VERSION ""

NS_ :

BS_:

BU_: AHCP APM BPCM EAC EBCM ECM ESC HCP OBCM ORC RHSC2

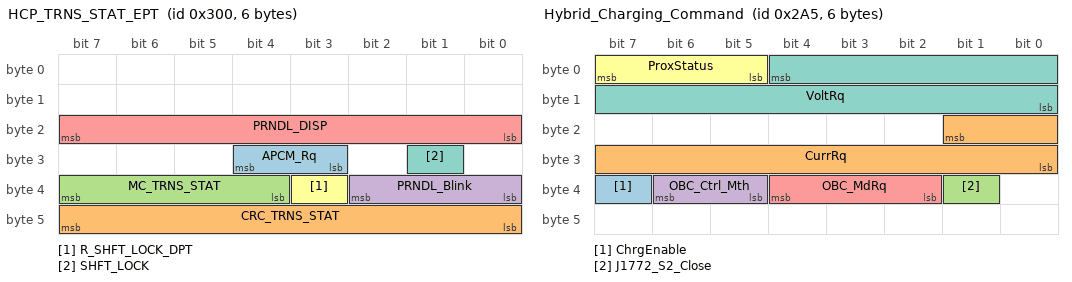
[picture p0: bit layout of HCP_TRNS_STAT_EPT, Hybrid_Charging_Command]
BO_ 768 HCP_TRNS_STAT_EPT: 6 HCP
 SG_ APCM_Rq : 27|2@1+ (1,0) [0|0] ""  RHSC2
 SG_ CRC_TRNS_STAT : 40|8@1+ (1,0) [0|0] ""  RHSC2
 SG_ MC_TRNS_STAT : 36|4@1+ (1,0) [0|15] ""  RHSC2
 SG_ PRNDL_Blink : 32|3@1+ (1,0) [0|0] ""  RHSC2
 SG_ PRNDL_DISP : 16|8@1+ (1,0) [0|0] ""  RHSC2
 SG_ R_SHFT_LOCK_DPT : 35|1@1+ (1,0) [0|0] ""  RHSC2
 SG_ SHFT_LOCK : 25|1@1+ (1,0) [0|0] ""  RHSC2

BO_ 677 Hybrid_Charging_Command: 6 HCP
 SG_ ChrgEnable : 39|1@1+ (1,0) [0|0] ""  OBCM
 SG_ CurrRq : 17|10@0+ (0.1,-32) [-32|31.5] "A"  OBCM
 SG_ J1772_S2_Close : 33|1@1+ (1,0) [0|0] ""  OBCM
 SG_ OBC_Ctrl_Mth : 37|2@1+ (1,0) [0|0] ""  OBCM
 SG_ OBC_MdRq : 34|3@1+ (1,0) [0|0] ""  BPCM,OBCM
 SG_ ProxStatus : 5|3@1+ (1,0) [0|0] ""  BPCM
 SG_ VoltRq : 4|13@0+ (0.1,0) [0|511] "Volts"  OBCM

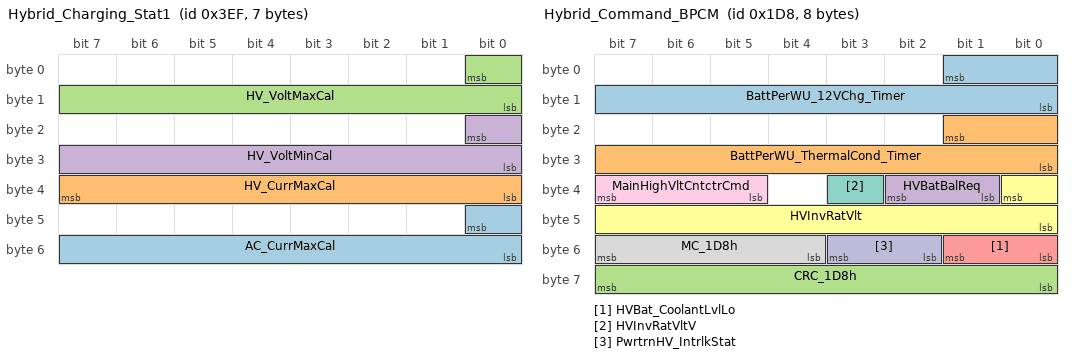
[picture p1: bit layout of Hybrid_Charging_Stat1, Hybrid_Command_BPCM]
BO_ 1007 Hybrid_Charging_Stat1: 7 HCP
 SG_ AC_CurrMaxCal : 40|9@0+ (0.25,-31.5) [-31.5|50] "Amp"  OBCM
 SG_ HV_CurrMaxCal : 32|8@1+ (0.25,-32) [-32|31.5] "Amp"  OBCM
 SG_ HV_VoltMaxCal : 0|9@0+ (1,0) [0|510] "V"  OBCM
 SG_ HV_VoltMinCal : 16|9@0+ (1,0) [0|510] "V"  OBCM

BO_ 472 Hybrid_Command_BPCM: 8 HCP
 SG_ BattPerWU_12VChg_Timer : 1|10@0+ (1,0) [0|1022] "Hours"  BPCM
 SG_ BattPerWU_ThermalCond_Timer : 17|10@0+ (2,0) [0|2044] "min"  BPCM
 SG_ CRC_1D8h : 56|8@1+ (1,0) [0|0] ""  BPCM
 SG_ HVBatBalReq : 33|2@1+ (1,0) [0|0] ""  BPCM
 SG_ HVBat_CoolantLvlLo : 48|2@1+ (1,0) [0|0] ""  BPCM
 SG_ HVInvRatVlt : 32|9@0+ (1,0) [0|510] "V"  BPCM
 SG_ HVInvRatVltV : 35|1@1+ (1,0) [0|0] ""  BPCM
 SG_ MC_1D8h : 52|4@1+ (1,0) [0|0] ""  BPCM
 SG_ MainHighVltCntctrCmd : 37|3@1+ (1,0) [0|0] ""  BPCM,RHSC2
 SG_ PwrtrnHV_IntrlkStat : 50|2@1+ (1,0) [0|0] "" Vector__XXX

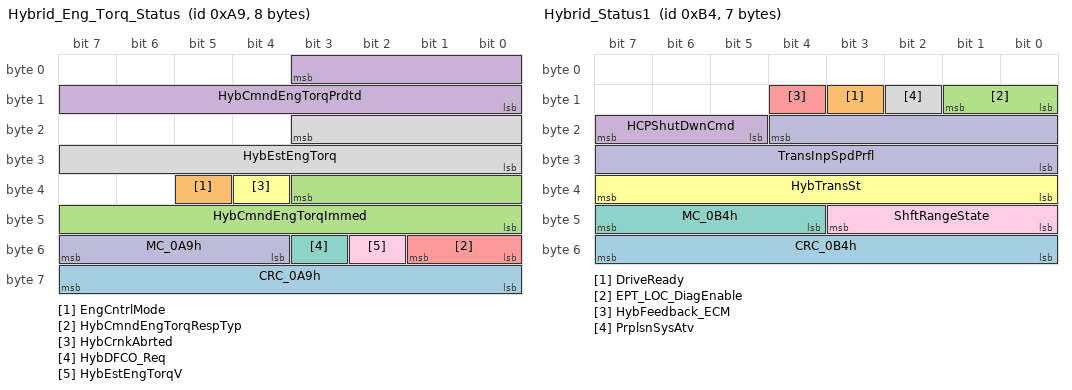
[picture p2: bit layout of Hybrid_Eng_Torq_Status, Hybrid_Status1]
BO_ 169 Hybrid_Eng_Torq_Status: 8 HCP
 SG_ CRC_0A9h : 56|8@1+ (1,0) [0|0] ""  ECM
 SG_ EngCntrlMode : 37|1@1+ (1,0) [0|0] ""  ECM
 SG_ HybCmndEngTorqImmed : 35|12@0+ (0.32,-300.16) [-300.16|1008] "Nm"  ECM
 SG_ HybCmndEngTorqPrdtd : 3|12@0+ (0.32,-300.16) [-300.16|1008] "Nm"  ECM
 SG_ HybCmndEngTorqRespTyp : 48|2@1+ (1,0) [0|0] ""  ECM
 SG_ HybCrnkAbrted : 36|1@1+ (1,0) [0|0] ""  ECM
 SG_ HybDFCO_Req : 51|1@1+ (1,0) [0|0] ""  ECM
 SG_ HybEstEngTorq : 19|12@0+ (0.32,-300.16) [-300.16|1008] "Nm"  ECM
 SG_ HybEstEngTorqV : 50|1@1+ (1,0) [0|0] ""  ECM
 SG_ MC_0A9h : 52|4@1+ (1,0) [0|15] ""  ECM

BO_ 180 Hybrid_Status1: 7 HCP
 SG_ CRC_0B4h : 48|8@1+ (1,0) [0|0] ""  AHCP,APM,BPCM,EAC,EBCM,ECM,ESC,OBCM,ORC,RHSC2
 SG_ DriveReady : 11|1@1+ (1,0) [0|0] ""  BPCM
 SG_ EPT_LOC_DiagEnable : 8|2@1+ (1,0) [0|0] ""  AHCP,APM,BPCM,EAC,OBCM
 SG_ HCPShutDwnCmd : 21|3@1+ (1,0) [0|0] ""  AHCP,APM,BPCM,EAC,EBCM,ECM,ESC,OBCM,ORC,RHSC2
 SG_ HybFeedback_ECM : 12|1@1+ (1,0) [0|0] ""  ECM
 SG_ HybTransSt : 32|8@1+ (1,0) [0|0] ""  ECM
 SG_ MC_0B4h : 44|4@1+ (1,0) [0|15] ""  AHCP,APM,BPCM,EAC,EBCM,ECM,ESC,OBCM,ORC,RHSC2
 SG_ PrplsnSysAtv : 10|1@1+ (1,0) [0|0] ""  AHCP,APM,BPCM,EAC,ECM,OBCM
 SG_ ShftRangeState : 40|4@1+ (1,0) [0|0] ""  ECM
 SG_ TransInpSpdPrfl : 20|13@0+ (1,0) [0|8191] "rpm"  ECM

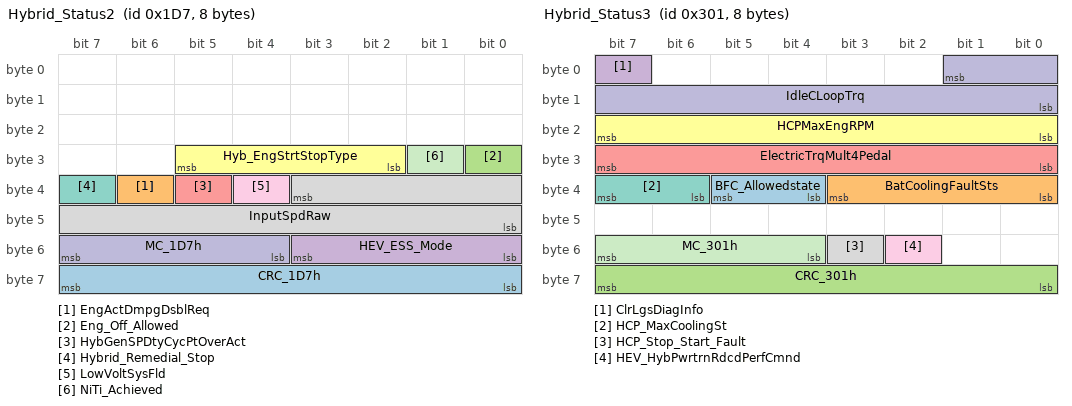
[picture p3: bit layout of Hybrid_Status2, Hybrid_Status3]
BO_ 471 Hybrid_Status2: 8 HCP
 SG_ CRC_1D7h : 56|8@1+ (1,0) [0|0] ""  ECM
 SG_ EngActDmpgDsblReq : 38|1@1+ (1,0) [0|0] ""  ECM
 SG_ Eng_Off_Allowed : 24|1@1+ (1,0) [0|0] ""  ECM
 SG_ HEV_ESS_Mode : 48|4@1+ (1,0) [0|0] ""  ECM
 SG_ HybGenSPDtyCycPtOverAct : 37|1@1+ (1,0) [0|0] ""  ECM
 SG_ Hyb_EngStrtStopType : 26|4@1+ (1,0) [0|0] ""  ECM
 SG_ Hybrid_Remedial_Stop : 39|1@1+ (1,0) [0|0] ""  ECM
 SG_ InputSpdRaw : 35|12@0+ (1,-2048) [-2048|2046] "rpm"  ECM
 SG_ LowVoltSysFld : 36|1@1+ (1,0) [0|0] ""  ECM
 SG_ MC_1D7h : 52|4@1+ (1,0) [0|15] ""  ECM
 SG_ NiTi_Achieved : 25|1@1+ (1,0) [0|0] ""  ECM

BO_ 769 Hybrid_Status3: 8 HCP
 SG_ BFC_Allowedstate : 36|2@1+ (1,0) [0|0] ""  RHSC2
 SG_ BatCoolingFaultSts : 32|4@1+ (1,0) [0|0] ""  RHSC2
 SG_ CRC_301h : 56|8@1+ (1,0) [0|255] ""  ECM,RHSC2
 SG_ ClrLgsDiagInfo : 7|1@1+ (1,0) [0|0] ""  OBCM
 SG_ ElectricTrqMult4Pedal : 24|8@1+ (0.0078125,-0.9921875) [-0.9921875|0.9921875] ""  ECM
 SG_ HCPMaxEngRPM : 16|8@1+ (32,0) [0|8128] "rpm" Vector__XXX
 SG_ HCP_MaxCoolingSt : 38|2@1+ (1,0) [0|0] ""  RHSC2
 SG_ HCP_Stop_Start_Fault : 51|1@1+ (1,0) [0|0] ""  ECM
 SG_ HEV_HybPwrtrnRdcdPerfCmnd : 50|1@1+ (1,0) [0|0] ""  ECM
 SG_ IdleCLoopTrq : 1|10@0+ (0.32,-163.52) [-163.52|163.52] "Nm"  ECM
 SG_ MC_301h : 52|4@1+ (1,0) [0|15] ""  ECM,RHSC2

BO_ 276 IMMO_SOP_REQUEST: 1 HCP
 SG_ IMMO_SOP_REQUEST : 0|1@1+ (1,0) [0|0] ""  ECM

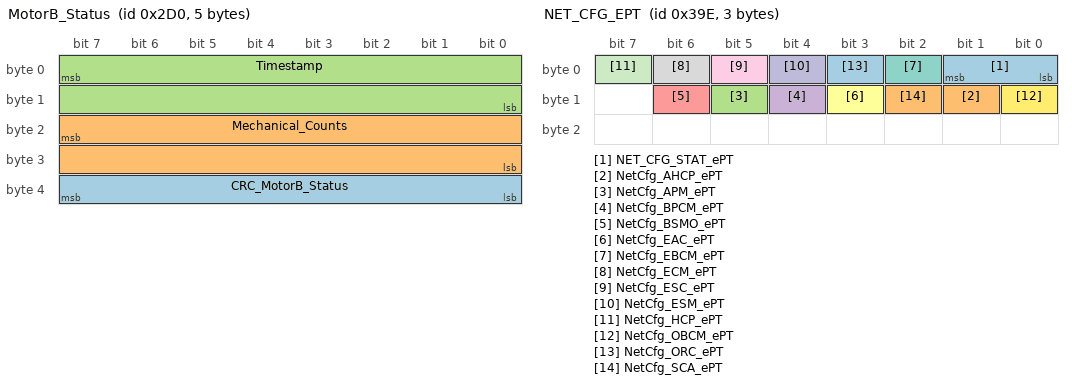
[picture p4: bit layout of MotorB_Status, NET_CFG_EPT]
BO_ 720 MotorB_Status: 5 HCP
 SG_ CRC_MotorB_Status : 32|8@1+ (1,0) [0|0] ""  RHSC2
 SG_ Mechanical_Counts : 23|16@0+ (0.00048828125,0) [0|31.999511719] "Revs"  RHSC2
 SG_ Timestamp : 7|16@0+ (1.969,0) [0|129038.415] "uSec"  RHSC2

BO_ 926 NET_CFG_EPT: 3 HCP
 SG_ NET_CFG_STAT_ePT : 0|2@1+ (1,0) [0|0] ""  AHCP,APM,BPCM,EAC,OBCM
 SG_ NetCfg_AHCP_ePT : 9|1@1+ (1,0) [0|0] "" Vector__XXX
 SG_ NetCfg_APM_ePT : 13|1@1+ (1,0) [0|0] "" Vector__XXX
 SG_ NetCfg_BPCM_ePT : 12|1@1+ (1,0) [0|0] ""  BPCM
 SG_ NetCfg_BSMO_ePT : 14|1@1+ (1,0) [0|0] "" Vector__XXX
 SG_ NetCfg_EAC_ePT : 11|1@1+ (1,0) [0|0] "" Vector__XXX
 SG_ NetCfg_EBCM_ePT : 2|1@1+ (1,0) [0|0] "" Vector__XXX
 SG_ NetCfg_ECM_ePT : 6|1@1+ (1,0) [0|0] "" Vector__XXX
 SG_ NetCfg_ESC_ePT : 5|1@1+ (1,0) [0|0] "" Vector__XXX
 SG_ NetCfg_ESM_ePT : 4|1@1+ (1,0) [0|0] "" Vector__XXX
 SG_ NetCfg_HCP_ePT : 7|1@1+ (1,0) [0|0] "" Vector__XXX
 SG_ NetCfg_OBCM_ePT : 8|1@1+ (1,0) [0|0] "" Vector__XXX
 SG_ NetCfg_ORC_ePT : 3|1@1+ (1,0) [0|0] "" Vector__XXX
 SG_ NetCfg_SCA_ePT : 10|1@1+ (1,0) [0|0] "" Vector__XXX

BO_ 1066 NM_APM: 8 APM
 SG_ NM_APM : 7|64@0+ (1,0) [0|0] ""  OBCM

BO_ 1070 NM_OBCM: 8 OBCM
 SG_ NM_OBCM : 7|64@0+ (1,0) [0|0] ""  APM

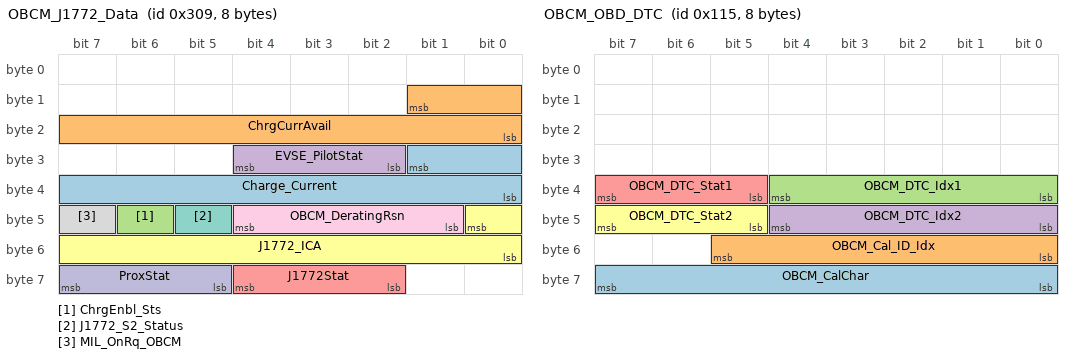
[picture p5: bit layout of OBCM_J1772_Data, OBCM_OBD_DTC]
BO_ 777 OBCM_J1772_Data: 8 OBCM
 SG_ Charge_Current : 25|10@0+ (0.1,0) [0|63.5] "Amp"  HCP
 SG_ ChrgCurrAvail : 9|10@0+ (0.1,0) [0|63.5] "Amp"  HCP
 SG_ ChrgEnbl_Sts : 46|1@1+ (1,0) [0|0] ""  HCP
 SG_ EVSE_PilotStat : 26|3@1+ (1,0) [0|0] ""  HCP
 SG_ J1772Stat : 58|3@1+ (1,0) [0|0] ""  HCP
 SG_ J1772_ICA : 40|9@0+ (1,0) [0|300] "Amp"  HCP
 SG_ J1772_S2_Status : 45|1@1+ (1,0) [0|0] ""  HCP
 SG_ MIL_OnRq_OBCM : 47|1@1+ (1,0) [0|0] ""  ECM
 SG_ OBCM_DeratingRsn : 41|4@1+ (1,0) [0|0] ""  HCP
 SG_ ProxStat : 61|3@1+ (1,0) [0|0] ""  HCP

BO_ 277 OBCM_OBD_DTC: 8 OBCM
 SG_ OBCM_CalChar : 56|8@1+ (1,0) [0|254] ""  HCP
 SG_ OBCM_Cal_ID_Idx : 48|6@1+ (1,0) [0|62] ""  HCP
 SG_ OBCM_DTC_Idx1 : 32|5@1+ (1,0) [1|31] ""  HCP
 SG_ OBCM_DTC_Idx2 : 40|5@1+ (1,0) [1|31] ""  HCP
 SG_ OBCM_DTC_Stat1 : 37|3@1+ (1,0) [0|0] ""  HCP
 SG_ OBCM_DTC_Stat2 : 45|3@1+ (1,0) [0|0] ""  HCP

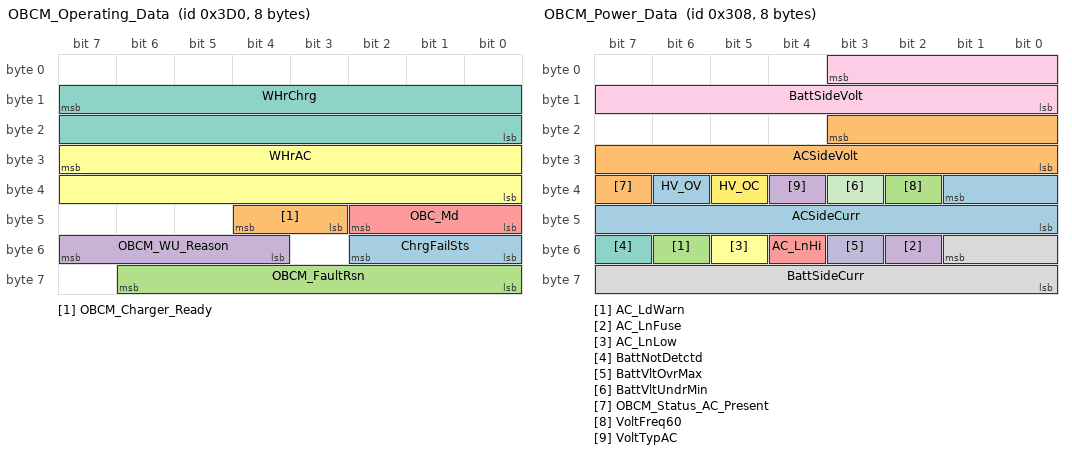
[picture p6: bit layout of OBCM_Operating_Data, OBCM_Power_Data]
BO_ 976 OBCM_Operating_Data: 8 OBCM
 SG_ ChrgFailSts : 48|3@1+ (1,0) [0|0] ""  HCP
 SG_ OBCM_Charger_Ready : 43|2@1+ (1,0) [0|0] ""  HCP
 SG_ OBCM_FaultRsn : 56|7@1+ (1,0) [0|0] ""  HCP
 SG_ OBCM_WU_Reason : 52|4@1+ (1,0) [0|0] ""  HCP
 SG_ OBC_Md : 40|3@1+ (1,0) [0|0] ""  HCP
 SG_ WHrAC : 31|16@0+ (1,-32767) [-32767|32767] "WHr"  HCP
 SG_ WHrChrg : 15|16@0+ (1,0) [0|65534] "WHr"  HCP

BO_ 776 OBCM_Power_Data: 8 OBCM
 SG_ ACSideCurr : 33|10@0+ (0.1,-50) [-50|50] "Amp"  HCP
 SG_ ACSideVolt : 19|12@0+ (0.1,0) [0|300] "Volts"  HCP
 SG_ AC_LdWarn : 54|1@1+ (1,0) [0|0] ""  HCP
 SG_ AC_LnFuse : 50|1@1+ (1,0) [0|0] ""  HCP
 SG_ AC_LnHi : 52|1@1+ (1,0) [0|0] ""  HCP
 SG_ AC_LnLow : 53|1@1+ (1,0) [0|0] ""  HCP
 SG_ BattNotDetctd : 55|1@1+ (1,0) [0|0] ""  HCP
 SG_ BattSideCurr : 49|10@0+ (0.1,-50) [-50|50] "Amp"  HCP
 SG_ BattSideVolt : 3|12@0+ (0.1,180) [180|511] "Volts"  HCP
 SG_ BattVltOvrMax : 51|1@1+ (1,0) [0|0] ""  HCP
 SG_ BattVltUndrMin : 35|1@1+ (1,0) [0|0] ""  HCP
 SG_ HV_OC : 37|1@1+ (1,0) [0|0] ""  HCP
 SG_ HV_OV : 38|1@1+ (1,0) [0|0] ""  HCP
 SG_ OBCM_Status_AC_Present : 39|1@1+ (1,0) [0|0] ""  HCP
 SG_ VoltFreq60 : 34|1@1+ (1,0) [0|0] ""  HCP
 SG_ VoltTypAC : 36|1@1+ (1,0) [0|0] ""  HCP

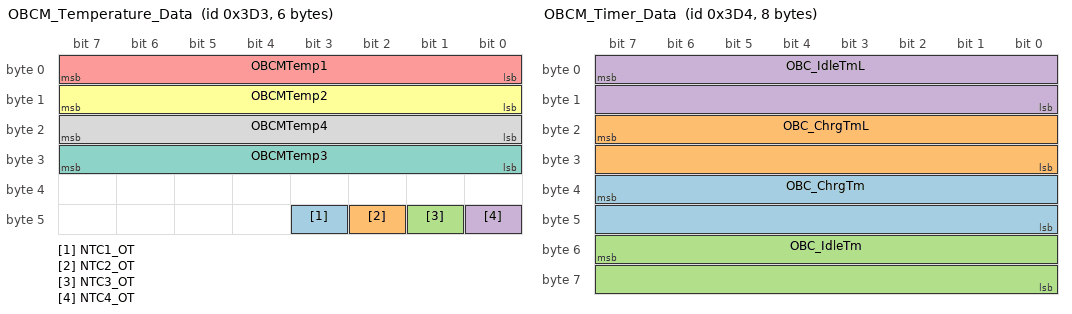
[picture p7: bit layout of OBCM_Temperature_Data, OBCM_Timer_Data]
BO_ 979 OBCM_Temperature_Data: 6 OBCM
 SG_ NTC1_OT : 43|1@1+ (1,0) [0|0] ""  HCP
 SG_ NTC2_OT : 42|1@1+ (1,0) [0|0] ""  HCP
 SG_ NTC3_OT : 41|1@1+ (1,0) [0|0] ""  HCP
 SG_ NTC4_OT : 40|1@1+ (1,0) [0|0] ""  HCP
 SG_ OBCMTemp1 : 0|8@1+ (1,-40) [-40|214] "°C"  HCP
 SG_ OBCMTemp2 : 8|8@1+ (1,-40) [-40|214] "°C"  HCP
 SG_ OBCMTemp3 : 24|8@1+ (1,-40) [-40|214] "°C"  HCP
 SG_ OBCMTemp4 : 16|8@1+ (1,-40) [-40|214] "°C"  HCP

BO_ 980 OBCM_Timer_Data: 8 OBCM
 SG_ OBC_ChrgTm : 39|16@0+ (3,0) [0|196602] "sec"  HCP
 SG_ OBC_ChrgTmL : 23|16@0+ (1,0) [0|65534] "min"  HCP
 SG_ OBC_IdleTm : 55|16@0+ (3,0) [0|196602] "sec"  HCP
 SG_ OBC_IdleTmL : 7|16@0+ (1,0) [0|65534] "min"  HCP

BO_ 466 ORC_A2: 2 HCP
 SG_ IMPACT_X : 15|1@1+ (1,0) [0|0] ""  APM,BPCM,EAC,OBCM
 SG_ Impact_Tgl : 7|1@1+ (1,0) [0|0] ""  APM,BPCM,EAC,OBCM

BO_ 467 ORC_A2a: 2 ORC
 SG_ IMPACT_X_ePT : 15|1@1+ (1,0) [0|0] ""  AHCP,APM,BPCM,EAC,HCP,OBCM,RHSC2
 SG_ Impact_Tgl_ePT : 7|1@1+ (1,0) [0|0] ""  AHCP,APM,BPCM,EAC,HCP,OBCM,RHSC2

BO_ 469 ORC_A4: 8 HCP
 SG_ ORC_Health : 23|1@1+ (1,0) [0|0] ""  APM,BPCM,EAC,OBCM

BO_ 470 ORC_A4a: 8 ORC
 SG_ ORC_Health_ePT : 23|1@1+ (1,0) [0|0] ""  APM,BPCM,EAC,HCP,OBCM,RHSC2

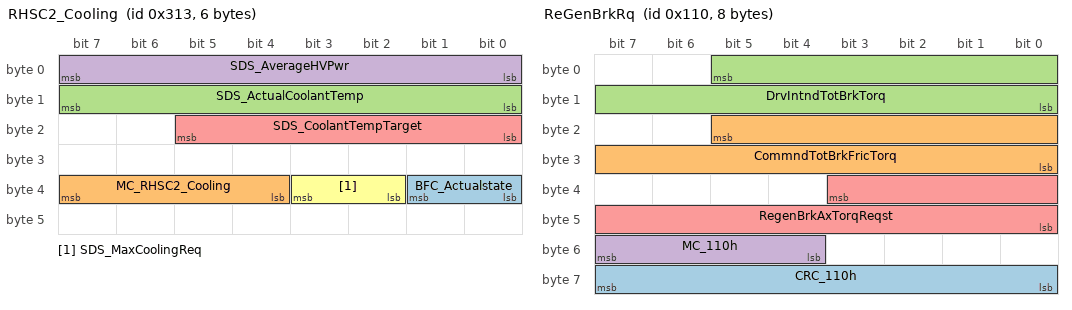
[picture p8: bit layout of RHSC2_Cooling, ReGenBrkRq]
BO_ 787 RHSC2_Cooling: 6 RHSC2
 SG_ BFC_Actualstate : 32|2@1+ (1,0) [0|3] ""  HCP
 SG_ MC_RHSC2_Cooling : 36|4@1+ (1,0) [0|15] ""  HCP
 SG_ SDS_ActualCoolantTemp : 8|8@1+ (1,-40) [-40|214] "degC"  HCP
 SG_ SDS_AverageHVPwr : 0|8@1+ (20,0) [0|5000] "W"  HCP
 SG_ SDS_CoolantTempTarget : 16|6@1+ (1,0) [0|40] "degC"  HCP
 SG_ SDS_MaxCoolingReq : 34|2@1+ (1,0) [0|3] ""  HCP

BO_ 272 ReGenBrkRq: 8 ESC
 SG_ CRC_110h : 56|8@1+ (1,0) [0|0] ""  EBCM,ECM,HCP
 SG_ CommndTotBrkFricTorq : 21|14@0+ (2,0) [0|32764] "Nm"  HCP
 SG_ DrvIntndTotBrkTorq : 5|14@0+ (2,0) [0|32764] "Nm"  EBCM,ECM,HCP
 SG_ MC_110h : 52|4@1+ (1,0) [0|15] ""  EBCM,ECM,HCP
 SG_ RegenBrkAxTorqReqst : 35|12@0+ (2,0) [0|8188] "Nm"  HCP

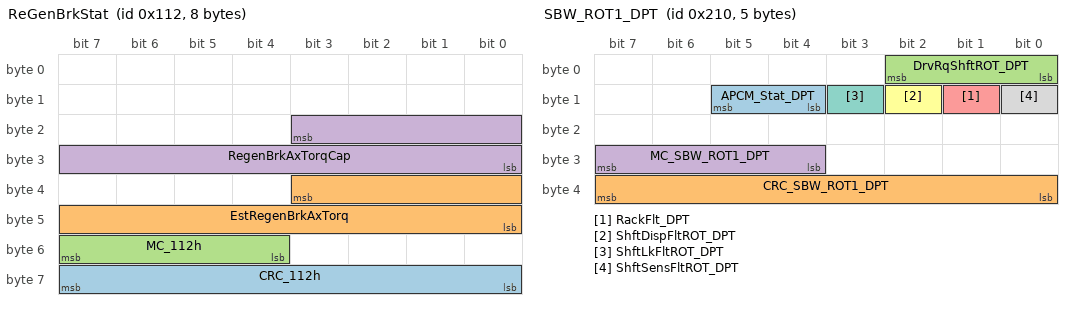
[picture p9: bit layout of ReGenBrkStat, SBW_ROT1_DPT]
BO_ 274 ReGenBrkStat: 8 HCP
 SG_ CRC_112h : 56|8@1+ (1,0) [0|255] ""  ESC
 SG_ EstRegenBrkAxTorq : 35|12@0+ (2,0) [0|8188] "Nm"  ESC,ORC
 SG_ MC_112h : 52|4@1+ (1,0) [0|15] ""  ESC
 SG_ RegenBrkAxTorqCap : 19|12@0+ (2,0) [0|8188] "Nm"  ESC

BO_ 528 SBW_ROT1_DPT: 5 RHSC2
 SG_ APCM_Stat_DPT : 12|2@1+ (1,0) [0|0] ""  HCP
 SG_ CRC_SBW_ROT1_DPT : 32|8@1+ (1,0) [0|0] ""  BPCM,EBCM,ESC,HCP
 SG_ DrvRqShftROT_DPT : 0|3@1+ (1,0) [0|0] ""  BPCM,EBCM,ESC,HCP
 SG_ MC_SBW_ROT1_DPT : 28|4@1+ (1,0) [0|15] ""  BPCM,EBCM,ESC,HCP
 SG_ RackFlt_DPT : 9|1@1+ (1,0) [0|0] ""  HCP
 SG_ ShftDispFltROT_DPT : 10|1@1+ (1,0) [0|0] ""  HCP
 SG_ ShftLkFltROT_DPT : 11|1@1+ (1,0) [0|0] ""  HCP
 SG_ ShftSensFltROT_DPT : 8|1@1+ (1,0) [0|0] ""  HCP

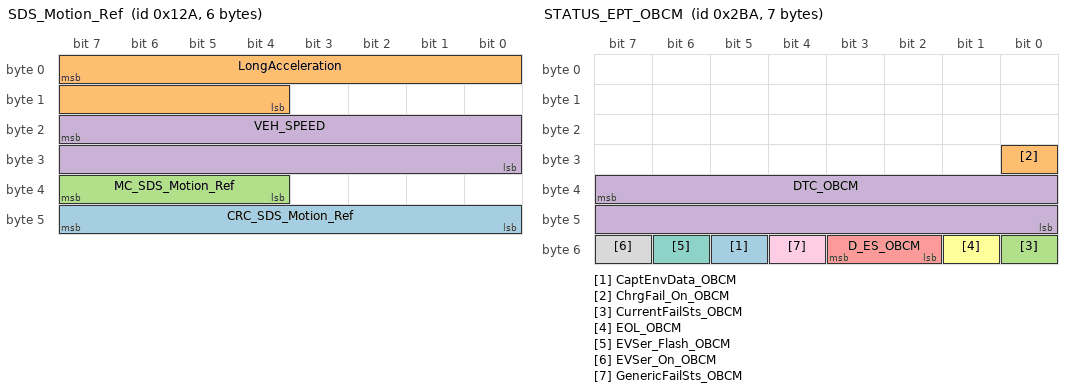
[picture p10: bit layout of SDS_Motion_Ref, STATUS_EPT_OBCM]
BO_ 298 SDS_Motion_Ref: 6 RHSC2
 SG_ CRC_SDS_Motion_Ref : 40|8@1+ (1,0) [0|0] ""  EBCM
 SG_ LongAcceleration : 7|12@0+ (0.02,-40.96) [-40.96|40.92] "m/s²"  EBCM
 SG_ MC_SDS_Motion_Ref : 36|4@1+ (1,0) [0|15] ""  EBCM
 SG_ VEH_SPEED : 23|16@0+ (0.0078125,0) [0|511.984375] "km/h"  EBCM

BO_ 1599 SD_RS_BPCM: 8 BPCM
 SG_ SD_RS_BPCM : 7|64@0+ (1,0) [0|0] ""  HCP

BO_ 691 STATUS_EPT_EAC: 3 EAC
 SG_ EOL_EAC : 20|1@1+ (1,0) [0|0] ""  HCP

BO_ 698 STATUS_EPT_OBCM: 7 OBCM
 SG_ CaptEnvData_OBCM : 53|1@1+ (1,0) [0|0] ""  HCP
 SG_ ChrgFail_On_OBCM : 24|1@1+ (1,0) [0|0] ""  HCP
 SG_ CurrentFailSts_OBCM : 48|1@1+ (1,0) [0|0] ""  HCP
 SG_ DTC_OBCM : 39|16@0+ (1,0) [0|65534] ""  HCP
 SG_ D_ES_OBCM : 50|2@1+ (1,0) [0|0] ""  HCP
 SG_ EOL_OBCM : 49|1@1+ (1,0) [0|0] ""  HCP
 SG_ EVSer_Flash_OBCM : 54|1@1+ (1,0) [0|0] ""  HCP
 SG_ EVSer_On_OBCM : 55|1@1+ (1,0) [0|0] ""  HCP
 SG_ GenericFailSts_OBCM : 52|1@1+ (1,0) [0|0] ""  HCP

BO_ 992 VIN: 8 ECM
 SG_ VIN_DATA : 15|56@0+ (1,0) [0|0] ""  AHCP,APM,BPCM,EAC,OBCM
 SG_ VIN_MSG : 0|2@1+ (1,0) [0|0] ""  AHCP,APM,BPCM,EAC,OBCM

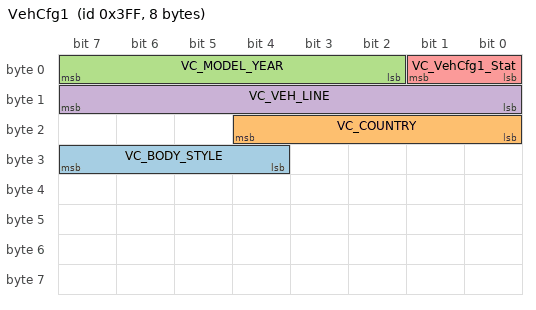
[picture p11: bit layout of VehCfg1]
BO_ 1023 VehCfg1: 8 HCP
 SG_ VC_BODY_STYLE : 28|4@1+ (1,0) [0|0] ""  AHCP,APM,BPCM,EAC,OBCM
 SG_ VC_COUNTRY : 16|5@1+ (1,0) [0|0] ""  AHCP,APM,BPCM,EAC,OBCM
 SG_ VC_MODEL_YEAR : 2|6@1+ (1,2000) [2000|2062] "model-year"  AHCP,APM,BPCM,EAC,OBCM
 SG_ VC_VEH_LINE : 8|8@1+ (1,0) [0|0] ""  AHCP,APM,BPCM,EAC,OBCM
 SG_ VC_VehCfg1_Stat : 0|2@1+ (1,0) [0|0] ""  AHCP,APM,BPCM,EAC,OBCM

CM_ SG_ 768 APCM_Rq "Auto position correction mode request";
CM_ SG_ 768 CRC_TRNS_STAT "CRC-checksum byte 1 to 7 according to SAE J1850";
CM_ SG_ 768 MC_TRNS_STAT "Message counter";
CM_ SG_ 768 PRNDL_Blink "Request gear shift display indicator blink";
CM_ SG_ 768 PRNDL_DISP "PRNDL display request";
CM_ SG_ 768 R_SHFT_LOCK_DPT "Shiftlock for reverse; locked = [1]";
CM_ SG_ 768 SHFT_LOCK "Shiftlock state locked; false = [1]";
CM_ SG_ 677 ChrgEnable "Charge Enable";
CM_ SG_ 677 CurrRq "HCP current request to the on board charger";
CM_ SG_ 677 J1772_S2_Close "J 1772 Close command";
CM_ SG_ 677 OBC_Ctrl_Mth "Onboard charger commanded control method";
CM_ SG_ 677 OBC_MdRq "Onboard charger mode request";
CM_ SG_ 677 ProxStatus "Prox status";
CM_ SG_ 677 VoltRq "High Voltage Battery Voltage";
CM_ SG_ 1007 AC_CurrMaxCal "Maximum allowable AC current";
CM_ SG_ 1007 HV_CurrMaxCal "Maximum allowable HV battery current";
CM_ SG_ 1007 HV_VoltMaxCal "Maximum allowable HV battery voltage";
CM_ SG_ 1007 HV_VoltMinCal "Minimum allowable HV battery voltage";
CM_ SG_ 472 BattPerWU_12VChg_Timer "Timer for 12V Charging Periodic Wakeup";
CM_ SG_ 472 BattPerWU_ThermalCond_Timer "Timer for HV Battery Thermal conditioning wakeup";
CM_ SG_ 472 CRC_1D8h "CRC-checksum byte 1 to 7 according to SAE J1850";
CM_ SG_ 472 HVBatBalReq "High Voltage Balance request";
CM_ SG_ 472 HVBat_CoolantLvlLo "Battery coolant level low";
CM_ SG_ 472 HVInvRatVlt "??";
CM_ SG_ 472 HVInvRatVltV ".";
CM_ SG_ 472 MC_1D8h "Message counter";
CM_ SG_ 472 MainHighVltCntctrCmd "High voltage battery contactor command";
CM_ SG_ 472 PwrtrnHV_IntrlkStat "Powertrain High voltage interlock state";
CM_ SG_ 169 CRC_0A9h "CRC-Checksum Byte 1 - 7 according to SAE J1850";
CM_ SG_ 169 EngCntrlMode "EngCntrlMode, [0] = Torque Mode, [1] = Speed Mode";
CM_ SG_ 169 HybCmndEngTorqImmed "Hybrid commanded engine torque immediate torque (fast path)";
CM_ SG_ 169 HybCmndEngTorqPrdtd "Hybrid commanded engine torque predicted torque (slow path).";
CM_ SG_ 169 HybCmndEngTorqRespTyp "Hybrid Commanded Engine Torque Response Type";
CM_ SG_ 169 HybCrnkAbrted "Hybrid Crank Aborted";
CM_ SG_ 169 HybDFCO_Req "Hybrid deceleration fuel cut off request";
CM_ SG_ 169 HybEstEngTorq "Hybrid estimated engine torque";
CM_ SG_ 169 HybEstEngTorqV "Hybrid estimated engine torque validity. 0 = Valid, 1 = Invalid";
CM_ SG_ 169 MC_0A9h "Message counter   0A9h";
CM_ SG_ 180 CRC_0B4h "CRC-checksum byte 1 to 7 according to SAE J1850";
CM_ SG_ 180 DriveReady "Ready to Drive, [1] = Vehicle is allowed to shift out of park or neutral";
CM_ SG_ 180 EPT_LOC_DiagEnable ".";
CM_ SG_ 180 HCPShutDwnCmd "HCP System Shutdown Command";
CM_ SG_ 180 HybFeedback_ECM "Indication that the HCP is receiving valid data from the ECM. 0 - False; 1 - True.";
CM_ SG_ 180 HybTransSt "Hybrid transmission state";
CM_ SG_ 180 MC_0B4h "Message counter 0B4h";
CM_ SG_ 180 PrplsnSysAtv "Propulsion system active, [1] = active";
CM_ SG_ 180 ShftRangeState "Shift range state";
CM_ SG_ 180 TransInpSpdPrfl "Transmission Input Speed Profile";
CM_ SG_ 471 CRC_1D7h "CRC-checksum byte 1 to 7 according to SAE J1850";
CM_ SG_ 471 EngActDmpgDsblReq "Engine Active Damping Disable Request";
CM_ SG_ 471 Eng_Off_Allowed "Engine Stop Allowed. 0 = ENG_OFF_NOT_ALLOWED, 1 = ENG_OFF_ALLOWED";
CM_ SG_ 471 HEV_ESS_Mode "Engine start stop information:  engine start stop mode";
CM_ SG_ 471 HybGenSPDtyCycPtOverAct "Hybrid generator setpoint duty cycle powertrain override active";
CM_ SG_ 471 Hyb_EngStrtStopType "Current start/stop type.";
CM_ SG_ 471 Hybrid_Remedial_Stop "Engine Start Allowed.0 = ENG_ON_ALLOWED, 1 = ENG_ON_NOT_ALLOW";
CM_ SG_ 471 InputSpdRaw "Trans input speed from HCP.";
CM_ SG_ 471 LowVoltSysFld "Low voltage system failed";
CM_ SG_ 471 MC_1D7h "Message counter";
CM_ SG_ 471 NiTi_Achieved "NiTi is achieved by HCP; True = [1]";
CM_ SG_ 769 BFC_Allowedstate "BFC allowed state";
CM_ SG_ 769 BatCoolingFaultSts "Fault conditions to disable battery loop cooling";
CM_ SG_ 769 CRC_301h "CRC-Checksum Byte 1 - 7 according to SAE J1850";
CM_ SG_ 769 ClrLgsDiagInfo "Clear Legislated Diagnostic Information";
CM_ SG_ 769 ElectricTrqMult4Pedal "Adjustment factor for elctric components of pedal max torque.";
CM_ SG_ 769 HCPMaxEngRPM "Engine rev limit due to HCP/MGU limits";
CM_ SG_ 769 HCP_MaxCoolingSt "HCP state showing that maximum cooling is being delivered";
CM_ SG_ 769 HCP_Stop_Start_Fault "Stop/Start Fault, [1] = Active";
CM_ SG_ 769 HEV_HybPwrtrnRdcdPerfCmnd "Driver torque request modifier due to system remedial acion";
CM_ SG_ 769 IdleCLoopTrq "Electric motor PID torque to maintain idle speed.";
CM_ SG_ 769 MC_301h "Message counter 310h";
CM_ SG_ 276 IMMO_SOP_REQUEST "Signals ECM to initiate Immobilizer handshake.";
CM_ SG_ 720 CRC_MotorB_Status "CRC-Checksum Byte 1 - 4 plus message ID according to SAE J1850";
CM_ SG_ 720 Mechanical_Counts "Accumulated for odometry sensor output for the angular position of Motor B. 2,048 counts = 1 full rotation of eMotor Bl. 32 rotations total. This signal should roll over from all ones to all zeros when moving forward and vice versa in reverse gear.";
CM_ SG_ 720 Timestamp "Timestamp for redundant odometer. Each count is 1.969µs = 512 counts of the MM Cobra micro 32-bit timer. This signal should roll over from all ones to all zeros in normal operation.";
CM_ SG_ 926 NET_CFG_STAT_ePT "Network configuration status.";
CM_ SG_ 926 NetCfg_AHCP_ePT "Transmission Control Processor (1=present)";
CM_ SG_ 926 NetCfg_APM_ePT "Auxiliary Power Module (1=present)";
CM_ SG_ 926 NetCfg_BPCM_ePT "Battery Pack Control Module (1=present)";
CM_ SG_ 926 NetCfg_BSMO_ePT "Brake System Module - OBD (1=present)";
CM_ SG_ 926 NetCfg_EAC_ePT "Electric AC Compressor (1=present)";
CM_ SG_ 926 NetCfg_EBCM_ePT "Electronic Boost Control Module (1=present)";
CM_ SG_ 926 NetCfg_ECM_ePT "Engine Controller Module (1=present)";
CM_ SG_ 926 NetCfg_ESC_ePT "Electronic Stability Control (1=present)";
CM_ SG_ 926 NetCfg_ESM_ePT "Electronic Shifter Module (1=present)";
CM_ SG_ 926 NetCfg_HCP_ePT "Hybrid Control Processor (1=present)";
CM_ SG_ 926 NetCfg_OBCM_ePT "On Board Charging Module. 1=present";
CM_ SG_ 926 NetCfg_ORC_ePT "Occupant Restraint Controller (1=present)";
CM_ SG_ 926 NetCfg_SCA_ePT "Smart Cluch Actuator (1=present)";
CM_ SG_ 1066 NM_APM "Network management only for ePT bus.";
CM_ SG_ 1070 NM_OBCM "Network management only for ePT bus.";
CM_ SG_ 777 Charge_Current ".";
CM_ SG_ 777 ChrgCurrAvail ".";
CM_ SG_ 777 ChrgEnbl_Sts ".";
CM_ SG_ 777 EVSE_PilotStat "EVSE pilot status";
CM_ SG_ 777 J1772Stat "J1772 status";
CM_ SG_ 777 J1772_ICA "J1772 input curent available";
CM_ SG_ 777 J1772_S2_Status "0 = Open, 1 = Closed";
CM_ SG_ 777 MIL_OnRq_OBCM "MIL on request from the OBCM";
CM_ SG_ 777 OBCM_DeratingRsn "OBCM Derating Reason";
CM_ SG_ 777 ProxStat "Prox status";
CM_ SG_ 277 OBCM_CalChar "OBCM Cal ID & CVN";
CM_ SG_ 277 OBCM_Cal_ID_Idx "OBCM calibration ID index";
CM_ SG_ 277 OBCM_DTC_Idx1 "OBCM diagnostic trouble code index 1";
CM_ SG_ 277 OBCM_DTC_Idx2 "OBCM diagnostic trouble code index 2";
CM_ SG_ 277 OBCM_DTC_Stat1 "OBCM diagnostic trouble code status 1";
CM_ SG_ 277 OBCM_DTC_Stat2 "OBCM diagnostic trouble code status 2";
CM_ SG_ 976 ChrgFailSts "OBCM charging fault status";
CM_ SG_ 976 OBCM_Charger_Ready "OBCM emergency stop or over temperature";
CM_ SG_ 976 OBCM_FaultRsn "OBCM Fault Reason";
CM_ SG_ 976 OBCM_WU_Reason "OBCM wakeup status";
CM_ SG_ 976 OBC_Md "Onboard charger mode";
CM_ SG_ 976 WHrAC "AC Power in Watts";
CM_ SG_ 976 WHrChrg "Watt-hours of charge";
CM_ SG_ 776 ACSideCurr "AC side current";
CM_ SG_ 776 ACSideVolt "AC side voltage";
CM_ SG_ 776 AC_LdWarn "AC load high warning";
CM_ SG_ 776 AC_LnFuse "AC line fuse blown";
CM_ SG_ 776 AC_LnHi "AC line voltage too high";
CM_ SG_ 776 AC_LnLow "AC line voltage too low";
CM_ SG_ 776 BattNotDetctd "Battery not detected (fully disabled)";
CM_ SG_ 776 BattSideCurr "Battery side current";
CM_ SG_ 776 BattSideVolt "Battery side voltage";
CM_ SG_ 776 BattVltOvrMax "Battery voltage over maximum allowed (charge disabled)";
CM_ SG_ 776 BattVltUndrMin "Battery voltage under minimum allowed (discharge disabled)";
CM_ SG_ 776 HV_OC "High voltage over current";
CM_ SG_ 776 HV_OV "High voltage - over voltage";
CM_ SG_ 776 OBCM_Status_AC_Present ".";
CM_ SG_ 776 VoltFreq60 "Input voltage frrequency is 60 hz (50 hz - [0], 60 hz - [1])";
CM_ SG_ 776 VoltTypAC "Input voltage is a/c (dc - [0], ac - [1])";
CM_ SG_ 979 NTC1_OT ".";
CM_ SG_ 979 NTC2_OT ".";
CM_ SG_ 979 NTC3_OT ".";
CM_ SG_ 979 NTC4_OT ".";
CM_ SG_ 979 OBCMTemp1 "OBCM temperature sensor 1";
CM_ SG_ 979 OBCMTemp2 "OBCM temperature sensor 2";
CM_ SG_ 979 OBCMTemp3 "OBCM temperature sensor 4";
CM_ SG_ 979 OBCMTemp4 "OBCM temperature sensor 3";
CM_ SG_ 980 OBC_ChrgTm "On board charge time";
CM_ SG_ 980 OBC_ChrgTmL "On board charge time - long";
CM_ SG_ 980 OBC_IdleTm "On board charger idle time";
CM_ SG_ 980 OBC_IdleTmL "On board charger idle time - long";
CM_ SG_ 466 IMPACT_X "Any impact event; actuate = [1]; do_not_actuate = [0]";
CM_ SG_ 466 Impact_Tgl "Toggle bit for all impact events; See Signal Description Document";
CM_ SG_ 467 IMPACT_X_ePT "Any impact event; actuate = [1]; do_not_actuate = [0]";
CM_ SG_ 467 Impact_Tgl_ePT "Toggle bit for all impact events; actuate = [1]; do_not_actuate = [0]";
CM_ SG_ 469 ORC_Health "ORC alive and active; True = [1]";
CM_ SG_ 470 ORC_Health_ePT "ORC alive and active; True = [1]";
CM_ SG_ 787 BFC_Actualstate "BFC actual state";
CM_ SG_ 787 MC_RHSC2_Cooling "Message counter 311h";
CM_ SG_ 787 SDS_ActualCoolantTemp "Battery Coolant loop actual inlet temperature to SDS";
CM_ SG_ 787 SDS_AverageHVPwr "Average HV power used by SDS over 100ms";
CM_ SG_ 787 SDS_CoolantTempTarget "Battery Coolant loop target inlet temperature to SDS";
CM_ SG_ 787 SDS_MaxCoolingReq "SDS maximum cooling request";
CM_ SG_ 272 CRC_110h "CRC-Checksum Byte 1 - 7 according to SAE J1850";
CM_ SG_ 272 CommndTotBrkFricTorq "Commanded Total Brake Friction Torque";
CM_ SG_ 272 DrvIntndTotBrkTorq "Driver Intended Total Brake Torque";
CM_ SG_ 272 MC_110h "MSG counter for 110h.";
CM_ SG_ 272 RegenBrkAxTorqReqst "Regenerative Braking Axle Torque Request";
CM_ SG_ 274 CRC_112h "CRC-Checksum Byte 1 - 7 according to SAE J1850";
CM_ SG_ 274 EstRegenBrkAxTorq "Estimate Regenerative Braking Axle Torque";
CM_ SG_ 274 MC_112h "Message counter";
CM_ SG_ 274 RegenBrkAxTorqCap "Regenerative Braking Axle Torque Capability";
CM_ SG_ 528 APCM_Stat_DPT "Auto position correction mode status";
CM_ SG_ 528 CRC_SBW_ROT1_DPT "CRC-checksum byte 1 to 4 according to SAE J1850";
CM_ SG_ 528 DrvRqShftROT_DPT "Driver requested gear shift position";
CM_ SG_ 528 MC_SBW_ROT1_DPT "Message counter";
CM_ SG_ 528 RackFlt_DPT "Rack / detent sensor fault, 1=fault";
CM_ SG_ 528 ShftDispFltROT_DPT "Gear shifter display/trigger fault status - rotary shifter, 1=fault";
CM_ SG_ 528 ShftLkFltROT_DPT "Shift lock fault - rotary shifter, 1=fault";
CM_ SG_ 528 ShftSensFltROT_DPT "Shift sensor single fault - rotary shifter, 1=fault";
CM_ SG_ 298 CRC_SDS_Motion_Ref "CRC-checksum byte 1 to 4 according to SAE J1850";
CM_ SG_ 298 LongAcceleration "Raw longitudinal acceleration";
CM_ SG_ 298 MC_SDS_Motion_Ref "Message counter";
CM_ SG_ 298 VEH_SPEED "Vehicle speed";
CM_ SG_ 1599 SD_RS_BPCM "Response on Event - light";
CM_ SG_ 691 EOL_EAC "0x0 No EOL programming needed, 0x1 EOL programming needed";
CM_ SG_ 698 CaptEnvData_OBCM "Capture Environmental Data";
CM_ SG_ 698 ChrgFail_On_OBCM "0 = Open, 1 = Off/SNA";
CM_ SG_ 698 CurrentFailSts_OBCM ".";
CM_ SG_ 698 DTC_OBCM ".";
CM_ SG_ 698 D_ES_OBCM ".";
CM_ SG_ 698 EOL_OBCM ".";
CM_ SG_ 698 EVSer_Flash_OBCM "Ev service LIGHT flash from OBCM";
CM_ SG_ 698 EVSer_On_OBCM "Ev service On request from OBCM";
CM_ SG_ 698 GenericFailSts_OBCM ".";
CM_ SG_ 992 VIN_DATA "VIN Digits (8 bit ascii encoded) - see Signal Description Doc for details";
CM_ SG_ 992 VIN_MSG "VIN Message Information";
CM_ SG_ 1023 VC_BODY_STYLE "Body style";
CM_ SG_ 1023 VC_COUNTRY "Country Code";
CM_ SG_ 1023 VC_MODEL_YEAR "Model year";
CM_ SG_ 1023 VC_VEH_LINE "Vehicle line";
CM_ SG_ 1023 VC_VehCfg1_Stat "Configuration messages status 1";
BA_DEF_ BO_  "App-Botschaft" ENUM  "nein","ja";
BA_DEF_ BO_  "CanMsgMinLen" INT 0 8;
BA_DEF_ BO_  "DiagRequest" ENUM  "nein","ja";
BA_DEF_ BO_  "DiagResponse" ENUM  "nein","ja";
BA_DEF_ BO_  "DiagState" ENUM  "nein","ja";
BA_DEF_ BO_  "GenMsgCycleTime" INT 0 65535;
BA_DEF_ BO_  "GenMsgCycleTimeActive" INT 0 65535;
BA_DEF_ BO_  "GenMsgDelayTime" INT 0 65535;
BA_DEF_ BO_  "GenMsgNrOfRepetitions" INT 0 65535;
BA_DEF_ BO_  "GenMsgSendType" ENUM  "cyclicX","spontanX","cyclicIfActiveX","spontanWithDelay","cyclicAndSpontanX","cyclicAndSpontanWithDelay","spontanWithRepitition","cyclicIfActiveAndSpontanWD","cyclicIfActiveFast","cyclicWithRepeatOnDemand","none";
BA_DEF_ BO_  "GenMsgStartDelayTime" INT 0 65535;
BA_DEF_ BO_  "GenMsgStartValue" STRING ;
BA_DEF_ BO_  "NWM-Botschaft" ENUM  "nein","ja";
BA_DEF_ BO_  "TpTxIndex" INT 0 99;
BA_DEF_ SG_  "FlexKomComment" STRING ;
BA_DEF_ SG_  "FlexKomIsMotorola" ENUM  "nein","ja";
BA_DEF_ SG_  "FlexKomSID" INT 0 2147483647;
BA_DEF_ SG_  "FlexKomSigLaenge" INT 0 64;
BA_DEF_ SG_  "FlexKomSigName" STRING ;
BA_DEF_ SG_  "FlexKomSigStartPos" INT 0 63;
BA_DEF_ SG_  "FlexKomSigStartValue" STRING ;
BA_DEF_ SG_  "GenSigCycleTime" INT 0 65535;
BA_DEF_ SG_  "GenSigCycleTimeActive" INT 0 65535;
BA_DEF_ SG_  "GenSigSendType" ENUM  "cyclicX","spontanX","cyclicIfActiveX","spontanWithDelay","cyclicAndSpontanX","cyclicAndSpontanWithDelay","spontanWithRepitition","cyclicIfActiveAndSpontanWD","cyclicIfActiveFast","cyclicWithRepeatOnDemand","none";
BA_DEF_ SG_  "GenSigSNA" STRING ;
BA_DEF_ SG_  "GenSigStartValue" HEX 0 2147483648;
BA_DEF_ SG_  "RID" STRING ;
BA_DEF_DEF_  "App-Botschaft" "nein";
BA_DEF_DEF_  "CanMsgMinLen" 0;
BA_DEF_DEF_  "DiagRequest" "nein";
BA_DEF_DEF_  "DiagResponse" "nein";
BA_DEF_DEF_  "DiagState" "nein";
BA_DEF_DEF_  "GenMsgCycleTime" 0;
BA_DEF_DEF_  "GenMsgCycleTimeActive" 0;
BA_DEF_DEF_  "GenMsgDelayTime" 0;
BA_DEF_DEF_  "GenMsgNrOfRepetitions" 0;
BA_DEF_DEF_  "GenMsgSendType" "cyclicX";
BA_DEF_DEF_  "GenMsgStartDelayTime" 0;
BA_DEF_DEF_  "GenMsgStartValue" "";
BA_DEF_DEF_  "NWM-Botschaft" "nein";
BA_DEF_DEF_  "TpTxIndex" 0;
BA_DEF_DEF_  "FlexKomComment" "";
BA_DEF_DEF_  "FlexKomIsMotorola" "nein";
BA_DEF_DEF_  "FlexKomSID" 0;
BA_DEF_DEF_  "FlexKomSigLaenge" 0;
BA_DEF_DEF_  "FlexKomSigName" "";
BA_DEF_DEF_  "FlexKomSigStartPos" 0;
BA_DEF_DEF_  "FlexKomSigStartValue" "";
BA_DEF_DEF_  "GenSigCycleTime" 0;
BA_DEF_DEF_  "GenSigCycleTimeActive" 0;
BA_DEF_DEF_  "GenSigSendType" "cyclicX";
BA_DEF_DEF_  "GenSigSNA" "";
BA_DEF_DEF_  "GenSigStartValue" 0;
BA_DEF_DEF_  "RID" "";
BA_ "GenMsgStartValue" BO_ 768 "0000FF0000FFh";
BA_ "GenMsgNrOfRepetitions" BO_ 768 2;
BA_ "GenMsgDelayTime" BO_ 768 20;
BA_ "GenMsgCycleTime" BO_ 768 20;
BA_ "GenMsgStartValue" BO_ 677 "000000001Ch";
BA_ "GenMsgNrOfRepetitions" BO_ 677 2;
BA_ "GenMsgDelayTime" BO_ 677 20;
BA_ "GenMsgCycleTime" BO_ 677 100;
BA_ "GenMsgStartValue" BO_ 1007 "00000000000000h";
BA_ "GenMsgNrOfRepetitions" BO_ 1007 2;
BA_ "GenMsgDelayTime" BO_ 1007 20;
BA_ "GenMsgCycleTime" BO_ 1007 1000;
BA_ "GenMsgStartValue" BO_ 472 "00000000000003FFh";
BA_ "GenMsgNrOfRepetitions" BO_ 472 2;
BA_ "GenMsgDelayTime" BO_ 472 20;
BA_ "GenMsgCycleTime" BO_ 472 20;
BA_ "GenMsgStartValue" BO_ 169 "03AA03AA03AA00FFh";
BA_ "GenMsgNrOfRepetitions" BO_ 169 2;
BA_ "GenMsgDelayTime" BO_ 169 20;
BA_ "GenMsgCycleTime" BO_ 169 10;
BA_ "GenMsgStartValue" BO_ 180 "000000000000FFh";
BA_ "GenMsgNrOfRepetitions" BO_ 180 2;
BA_ "GenMsgDelayTime" BO_ 180 20;
BA_ "GenMsgCycleTime" BO_ 180 10;
BA_ "GenMsgStartValue" BO_ 471 "00000000000000FFh";
BA_ "GenMsgNrOfRepetitions" BO_ 471 2;
BA_ "GenMsgDelayTime" BO_ 471 20;
BA_ "GenMsgCycleTime" BO_ 471 10;
BA_ "GenMsgStartValue" BO_ 769 "01FFFF0000000000h";
BA_ "GenMsgNrOfRepetitions" BO_ 769 2;
BA_ "GenMsgDelayTime" BO_ 769 20;
BA_ "GenMsgCycleTime" BO_ 769 100;
BA_ "GenMsgStartValue" BO_ 276 "00h";
BA_ "GenMsgSendType" BO_ 276 1;
BA_ "GenMsgNrOfRepetitions" BO_ 276 2;
BA_ "GenMsgDelayTime" BO_ 276 20;
BA_ "GenMsgStartValue" BO_ 720 "00000000FFh";
BA_ "GenMsgNrOfRepetitions" BO_ 720 2;
BA_ "GenMsgDelayTime" BO_ 720 20;
BA_ "GenMsgCycleTime" BO_ 720 20;
BA_ "GenMsgStartValue" BO_ 926 "030000h";
BA_ "GenMsgSendType" BO_ 926 5;
BA_ "GenMsgNrOfRepetitions" BO_ 926 2;
BA_ "GenMsgDelayTime" BO_ 926 20;
BA_ "GenMsgCycleTime" BO_ 926 2000;
BA_ "NWM-Botschaft" BO_ 1066 1;
BA_ "GenMsgStartValue" BO_ 1066 "0000000000000000h";
BA_ "GenMsgNrOfRepetitions" BO_ 1066 2;
BA_ "GenMsgDelayTime" BO_ 1066 20;
BA_ "NWM-Botschaft" BO_ 1070 1;
BA_ "GenMsgStartValue" BO_ 1070 "0000000000000000h";
BA_ "GenMsgNrOfRepetitions" BO_ 1070 2;
BA_ "GenMsgDelayTime" BO_ 1070 20;
BA_ "GenMsgStartValue" BO_ 777 "0000000000000060h";
BA_ "GenMsgNrOfRepetitions" BO_ 777 2;
BA_ "GenMsgDelayTime" BO_ 777 20;
BA_ "GenMsgCycleTime" BO_ 777 100;
BA_ "GenMsgStartValue" BO_ 277 "0000000000000000h";
BA_ "GenMsgNrOfRepetitions" BO_ 277 2;
BA_ "GenMsgDelayTime" BO_ 277 20;
BA_ "GenMsgCycleTime" BO_ 277 100;
BA_ "GenMsgStartValue" BO_ 976 "0000000000000000h";
BA_ "GenMsgNrOfRepetitions" BO_ 976 2;
BA_ "GenMsgDelayTime" BO_ 976 20;
BA_ "GenMsgCycleTime" BO_ 976 500;
BA_ "GenMsgStartValue" BO_ 776 "0000000014000000h";
BA_ "GenMsgNrOfRepetitions" BO_ 776 2;
BA_ "GenMsgDelayTime" BO_ 776 20;
BA_ "GenMsgCycleTime" BO_ 776 100;
BA_ "GenMsgStartValue" BO_ 979 "000000000000h";
BA_ "GenMsgNrOfRepetitions" BO_ 979 2;
BA_ "GenMsgDelayTime" BO_ 979 20;
BA_ "GenMsgCycleTime" BO_ 979 1000;
BA_ "GenMsgStartValue" BO_ 980 "0000000000000000h";
BA_ "GenMsgNrOfRepetitions" BO_ 980 2;
BA_ "GenMsgDelayTime" BO_ 980 20;
BA_ "GenMsgCycleTime" BO_ 980 1000;
BA_ "GenMsgStartValue" BO_ 466 "0000h";
BA_ "GenMsgSendType" BO_ 466 2;
BA_ "GenMsgNrOfRepetitions" BO_ 466 2;
BA_ "GenMsgDelayTime" BO_ 466 20;
BA_ "GenMsgCycleTimeActive" BO_ 466 20;
BA_ "GenMsgStartValue" BO_ 467 "0000h";
BA_ "GenMsgSendType" BO_ 467 2;
BA_ "GenMsgNrOfRepetitions" BO_ 467 2;
BA_ "GenMsgDelayTime" BO_ 467 20;
BA_ "GenMsgCycleTimeActive" BO_ 467 20;
BA_ "GenMsgStartValue" BO_ 469 "0000000000000000h";
BA_ "GenMsgSendType" BO_ 469 5;
BA_ "GenMsgNrOfRepetitions" BO_ 469 2;
BA_ "GenMsgDelayTime" BO_ 469 20;
BA_ "GenMsgCycleTime" BO_ 469 250;
BA_ "GenMsgStartValue" BO_ 470 "0000000000000000h";
BA_ "GenMsgSendType" BO_ 470 5;
BA_ "GenMsgNrOfRepetitions" BO_ 470 2;
BA_ "GenMsgDelayTime" BO_ 470 20;
BA_ "GenMsgCycleTime" BO_ 470 250;
BA_ "GenMsgStartValue" BO_ 787 "0000000000FFh";
BA_ "GenMsgNrOfRepetitions" BO_ 787 2;
BA_ "GenMsgDelayTime" BO_ 787 20;
BA_ "GenMsgCycleTime" BO_ 787 100;
BA_ "GenMsgStartValue" BO_ 272 "0000000000000000h";
BA_ "GenMsgNrOfRepetitions" BO_ 272 2;
BA_ "GenMsgDelayTime" BO_ 272 20;
BA_ "GenMsgCycleTime" BO_ 272 10;
BA_ "GenMsgStartValue" BO_ 274 "0000000000000000h";
BA_ "GenMsgNrOfRepetitions" BO_ 274 2;
BA_ "GenMsgDelayTime" BO_ 274 20;
BA_ "GenMsgCycleTime" BO_ 274 10;
BA_ "GenMsgStartValue" BO_ 528 "00000000FFh";
BA_ "GenMsgNrOfRepetitions" BO_ 528 2;
BA_ "GenMsgDelayTime" BO_ 528 20;
BA_ "GenMsgCycleTime" BO_ 528 20;
BA_ "GenMsgStartValue" BO_ 298 "0000FFFF00FFh";
BA_ "GenMsgNrOfRepetitions" BO_ 298 2;
BA_ "GenMsgDelayTime" BO_ 298 20;
BA_ "GenMsgCycleTime" BO_ 298 10;
BA_ "GenMsgStartValue" BO_ 1599 "0000000000000000h";
BA_ "GenMsgStartDelayTime" BO_ 1599 800;
BA_ "GenMsgSendType" BO_ 1599 9;
BA_ "GenMsgNrOfRepetitions" BO_ 1599 3;
BA_ "GenMsgDelayTime" BO_ 1599 200;
BA_ "GenMsgCycleTime" BO_ 1599 200;
BA_ "GenMsgStartValue" BO_ 691 "000000h";
BA_ "GenMsgNrOfRepetitions" BO_ 691 2;
BA_ "GenMsgDelayTime" BO_ 691 20;
BA_ "GenMsgCycleTime" BO_ 691 500;
BA_ "GenMsgStartValue" BO_ 698 "00000000000000h";
BA_ "GenMsgNrOfRepetitions" BO_ 698 2;
BA_ "GenMsgDelayTime" BO_ 698 20;
BA_ "GenMsgCycleTime" BO_ 698 500;
BA_ "GenMsgStartValue" BO_ 992 "0300000000000000h";
BA_ "GenMsgNrOfRepetitions" BO_ 992 2;
BA_ "GenMsgDelayTime" BO_ 992 20;
BA_ "GenMsgCycleTime" BO_ 992 100;
BA_ "GenMsgStartValue" BO_ 1023 "FFFF7FF0FF0FFF00h";
BA_ "GenMsgSendType" BO_ 1023 5;
BA_ "GenMsgNrOfRepetitions" BO_ 1023 2;
BA_ "GenMsgDelayTime" BO_ 1023 20;
BA_ "GenMsgCycleTime" BO_ 1023 500;
BA_ "RID" SG_ 768 APCM_Rq "9807";
BA_ "GenSigSNA" SG_ 768 APCM_Rq "3h";
BA_ "GenSigCycleTime" SG_ 768 APCM_Rq 20;
BA_ "FlexKomSigStartValue" SG_ 768 APCM_Rq "0000FF0000FFh";
BA_ "FlexKomSigStartPos" SG_ 768 APCM_Rq 7;
BA_ "FlexKomSigName" SG_ 768 APCM_Rq "HCP_TRNS_STAT_EPT";
BA_ "FlexKomSigLaenge" SG_ 768 APCM_Rq 48;
BA_ "FlexKomSID" SG_ 768 APCM_Rq 2130708655;
BA_ "FlexKomIsMotorola" SG_ 768 APCM_Rq 1;
BA_ "FlexKomComment" SG_ 768 APCM_Rq ".";
BA_ "GenSigStartValue" SG_ 768 CRC_TRNS_STAT 255;
BA_ "GenSigSNA" SG_ 768 CRC_TRNS_STAT "FFh";
BA_ "GenSigCycleTime" SG_ 768 CRC_TRNS_STAT 20;
BA_ "FlexKomSigStartValue" SG_ 768 CRC_TRNS_STAT "0000FF0000FFh";
BA_ "FlexKomSigStartPos" SG_ 768 CRC_TRNS_STAT 7;
BA_ "FlexKomSigName" SG_ 768 CRC_TRNS_STAT "HCP_TRNS_STAT_EPT";
BA_ "FlexKomSigLaenge" SG_ 768 CRC_TRNS_STAT 48;
BA_ "FlexKomSID" SG_ 768 CRC_TRNS_STAT 2130708655;
BA_ "FlexKomIsMotorola" SG_ 768 CRC_TRNS_STAT 1;
BA_ "FlexKomComment" SG_ 768 CRC_TRNS_STAT ".";
BA_ "RID" SG_ 768 MC_TRNS_STAT "9809";
BA_ "GenSigSNA" SG_ 768 MC_TRNS_STAT "0h";
BA_ "GenSigCycleTime" SG_ 768 MC_TRNS_STAT 20;
BA_ "FlexKomSigStartValue" SG_ 768 MC_TRNS_STAT "0000FF0000FFh";
BA_ "FlexKomSigStartPos" SG_ 768 MC_TRNS_STAT 7;
BA_ "FlexKomSigName" SG_ 768 MC_TRNS_STAT "HCP_TRNS_STAT_EPT";
BA_ "FlexKomSigLaenge" SG_ 768 MC_TRNS_STAT 48;
BA_ "FlexKomSID" SG_ 768 MC_TRNS_STAT 2130708655;
BA_ "FlexKomIsMotorola" SG_ 768 MC_TRNS_STAT 1;
BA_ "FlexKomComment" SG_ 768 MC_TRNS_STAT ".";
BA_ "RID" SG_ 768 PRNDL_Blink "9810";
BA_ "GenSigSNA" SG_ 768 PRNDL_Blink "0h";
BA_ "GenSigCycleTime" SG_ 768 PRNDL_Blink 20;
BA_ "FlexKomSigStartValue" SG_ 768 PRNDL_Blink "0000FF0000FFh";
BA_ "FlexKomSigStartPos" SG_ 768 PRNDL_Blink 7;
BA_ "FlexKomSigName" SG_ 768 PRNDL_Blink "HCP_TRNS_STAT_EPT";
BA_ "FlexKomSigLaenge" SG_ 768 PRNDL_Blink 48;
BA_ "FlexKomSID" SG_ 768 PRNDL_Blink 2130708655;
BA_ "FlexKomIsMotorola" SG_ 768 PRNDL_Blink 1;
BA_ "FlexKomComment" SG_ 768 PRNDL_Blink ".";
BA_ "RID" SG_ 768 PRNDL_DISP "9811";
BA_ "GenSigStartValue" SG_ 768 PRNDL_DISP 255;
BA_ "GenSigSNA" SG_ 768 PRNDL_DISP "FFh";
BA_ "GenSigCycleTime" SG_ 768 PRNDL_DISP 20;
BA_ "FlexKomSigStartValue" SG_ 768 PRNDL_DISP "0000FF0000FFh";
BA_ "FlexKomSigStartPos" SG_ 768 PRNDL_DISP 7;
BA_ "FlexKomSigName" SG_ 768 PRNDL_DISP "HCP_TRNS_STAT_EPT";
BA_ "FlexKomSigLaenge" SG_ 768 PRNDL_DISP 48;
BA_ "FlexKomSID" SG_ 768 PRNDL_DISP 2130708655;
BA_ "FlexKomIsMotorola" SG_ 768 PRNDL_DISP 1;
BA_ "FlexKomComment" SG_ 768 PRNDL_DISP ".";
BA_ "RID" SG_ 768 R_SHFT_LOCK_DPT "9812";
BA_ "GenSigSNA" SG_ 768 R_SHFT_LOCK_DPT "0h";
BA_ "GenSigCycleTime" SG_ 768 R_SHFT_LOCK_DPT 20;
BA_ "FlexKomSigStartValue" SG_ 768 R_SHFT_LOCK_DPT "0000FF0000FFh";
BA_ "FlexKomSigStartPos" SG_ 768 R_SHFT_LOCK_DPT 7;
BA_ "FlexKomSigName" SG_ 768 R_SHFT_LOCK_DPT "HCP_TRNS_STAT_EPT";
BA_ "FlexKomSigLaenge" SG_ 768 R_SHFT_LOCK_DPT 48;
BA_ "FlexKomSID" SG_ 768 R_SHFT_LOCK_DPT 2130708655;
BA_ "FlexKomIsMotorola" SG_ 768 R_SHFT_LOCK_DPT 1;
BA_ "FlexKomComment" SG_ 768 R_SHFT_LOCK_DPT ".";
BA_ "RID" SG_ 768 SHFT_LOCK "9813";
BA_ "GenSigSNA" SG_ 768 SHFT_LOCK "0h";
BA_ "GenSigCycleTime" SG_ 768 SHFT_LOCK 20;
BA_ "FlexKomSigStartValue" SG_ 768 SHFT_LOCK "0000FF0000FFh";
BA_ "FlexKomSigStartPos" SG_ 768 SHFT_LOCK 7;
BA_ "FlexKomSigName" SG_ 768 SHFT_LOCK "HCP_TRNS_STAT_EPT";
BA_ "FlexKomSigLaenge" SG_ 768 SHFT_LOCK 48;
BA_ "FlexKomSID" SG_ 768 SHFT_LOCK 2130708655;
BA_ "FlexKomIsMotorola" SG_ 768 SHFT_LOCK 1;
BA_ "FlexKomComment" SG_ 768 SHFT_LOCK ".";
BA_ "GenSigSNA" SG_ 677 ChrgEnable "0h";
BA_ "GenSigCycleTime" SG_ 677 ChrgEnable 100;
BA_ "FlexKomSigStartValue" SG_ 677 ChrgEnable "000000001Ch";
BA_ "FlexKomSigStartPos" SG_ 677 ChrgEnable 7;
BA_ "FlexKomSigName" SG_ 677 ChrgEnable "Hybrid_Charging_Command";
BA_ "FlexKomSigLaenge" SG_ 677 ChrgEnable 40;
BA_ "FlexKomSID" SG_ 677 ChrgEnable 2130708656;
BA_ "FlexKomIsMotorola" SG_ 677 ChrgEnable 1;
BA_ "FlexKomComment" SG_ 677 ChrgEnable ".";
BA_ "GenSigSNA" SG_ 677 CurrRq "0h";
BA_ "GenSigCycleTime" SG_ 677 CurrRq 100;
BA_ "FlexKomSigStartValue" SG_ 677 CurrRq "000000001Ch";
BA_ "FlexKomSigStartPos" SG_ 677 CurrRq 7;
BA_ "FlexKomSigName" SG_ 677 CurrRq "Hybrid_Charging_Command";
BA_ "FlexKomSigLaenge" SG_ 677 CurrRq 40;
BA_ "FlexKomSID" SG_ 677 CurrRq 2130708656;
BA_ "FlexKomIsMotorola" SG_ 677 CurrRq 1;
BA_ "FlexKomComment" SG_ 677 CurrRq ".";
BA_ "GenSigSNA" SG_ 677 J1772_S2_Close "0h";
BA_ "GenSigCycleTime" SG_ 677 J1772_S2_Close 100;
BA_ "FlexKomSigStartValue" SG_ 677 J1772_S2_Close "000000001Ch";
BA_ "FlexKomSigStartPos" SG_ 677 J1772_S2_Close 7;
BA_ "FlexKomSigName" SG_ 677 J1772_S2_Close "Hybrid_Charging_Command";
BA_ "FlexKomSigLaenge" SG_ 677 J1772_S2_Close 40;
BA_ "FlexKomSID" SG_ 677 J1772_S2_Close 2130708656;
BA_ "FlexKomIsMotorola" SG_ 677 J1772_S2_Close 1;
BA_ "FlexKomComment" SG_ 677 J1772_S2_Close ".";
BA_ "GenSigSNA" SG_ 677 OBC_Ctrl_Mth "3h";
BA_ "GenSigCycleTime" SG_ 677 OBC_Ctrl_Mth 100;
BA_ "FlexKomSigStartValue" SG_ 677 OBC_Ctrl_Mth "000000001Ch";
BA_ "FlexKomSigStartPos" SG_ 677 OBC_Ctrl_Mth 7;
BA_ "FlexKomSigName" SG_ 677 OBC_Ctrl_Mth "Hybrid_Charging_Command";
BA_ "FlexKomSigLaenge" SG_ 677 OBC_Ctrl_Mth 40;
BA_ "FlexKomSID" SG_ 677 OBC_Ctrl_Mth 2130708656;
BA_ "FlexKomIsMotorola" SG_ 677 OBC_Ctrl_Mth 1;
BA_ "FlexKomComment" SG_ 677 OBC_Ctrl_Mth ".";
BA_ "GenSigStartValue" SG_ 677 OBC_MdRq 7;
BA_ "GenSigSNA" SG_ 677 OBC_MdRq "7h";
BA_ "GenSigCycleTime" SG_ 677 OBC_MdRq 100;
BA_ "FlexKomSigStartValue" SG_ 677 OBC_MdRq "000000001Ch";
BA_ "FlexKomSigStartPos" SG_ 677 OBC_MdRq 7;
BA_ "FlexKomSigName" SG_ 677 OBC_MdRq "Hybrid_Charging_Command";
BA_ "FlexKomSigLaenge" SG_ 677 OBC_MdRq 40;
BA_ "FlexKomSID" SG_ 677 OBC_MdRq 2130708656;
BA_ "FlexKomIsMotorola" SG_ 677 OBC_MdRq 1;
BA_ "FlexKomComment" SG_ 677 OBC_MdRq ".";
BA_ "GenSigStartValue" SG_ 677 ProxStatus 3;
BA_ "GenSigSNA" SG_ 677 ProxStatus "3h";
BA_ "GenSigCycleTime" SG_ 677 ProxStatus 100;
BA_ "FlexKomSigStartValue" SG_ 677 ProxStatus "000000001Ch";
BA_ "FlexKomSigStartPos" SG_ 677 ProxStatus 7;
BA_ "FlexKomSigName" SG_ 677 ProxStatus "Hybrid_Charging_Command";
BA_ "FlexKomSigLaenge" SG_ 677 ProxStatus 40;
BA_ "FlexKomSID" SG_ 677 ProxStatus 2130708656;
BA_ "FlexKomIsMotorola" SG_ 677 ProxStatus 1;
BA_ "FlexKomComment" SG_ 677 ProxStatus ".";
BA_ "GenSigSNA" SG_ 677 VoltRq "0h";
BA_ "GenSigCycleTime" SG_ 677 VoltRq 100;
BA_ "FlexKomSigStartValue" SG_ 677 VoltRq "000000001Ch";
BA_ "FlexKomSigStartPos" SG_ 677 VoltRq 7;
BA_ "FlexKomSigName" SG_ 677 VoltRq "Hybrid_Charging_Command";
BA_ "FlexKomSigLaenge" SG_ 677 VoltRq 40;
BA_ "FlexKomSID" SG_ 677 VoltRq 2130708656;
BA_ "FlexKomIsMotorola" SG_ 677 VoltRq 1;
BA_ "FlexKomComment" SG_ 677 VoltRq ".";
BA_ "GenSigSNA" SG_ 1007 AC_CurrMaxCal "1FFh";
BA_ "GenSigCycleTime" SG_ 1007 AC_CurrMaxCal 1000;
BA_ "FlexKomSigStartValue" SG_ 1007 AC_CurrMaxCal "00000000000000h";
BA_ "FlexKomSigStartPos" SG_ 1007 AC_CurrMaxCal 7;
BA_ "FlexKomSigName" SG_ 1007 AC_CurrMaxCal "Hybrid_Charging_Stat1";
BA_ "FlexKomSigLaenge" SG_ 1007 AC_CurrMaxCal 56;
BA_ "FlexKomSID" SG_ 1007 AC_CurrMaxCal 2130708657;
BA_ "FlexKomIsMotorola" SG_ 1007 AC_CurrMaxCal 1;
BA_ "FlexKomComment" SG_ 1007 AC_CurrMaxCal ".";
BA_ "GenSigSNA" SG_ 1007 HV_CurrMaxCal "FFh";
BA_ "GenSigCycleTime" SG_ 1007 HV_CurrMaxCal 1000;
BA_ "FlexKomSigStartValue" SG_ 1007 HV_CurrMaxCal "00000000000000h";
BA_ "FlexKomSigStartPos" SG_ 1007 HV_CurrMaxCal 7;
BA_ "FlexKomSigName" SG_ 1007 HV_CurrMaxCal "Hybrid_Charging_Stat1";
BA_ "FlexKomSigLaenge" SG_ 1007 HV_CurrMaxCal 56;
BA_ "FlexKomSID" SG_ 1007 HV_CurrMaxCal 2130708657;
BA_ "FlexKomIsMotorola" SG_ 1007 HV_CurrMaxCal 1;
BA_ "FlexKomComment" SG_ 1007 HV_CurrMaxCal ".";
BA_ "GenSigSNA" SG_ 1007 HV_VoltMaxCal "1FFh";
BA_ "GenSigCycleTime" SG_ 1007 HV_VoltMaxCal 1000;
BA_ "FlexKomSigStartValue" SG_ 1007 HV_VoltMaxCal "00000000000000h";
BA_ "FlexKomSigStartPos" SG_ 1007 HV_VoltMaxCal 7;
BA_ "FlexKomSigName" SG_ 1007 HV_VoltMaxCal "Hybrid_Charging_Stat1";
BA_ "FlexKomSigLaenge" SG_ 1007 HV_VoltMaxCal 56;
BA_ "FlexKomSID" SG_ 1007 HV_VoltMaxCal 2130708657;
BA_ "FlexKomIsMotorola" SG_ 1007 HV_VoltMaxCal 1;
BA_ "FlexKomComment" SG_ 1007 HV_VoltMaxCal ".";
BA_ "GenSigSNA" SG_ 1007 HV_VoltMinCal "1FFh";
BA_ "GenSigCycleTime" SG_ 1007 HV_VoltMinCal 1000;
BA_ "FlexKomSigStartValue" SG_ 1007 HV_VoltMinCal "00000000000000h";
BA_ "FlexKomSigStartPos" SG_ 1007 HV_VoltMinCal 7;
BA_ "FlexKomSigName" SG_ 1007 HV_VoltMinCal "Hybrid_Charging_Stat1";
BA_ "FlexKomSigLaenge" SG_ 1007 HV_VoltMinCal 56;
BA_ "FlexKomSID" SG_ 1007 HV_VoltMinCal 2130708657;
BA_ "FlexKomIsMotorola" SG_ 1007 HV_VoltMinCal 1;
BA_ "FlexKomComment" SG_ 1007 HV_VoltMinCal ".";
BA_ "GenSigSNA" SG_ 472 BattPerWU_12VChg_Timer "3FFh";
BA_ "GenSigCycleTime" SG_ 472 BattPerWU_12VChg_Timer 20;
BA_ "FlexKomSigStartValue" SG_ 472 BattPerWU_12VChg_Timer "00000000000003FFh";
BA_ "FlexKomSigStartPos" SG_ 472 BattPerWU_12VChg_Timer 7;
BA_ "FlexKomSigName" SG_ 472 BattPerWU_12VChg_Timer "Hybrid_Command_BPCM";
BA_ "FlexKomSigLaenge" SG_ 472 BattPerWU_12VChg_Timer 64;
BA_ "FlexKomSID" SG_ 472 BattPerWU_12VChg_Timer 2130708658;
BA_ "FlexKomIsMotorola" SG_ 472 BattPerWU_12VChg_Timer 1;
BA_ "FlexKomComment" SG_ 472 BattPerWU_12VChg_Timer ".";
BA_ "GenSigSNA" SG_ 472 BattPerWU_ThermalCond_Timer "3FFh";
BA_ "GenSigCycleTime" SG_ 472 BattPerWU_ThermalCond_Timer 20;
BA_ "FlexKomSigStartValue" SG_ 472 BattPerWU_ThermalCond_Timer "00000000000003FFh";
BA_ "FlexKomSigStartPos" SG_ 472 BattPerWU_ThermalCond_Timer 7;
BA_ "FlexKomSigName" SG_ 472 BattPerWU_ThermalCond_Timer "Hybrid_Command_BPCM";
BA_ "FlexKomSigLaenge" SG_ 472 BattPerWU_ThermalCond_Timer 64;
BA_ "FlexKomSID" SG_ 472 BattPerWU_ThermalCond_Timer 2130708658;
BA_ "FlexKomIsMotorola" SG_ 472 BattPerWU_ThermalCond_Timer 1;
BA_ "FlexKomComment" SG_ 472 BattPerWU_ThermalCond_Timer ".";
BA_ "GenSigStartValue" SG_ 472 CRC_1D8h 255;
BA_ "GenSigSNA" SG_ 472 CRC_1D8h "FFh";
BA_ "GenSigCycleTime" SG_ 472 CRC_1D8h 20;
BA_ "FlexKomSigStartValue" SG_ 472 CRC_1D8h "00000000000003FFh";
BA_ "FlexKomSigStartPos" SG_ 472 CRC_1D8h 7;
BA_ "FlexKomSigName" SG_ 472 CRC_1D8h "Hybrid_Command_BPCM";
BA_ "FlexKomSigLaenge" SG_ 472 CRC_1D8h 64;
BA_ "FlexKomSID" SG_ 472 CRC_1D8h 2130708658;
BA_ "FlexKomIsMotorola" SG_ 472 CRC_1D8h 1;
BA_ "FlexKomComment" SG_ 472 CRC_1D8h ".";
BA_ "GenSigSNA" SG_ 472 HVBatBalReq "3h";
BA_ "GenSigCycleTime" SG_ 472 HVBatBalReq 20;
BA_ "FlexKomSigStartValue" SG_ 472 HVBatBalReq "00000000000003FFh";
BA_ "FlexKomSigStartPos" SG_ 472 HVBatBalReq 7;
BA_ "FlexKomSigName" SG_ 472 HVBatBalReq "Hybrid_Command_BPCM";
BA_ "FlexKomSigLaenge" SG_ 472 HVBatBalReq 64;
BA_ "FlexKomSID" SG_ 472 HVBatBalReq 2130708658;
BA_ "FlexKomIsMotorola" SG_ 472 HVBatBalReq 1;
BA_ "FlexKomComment" SG_ 472 HVBatBalReq ".";
BA_ "GenSigStartValue" SG_ 472 HVBat_CoolantLvlLo 3;
BA_ "GenSigSNA" SG_ 472 HVBat_CoolantLvlLo "3h";
BA_ "GenSigCycleTime" SG_ 472 HVBat_CoolantLvlLo 20;
BA_ "FlexKomSigStartValue" SG_ 472 HVBat_CoolantLvlLo "00000000000003FFh";
BA_ "FlexKomSigStartPos" SG_ 472 HVBat_CoolantLvlLo 7;
BA_ "FlexKomSigName" SG_ 472 HVBat_CoolantLvlLo "Hybrid_Command_BPCM";
BA_ "FlexKomSigLaenge" SG_ 472 HVBat_CoolantLvlLo 64;
BA_ "FlexKomSID" SG_ 472 HVBat_CoolantLvlLo 2130708658;
BA_ "FlexKomIsMotorola" SG_ 472 HVBat_CoolantLvlLo 1;
BA_ "FlexKomComment" SG_ 472 HVBat_CoolantLvlLo ".";
BA_ "GenSigSNA" SG_ 472 HVInvRatVlt "1FFh";
BA_ "GenSigCycleTime" SG_ 472 HVInvRatVlt 20;
BA_ "FlexKomSigStartValue" SG_ 472 HVInvRatVlt "00000000000003FFh";
BA_ "FlexKomSigStartPos" SG_ 472 HVInvRatVlt 7;
BA_ "FlexKomSigName" SG_ 472 HVInvRatVlt "Hybrid_Command_BPCM";
BA_ "FlexKomSigLaenge" SG_ 472 HVInvRatVlt 64;
BA_ "FlexKomSID" SG_ 472 HVInvRatVlt 2130708658;
BA_ "FlexKomIsMotorola" SG_ 472 HVInvRatVlt 1;
BA_ "FlexKomComment" SG_ 472 HVInvRatVlt ".";
BA_ "GenSigSNA" SG_ 472 HVInvRatVltV "0h";
BA_ "GenSigCycleTime" SG_ 472 HVInvRatVltV 20;
BA_ "FlexKomSigStartValue" SG_ 472 HVInvRatVltV "00000000000003FFh";
BA_ "FlexKomSigStartPos" SG_ 472 HVInvRatVltV 7;
BA_ "FlexKomSigName" SG_ 472 HVInvRatVltV "Hybrid_Command_BPCM";
BA_ "FlexKomSigLaenge" SG_ 472 HVInvRatVltV 64;
BA_ "FlexKomSID" SG_ 472 HVInvRatVltV 2130708658;
BA_ "FlexKomIsMotorola" SG_ 472 HVInvRatVltV 1;
BA_ "FlexKomComment" SG_ 472 HVInvRatVltV ".";
BA_ "GenSigSNA" SG_ 472 MC_1D8h "0h";
BA_ "GenSigCycleTime" SG_ 472 MC_1D8h 20;
BA_ "FlexKomSigStartValue" SG_ 472 MC_1D8h "00000000000003FFh";
BA_ "FlexKomSigStartPos" SG_ 472 MC_1D8h 7;
BA_ "FlexKomSigName" SG_ 472 MC_1D8h "Hybrid_Command_BPCM";
BA_ "FlexKomSigLaenge" SG_ 472 MC_1D8h 64;
BA_ "FlexKomSID" SG_ 472 MC_1D8h 2130708658;
BA_ "FlexKomIsMotorola" SG_ 472 MC_1D8h 1;
BA_ "FlexKomComment" SG_ 472 MC_1D8h ".";
BA_ "GenSigSNA" SG_ 472 MainHighVltCntctrCmd "0h";
BA_ "GenSigCycleTime" SG_ 472 MainHighVltCntctrCmd 20;
BA_ "FlexKomSigStartValue" SG_ 472 MainHighVltCntctrCmd "00000000000003FFh";
BA_ "FlexKomSigStartPos" SG_ 472 MainHighVltCntctrCmd 7;
BA_ "FlexKomSigName" SG_ 472 MainHighVltCntctrCmd "Hybrid_Command_BPCM";
BA_ "FlexKomSigLaenge" SG_ 472 MainHighVltCntctrCmd 64;
BA_ "FlexKomSID" SG_ 472 MainHighVltCntctrCmd 2130708658;
BA_ "FlexKomIsMotorola" SG_ 472 MainHighVltCntctrCmd 1;
BA_ "FlexKomComment" SG_ 472 MainHighVltCntctrCmd ".";
BA_ "GenSigSNA" SG_ 472 PwrtrnHV_IntrlkStat "0h";
BA_ "GenSigCycleTime" SG_ 472 PwrtrnHV_IntrlkStat 20;
BA_ "FlexKomSigStartValue" SG_ 472 PwrtrnHV_IntrlkStat "00000000000003FFh";
BA_ "FlexKomSigStartPos" SG_ 472 PwrtrnHV_IntrlkStat 7;
BA_ "FlexKomSigName" SG_ 472 PwrtrnHV_IntrlkStat "Hybrid_Command_BPCM";
BA_ "FlexKomSigLaenge" SG_ 472 PwrtrnHV_IntrlkStat 64;
BA_ "FlexKomSID" SG_ 472 PwrtrnHV_IntrlkStat 2130708658;
BA_ "FlexKomIsMotorola" SG_ 472 PwrtrnHV_IntrlkStat 1;
BA_ "FlexKomComment" SG_ 472 PwrtrnHV_IntrlkStat ".";
BA_ "GenSigStartValue" SG_ 169 CRC_0A9h 255;
BA_ "GenSigSNA" SG_ 169 CRC_0A9h "FFh";
BA_ "GenSigCycleTime" SG_ 169 CRC_0A9h 10;
BA_ "FlexKomSigStartValue" SG_ 169 CRC_0A9h "03AA03AA03AA00FFh";
BA_ "FlexKomSigStartPos" SG_ 169 CRC_0A9h 7;
BA_ "FlexKomSigName" SG_ 169 CRC_0A9h "Hybrid_Eng_Torq_Status";
BA_ "FlexKomSigLaenge" SG_ 169 CRC_0A9h 64;
BA_ "FlexKomSID" SG_ 169 CRC_0A9h 2130708660;
BA_ "FlexKomIsMotorola" SG_ 169 CRC_0A9h 1;
BA_ "FlexKomComment" SG_ 169 CRC_0A9h ".";
BA_ "GenSigSNA" SG_ 169 EngCntrlMode "0h";
BA_ "GenSigCycleTime" SG_ 169 EngCntrlMode 10;
BA_ "FlexKomSigStartValue" SG_ 169 EngCntrlMode "03AA03AA03AA00FFh";
BA_ "FlexKomSigStartPos" SG_ 169 EngCntrlMode 7;
BA_ "FlexKomSigName" SG_ 169 EngCntrlMode "Hybrid_Eng_Torq_Status";
BA_ "FlexKomSigLaenge" SG_ 169 EngCntrlMode 64;
BA_ "FlexKomSID" SG_ 169 EngCntrlMode 2130708660;
BA_ "FlexKomIsMotorola" SG_ 169 EngCntrlMode 1;
BA_ "FlexKomComment" SG_ 169 EngCntrlMode ".";
BA_ "GenSigStartValue" SG_ 169 HybCmndEngTorqImmed 938;
BA_ "GenSigSNA" SG_ 169 HybCmndEngTorqImmed "FFFh";
BA_ "GenSigCycleTime" SG_ 169 HybCmndEngTorqImmed 10;
BA_ "FlexKomSigStartValue" SG_ 169 HybCmndEngTorqImmed "03AA03AA03AA00FFh";
BA_ "FlexKomSigStartPos" SG_ 169 HybCmndEngTorqImmed 7;
BA_ "FlexKomSigName" SG_ 169 HybCmndEngTorqImmed "Hybrid_Eng_Torq_Status";
BA_ "FlexKomSigLaenge" SG_ 169 HybCmndEngTorqImmed 64;
BA_ "FlexKomSID" SG_ 169 HybCmndEngTorqImmed 2130708660;
BA_ "FlexKomIsMotorola" SG_ 169 HybCmndEngTorqImmed 1;
BA_ "FlexKomComment" SG_ 169 HybCmndEngTorqImmed ".";
BA_ "GenSigStartValue" SG_ 169 HybCmndEngTorqPrdtd 938;
BA_ "GenSigSNA" SG_ 169 HybCmndEngTorqPrdtd "FFFh";
BA_ "GenSigCycleTime" SG_ 169 HybCmndEngTorqPrdtd 10;
BA_ "FlexKomSigStartValue" SG_ 169 HybCmndEngTorqPrdtd "03AA03AA03AA00FFh";
BA_ "FlexKomSigStartPos" SG_ 169 HybCmndEngTorqPrdtd 7;
BA_ "FlexKomSigName" SG_ 169 HybCmndEngTorqPrdtd "Hybrid_Eng_Torq_Status";
BA_ "FlexKomSigLaenge" SG_ 169 HybCmndEngTorqPrdtd 64;
BA_ "FlexKomSID" SG_ 169 HybCmndEngTorqPrdtd 2130708660;
BA_ "FlexKomIsMotorola" SG_ 169 HybCmndEngTorqPrdtd 1;
BA_ "FlexKomComment" SG_ 169 HybCmndEngTorqPrdtd ".";
BA_ "GenSigSNA" SG_ 169 HybCmndEngTorqRespTyp "3h";
BA_ "GenSigCycleTime" SG_ 169 HybCmndEngTorqRespTyp 10;
BA_ "FlexKomSigStartValue" SG_ 169 HybCmndEngTorqRespTyp "03AA03AA03AA00FFh";
BA_ "FlexKomSigStartPos" SG_ 169 HybCmndEngTorqRespTyp 7;
BA_ "FlexKomSigName" SG_ 169 HybCmndEngTorqRespTyp "Hybrid_Eng_Torq_Status";
BA_ "FlexKomSigLaenge" SG_ 169 HybCmndEngTorqRespTyp 64;
BA_ "FlexKomSID" SG_ 169 HybCmndEngTorqRespTyp 2130708660;
BA_ "FlexKomIsMotorola" SG_ 169 HybCmndEngTorqRespTyp 1;
BA_ "FlexKomComment" SG_ 169 HybCmndEngTorqRespTyp ".";
BA_ "GenSigSNA" SG_ 169 HybCrnkAbrted "0h";
BA_ "GenSigCycleTime" SG_ 169 HybCrnkAbrted 10;
BA_ "FlexKomSigStartValue" SG_ 169 HybCrnkAbrted "03AA03AA03AA00FFh";
BA_ "FlexKomSigStartPos" SG_ 169 HybCrnkAbrted 7;
BA_ "FlexKomSigName" SG_ 169 HybCrnkAbrted "Hybrid_Eng_Torq_Status";
BA_ "FlexKomSigLaenge" SG_ 169 HybCrnkAbrted 64;
BA_ "FlexKomSID" SG_ 169 HybCrnkAbrted 2130708660;
BA_ "FlexKomIsMotorola" SG_ 169 HybCrnkAbrted 1;
BA_ "FlexKomComment" SG_ 169 HybCrnkAbrted ".";
BA_ "GenSigSNA" SG_ 169 HybDFCO_Req "0h";
BA_ "GenSigCycleTime" SG_ 169 HybDFCO_Req 10;
BA_ "FlexKomSigStartValue" SG_ 169 HybDFCO_Req "03AA03AA03AA00FFh";
BA_ "FlexKomSigStartPos" SG_ 169 HybDFCO_Req 7;
BA_ "FlexKomSigName" SG_ 169 HybDFCO_Req "Hybrid_Eng_Torq_Status";
BA_ "FlexKomSigLaenge" SG_ 169 HybDFCO_Req 64;
BA_ "FlexKomSID" SG_ 169 HybDFCO_Req 2130708660;
BA_ "FlexKomIsMotorola" SG_ 169 HybDFCO_Req 1;
BA_ "FlexKomComment" SG_ 169 HybDFCO_Req ".";
BA_ "GenSigStartValue" SG_ 169 HybEstEngTorq 938;
BA_ "GenSigSNA" SG_ 169 HybEstEngTorq "FFFh";
BA_ "GenSigCycleTime" SG_ 169 HybEstEngTorq 10;
BA_ "FlexKomSigStartValue" SG_ 169 HybEstEngTorq "03AA03AA03AA00FFh";
BA_ "FlexKomSigStartPos" SG_ 169 HybEstEngTorq 7;
BA_ "FlexKomSigName" SG_ 169 HybEstEngTorq "Hybrid_Eng_Torq_Status";
BA_ "FlexKomSigLaenge" SG_ 169 HybEstEngTorq 64;
BA_ "FlexKomSID" SG_ 169 HybEstEngTorq 2130708660;
BA_ "FlexKomIsMotorola" SG_ 169 HybEstEngTorq 1;
BA_ "FlexKomComment" SG_ 169 HybEstEngTorq ".";
BA_ "GenSigSNA" SG_ 169 HybEstEngTorqV "0h";
BA_ "GenSigCycleTime" SG_ 169 HybEstEngTorqV 10;
BA_ "FlexKomSigStartValue" SG_ 169 HybEstEngTorqV "03AA03AA03AA00FFh";
BA_ "FlexKomSigStartPos" SG_ 169 HybEstEngTorqV 7;
BA_ "FlexKomSigName" SG_ 169 HybEstEngTorqV "Hybrid_Eng_Torq_Status";
BA_ "FlexKomSigLaenge" SG_ 169 HybEstEngTorqV 64;
BA_ "FlexKomSID" SG_ 169 HybEstEngTorqV 2130708660;
BA_ "FlexKomIsMotorola" SG_ 169 HybEstEngTorqV 1;
BA_ "FlexKomComment" SG_ 169 HybEstEngTorqV ".";
BA_ "GenSigSNA" SG_ 169 MC_0A9h "0h";
BA_ "GenSigCycleTime" SG_ 169 MC_0A9h 10;
BA_ "FlexKomSigStartValue" SG_ 169 MC_0A9h "03AA03AA03AA00FFh";
BA_ "FlexKomSigStartPos" SG_ 169 MC_0A9h 7;
BA_ "FlexKomSigName" SG_ 169 MC_0A9h "Hybrid_Eng_Torq_Status";
BA_ "FlexKomSigLaenge" SG_ 169 MC_0A9h 64;
BA_ "FlexKomSID" SG_ 169 MC_0A9h 2130708660;
BA_ "FlexKomIsMotorola" SG_ 169 MC_0A9h 1;
BA_ "FlexKomComment" SG_ 169 MC_0A9h ".";
BA_ "GenSigStartValue" SG_ 180 CRC_0B4h 255;
BA_ "GenSigSNA" SG_ 180 CRC_0B4h "FFh";
BA_ "GenSigCycleTime" SG_ 180 CRC_0B4h 10;
BA_ "FlexKomSigStartValue" SG_ 180 CRC_0B4h "000000000000FFh";
BA_ "FlexKomSigStartPos" SG_ 180 CRC_0B4h 7;
BA_ "FlexKomSigName" SG_ 180 CRC_0B4h "Hybrid_Status1";
BA_ "FlexKomSigLaenge" SG_ 180 CRC_0B4h 56;
BA_ "FlexKomSID" SG_ 180 CRC_0B4h 2130708662;
BA_ "FlexKomIsMotorola" SG_ 180 CRC_0B4h 1;
BA_ "FlexKomComment" SG_ 180 CRC_0B4h "??";
BA_ "GenSigSNA" SG_ 180 DriveReady "0h";
BA_ "GenSigCycleTime" SG_ 180 DriveReady 10;
BA_ "FlexKomSigStartValue" SG_ 180 DriveReady "000000000000FFh";
BA_ "FlexKomSigStartPos" SG_ 180 DriveReady 7;
BA_ "FlexKomSigName" SG_ 180 DriveReady "Hybrid_Status1";
BA_ "FlexKomSigLaenge" SG_ 180 DriveReady 56;
BA_ "FlexKomSID" SG_ 180 DriveReady 2130708662;
BA_ "FlexKomIsMotorola" SG_ 180 DriveReady 1;
BA_ "FlexKomComment" SG_ 180 DriveReady "??";
BA_ "GenSigSNA" SG_ 180 EPT_LOC_DiagEnable "0h";
BA_ "GenSigCycleTime" SG_ 180 EPT_LOC_DiagEnable 10;
BA_ "FlexKomSigStartValue" SG_ 180 EPT_LOC_DiagEnable "000000000000FFh";
BA_ "FlexKomSigStartPos" SG_ 180 EPT_LOC_DiagEnable 7;
BA_ "FlexKomSigName" SG_ 180 EPT_LOC_DiagEnable "Hybrid_Status1";
BA_ "FlexKomSigLaenge" SG_ 180 EPT_LOC_DiagEnable 56;
BA_ "FlexKomSID" SG_ 180 EPT_LOC_DiagEnable 2130708662;
BA_ "FlexKomIsMotorola" SG_ 180 EPT_LOC_DiagEnable 1;
BA_ "FlexKomComment" SG_ 180 EPT_LOC_DiagEnable "??";
BA_ "RID" SG_ 180 HCPShutDwnCmd "9805";
BA_ "GenSigSNA" SG_ 180 HCPShutDwnCmd "7h";
BA_ "GenSigCycleTime" SG_ 180 HCPShutDwnCmd 10;
BA_ "FlexKomSigStartValue" SG_ 180 HCPShutDwnCmd "000000000000FFh";
BA_ "FlexKomSigStartPos" SG_ 180 HCPShutDwnCmd 7;
BA_ "FlexKomSigName" SG_ 180 HCPShutDwnCmd "Hybrid_Status1";
BA_ "FlexKomSigLaenge" SG_ 180 HCPShutDwnCmd 56;
BA_ "FlexKomSID" SG_ 180 HCPShutDwnCmd 2130708662;
BA_ "FlexKomIsMotorola" SG_ 180 HCPShutDwnCmd 1;
BA_ "FlexKomComment" SG_ 180 HCPShutDwnCmd "??";
BA_ "GenSigSNA" SG_ 180 HybFeedback_ECM "0h";
BA_ "GenSigCycleTime" SG_ 180 HybFeedback_ECM 10;
BA_ "FlexKomSigStartValue" SG_ 180 HybFeedback_ECM "000000000000FFh";
BA_ "FlexKomSigStartPos" SG_ 180 HybFeedback_ECM 7;
BA_ "FlexKomSigName" SG_ 180 HybFeedback_ECM "Hybrid_Status1";
BA_ "FlexKomSigLaenge" SG_ 180 HybFeedback_ECM 56;
BA_ "FlexKomSID" SG_ 180 HybFeedback_ECM 2130708662;
BA_ "FlexKomIsMotorola" SG_ 180 HybFeedback_ECM 1;
BA_ "FlexKomComment" SG_ 180 HybFeedback_ECM "??";
BA_ "GenSigSNA" SG_ 180 HybTransSt "0h";
BA_ "GenSigCycleTime" SG_ 180 HybTransSt 10;
BA_ "FlexKomSigStartValue" SG_ 180 HybTransSt "000000000000FFh";
BA_ "FlexKomSigStartPos" SG_ 180 HybTransSt 7;
BA_ "FlexKomSigName" SG_ 180 HybTransSt "Hybrid_Status1";
BA_ "FlexKomSigLaenge" SG_ 180 HybTransSt 56;
BA_ "FlexKomSID" SG_ 180 HybTransSt 2130708662;
BA_ "FlexKomIsMotorola" SG_ 180 HybTransSt 1;
BA_ "FlexKomComment" SG_ 180 HybTransSt "??";
BA_ "RID" SG_ 180 MC_0B4h "9806";
BA_ "GenSigSNA" SG_ 180 MC_0B4h "0h";
BA_ "GenSigCycleTime" SG_ 180 MC_0B4h 10;
BA_ "FlexKomSigStartValue" SG_ 180 MC_0B4h "000000000000FFh";
BA_ "FlexKomSigStartPos" SG_ 180 MC_0B4h 7;
BA_ "FlexKomSigName" SG_ 180 MC_0B4h "Hybrid_Status1";
BA_ "FlexKomSigLaenge" SG_ 180 MC_0B4h 56;
BA_ "FlexKomSID" SG_ 180 MC_0B4h 2130708662;
BA_ "FlexKomIsMotorola" SG_ 180 MC_0B4h 1;
BA_ "FlexKomComment" SG_ 180 MC_0B4h "??";
BA_ "GenSigSNA" SG_ 180 PrplsnSysAtv "0h";
BA_ "GenSigCycleTime" SG_ 180 PrplsnSysAtv 10;
BA_ "FlexKomSigStartValue" SG_ 180 PrplsnSysAtv "000000000000FFh";
BA_ "FlexKomSigStartPos" SG_ 180 PrplsnSysAtv 7;
BA_ "FlexKomSigName" SG_ 180 PrplsnSysAtv "Hybrid_Status1";
BA_ "FlexKomSigLaenge" SG_ 180 PrplsnSysAtv 56;
BA_ "FlexKomSID" SG_ 180 PrplsnSysAtv 2130708662;
BA_ "FlexKomIsMotorola" SG_ 180 PrplsnSysAtv 1;
BA_ "FlexKomComment" SG_ 180 PrplsnSysAtv "??";
BA_ "GenSigSNA" SG_ 180 ShftRangeState "Fh";
BA_ "GenSigCycleTime" SG_ 180 ShftRangeState 10;
BA_ "FlexKomSigStartValue" SG_ 180 ShftRangeState "000000000000FFh";
BA_ "FlexKomSigStartPos" SG_ 180 ShftRangeState 7;
BA_ "FlexKomSigName" SG_ 180 ShftRangeState "Hybrid_Status1";
BA_ "FlexKomSigLaenge" SG_ 180 ShftRangeState 56;
BA_ "FlexKomSID" SG_ 180 ShftRangeState 2130708662;
BA_ "FlexKomIsMotorola" SG_ 180 ShftRangeState 1;
BA_ "FlexKomComment" SG_ 180 ShftRangeState "??";
BA_ "GenSigSNA" SG_ 180 TransInpSpdPrfl "0h";
BA_ "GenSigCycleTime" SG_ 180 TransInpSpdPrfl 10;
BA_ "FlexKomSigStartValue" SG_ 180 TransInpSpdPrfl "000000000000FFh";
BA_ "FlexKomSigStartPos" SG_ 180 TransInpSpdPrfl 7;
BA_ "FlexKomSigName" SG_ 180 TransInpSpdPrfl "Hybrid_Status1";
BA_ "FlexKomSigLaenge" SG_ 180 TransInpSpdPrfl 56;
BA_ "FlexKomSID" SG_ 180 TransInpSpdPrfl 2130708662;
BA_ "FlexKomIsMotorola" SG_ 180 TransInpSpdPrfl 1;
BA_ "FlexKomComment" SG_ 180 TransInpSpdPrfl "??";
BA_ "GenSigStartValue" SG_ 471 CRC_1D7h 255;
BA_ "GenSigSNA" SG_ 471 CRC_1D7h "FFh";
BA_ "GenSigCycleTime" SG_ 471 CRC_1D7h 10;
BA_ "FlexKomSigStartValue" SG_ 471 CRC_1D7h "0003AA00000000FFh";
BA_ "FlexKomSigStartPos" SG_ 471 CRC_1D7h 7;
BA_ "FlexKomSigName" SG_ 471 CRC_1D7h "Hybrid_Status2";
BA_ "FlexKomSigLaenge" SG_ 471 CRC_1D7h 64;
BA_ "FlexKomSID" SG_ 471 CRC_1D7h 2130708664;
BA_ "FlexKomIsMotorola" SG_ 471 CRC_1D7h 1;
BA_ "FlexKomComment" SG_ 471 CRC_1D7h ".";
BA_ "GenSigSNA" SG_ 471 EngActDmpgDsblReq "0h";
BA_ "GenSigCycleTime" SG_ 471 EngActDmpgDsblReq 10;
BA_ "FlexKomSigStartValue" SG_ 471 EngActDmpgDsblReq "0003AA00000000FFh";
BA_ "FlexKomSigStartPos" SG_ 471 EngActDmpgDsblReq 7;
BA_ "FlexKomSigName" SG_ 471 EngActDmpgDsblReq "Hybrid_Status2";
BA_ "FlexKomSigLaenge" SG_ 471 EngActDmpgDsblReq 64;
BA_ "FlexKomSID" SG_ 471 EngActDmpgDsblReq 2130708664;
BA_ "FlexKomIsMotorola" SG_ 471 EngActDmpgDsblReq 1;
BA_ "FlexKomComment" SG_ 471 EngActDmpgDsblReq ".";
BA_ "GenSigSNA" SG_ 471 Eng_Off_Allowed "0h";
BA_ "GenSigCycleTime" SG_ 471 Eng_Off_Allowed 10;
BA_ "FlexKomSigStartValue" SG_ 471 Eng_Off_Allowed "0003AA00000000FFh";
BA_ "FlexKomSigStartPos" SG_ 471 Eng_Off_Allowed 7;
BA_ "FlexKomSigName" SG_ 471 Eng_Off_Allowed "Hybrid_Status2";
BA_ "FlexKomSigLaenge" SG_ 471 Eng_Off_Allowed 64;
BA_ "FlexKomSID" SG_ 471 Eng_Off_Allowed 2130708664;
BA_ "FlexKomIsMotorola" SG_ 471 Eng_Off_Allowed 1;
BA_ "FlexKomComment" SG_ 471 Eng_Off_Allowed ".";
BA_ "GenSigSNA" SG_ 471 HEV_ESS_Mode "Fh";
BA_ "GenSigCycleTime" SG_ 471 HEV_ESS_Mode 10;
BA_ "FlexKomSigStartValue" SG_ 471 HEV_ESS_Mode "0003AA00000000FFh";
BA_ "FlexKomSigStartPos" SG_ 471 HEV_ESS_Mode 7;
BA_ "FlexKomSigName" SG_ 471 HEV_ESS_Mode "Hybrid_Status2";
BA_ "FlexKomSigLaenge" SG_ 471 HEV_ESS_Mode 64;
BA_ "FlexKomSID" SG_ 471 HEV_ESS_Mode 2130708664;
BA_ "FlexKomIsMotorola" SG_ 471 HEV_ESS_Mode 1;
BA_ "FlexKomComment" SG_ 471 HEV_ESS_Mode ".";
BA_ "GenSigSNA" SG_ 471 HybGenSPDtyCycPtOverAct "0h";
BA_ "GenSigCycleTime" SG_ 471 HybGenSPDtyCycPtOverAct 10;
BA_ "FlexKomSigStartValue" SG_ 471 HybGenSPDtyCycPtOverAct "0003AA00000000FFh";
BA_ "FlexKomSigStartPos" SG_ 471 HybGenSPDtyCycPtOverAct 7;
BA_ "FlexKomSigName" SG_ 471 HybGenSPDtyCycPtOverAct "Hybrid_Status2";
BA_ "FlexKomSigLaenge" SG_ 471 HybGenSPDtyCycPtOverAct 64;
BA_ "FlexKomSID" SG_ 471 HybGenSPDtyCycPtOverAct 2130708664;
BA_ "FlexKomIsMotorola" SG_ 471 HybGenSPDtyCycPtOverAct 1;
BA_ "FlexKomComment" SG_ 471 HybGenSPDtyCycPtOverAct ".";
BA_ "GenSigSNA" SG_ 471 Hyb_EngStrtStopType "Fh";
BA_ "GenSigCycleTime" SG_ 471 Hyb_EngStrtStopType 10;
BA_ "FlexKomSigStartValue" SG_ 471 Hyb_EngStrtStopType "0003AA00000000FFh";
BA_ "FlexKomSigStartPos" SG_ 471 Hyb_EngStrtStopType 7;
BA_ "FlexKomSigName" SG_ 471 Hyb_EngStrtStopType "Hybrid_Status2";
BA_ "FlexKomSigLaenge" SG_ 471 Hyb_EngStrtStopType 64;
BA_ "FlexKomSID" SG_ 471 Hyb_EngStrtStopType 2130708664;
BA_ "FlexKomIsMotorola" SG_ 471 Hyb_EngStrtStopType 1;
BA_ "FlexKomComment" SG_ 471 Hyb_EngStrtStopType ".";
BA_ "GenSigSNA" SG_ 471 Hybrid_Remedial_Stop "0h";
BA_ "GenSigCycleTime" SG_ 471 Hybrid_Remedial_Stop 10;
BA_ "FlexKomSigStartValue" SG_ 471 Hybrid_Remedial_Stop "0003AA00000000FFh";
BA_ "FlexKomSigStartPos" SG_ 471 Hybrid_Remedial_Stop 7;
BA_ "FlexKomSigName" SG_ 471 Hybrid_Remedial_Stop "Hybrid_Status2";
BA_ "FlexKomSigLaenge" SG_ 471 Hybrid_Remedial_Stop 64;
BA_ "FlexKomSID" SG_ 471 Hybrid_Remedial_Stop 2130708664;
BA_ "FlexKomIsMotorola" SG_ 471 Hybrid_Remedial_Stop 1;
BA_ "FlexKomComment" SG_ 471 Hybrid_Remedial_Stop ".";
BA_ "GenSigSNA" SG_ 471 InputSpdRaw "FFFh";
BA_ "GenSigCycleTime" SG_ 471 InputSpdRaw 10;
BA_ "FlexKomSigStartValue" SG_ 471 InputSpdRaw "0003AA00000000FFh";
BA_ "FlexKomSigStartPos" SG_ 471 InputSpdRaw 7;
BA_ "FlexKomSigName" SG_ 471 InputSpdRaw "Hybrid_Status2";
BA_ "FlexKomSigLaenge" SG_ 471 InputSpdRaw 64;
BA_ "FlexKomSID" SG_ 471 InputSpdRaw 2130708664;
BA_ "FlexKomIsMotorola" SG_ 471 InputSpdRaw 1;
BA_ "FlexKomComment" SG_ 471 InputSpdRaw ".";
BA_ "GenSigSNA" SG_ 471 LowVoltSysFld "0h";
BA_ "GenSigCycleTime" SG_ 471 LowVoltSysFld 10;
BA_ "FlexKomSigStartValue" SG_ 471 LowVoltSysFld "0003AA00000000FFh";
BA_ "FlexKomSigStartPos" SG_ 471 LowVoltSysFld 7;
BA_ "FlexKomSigName" SG_ 471 LowVoltSysFld "Hybrid_Status2";
BA_ "FlexKomSigLaenge" SG_ 471 LowVoltSysFld 64;
BA_ "FlexKomSID" SG_ 471 LowVoltSysFld 2130708664;
BA_ "FlexKomIsMotorola" SG_ 471 LowVoltSysFld 1;
BA_ "FlexKomComment" SG_ 471 LowVoltSysFld ".";
BA_ "GenSigSNA" SG_ 471 MC_1D7h "0h";
BA_ "GenSigCycleTime" SG_ 471 MC_1D7h 10;
BA_ "FlexKomSigStartValue" SG_ 471 MC_1D7h "0003AA00000000FFh";
BA_ "FlexKomSigStartPos" SG_ 471 MC_1D7h 7;
BA_ "FlexKomSigName" SG_ 471 MC_1D7h "Hybrid_Status2";
BA_ "FlexKomSigLaenge" SG_ 471 MC_1D7h 64;
BA_ "FlexKomSID" SG_ 471 MC_1D7h 2130708664;
BA_ "FlexKomIsMotorola" SG_ 471 MC_1D7h 1;
BA_ "FlexKomComment" SG_ 471 MC_1D7h ".";
BA_ "GenSigSNA" SG_ 471 NiTi_Achieved "0h";
BA_ "GenSigCycleTime" SG_ 471 NiTi_Achieved 10;
BA_ "FlexKomSigStartValue" SG_ 471 NiTi_Achieved "0003AA00000000FFh";
BA_ "FlexKomSigStartPos" SG_ 471 NiTi_Achieved 7;
BA_ "FlexKomSigName" SG_ 471 NiTi_Achieved "Hybrid_Status2";
BA_ "FlexKomSigLaenge" SG_ 471 NiTi_Achieved 64;
BA_ "FlexKomSID" SG_ 471 NiTi_Achieved 2130708664;
BA_ "FlexKomIsMotorola" SG_ 471 NiTi_Achieved 1;
BA_ "FlexKomComment" SG_ 471 NiTi_Achieved ".";
BA_ "GenSigSNA" SG_ 769 BFC_Allowedstate "3h";
BA_ "GenSigCycleTime" SG_ 769 BFC_Allowedstate 100;
BA_ "FlexKomSigStartValue" SG_ 769 BFC_Allowedstate "01FFFF0000000000h";
BA_ "FlexKomSigStartPos" SG_ 769 BFC_Allowedstate 7;
BA_ "FlexKomSigName" SG_ 769 BFC_Allowedstate "Hybrid_Status3";
BA_ "FlexKomSigLaenge" SG_ 769 BFC_Allowedstate 64;
BA_ "FlexKomSID" SG_ 769 BFC_Allowedstate 2130708663;
BA_ "FlexKomIsMotorola" SG_ 769 BFC_Allowedstate 1;
BA_ "FlexKomComment" SG_ 769 BFC_Allowedstate ".";
BA_ "GenSigSNA" SG_ 769 BatCoolingFaultSts "Fh";
BA_ "GenSigCycleTime" SG_ 769 BatCoolingFaultSts 100;
BA_ "FlexKomSigStartValue" SG_ 769 BatCoolingFaultSts "01FFFF0000000000h";
BA_ "FlexKomSigStartPos" SG_ 769 BatCoolingFaultSts 7;
BA_ "FlexKomSigName" SG_ 769 BatCoolingFaultSts "Hybrid_Status3";
BA_ "FlexKomSigLaenge" SG_ 769 BatCoolingFaultSts 64;
BA_ "FlexKomSID" SG_ 769 BatCoolingFaultSts 2130708663;
BA_ "FlexKomIsMotorola" SG_ 769 BatCoolingFaultSts 1;
BA_ "FlexKomComment" SG_ 769 BatCoolingFaultSts ".";
BA_ "GenSigSNA" SG_ 769 CRC_301h "0h";
BA_ "GenSigCycleTime" SG_ 769 CRC_301h 100;
BA_ "FlexKomSigStartValue" SG_ 769 CRC_301h "01FFFF0000000000h";
BA_ "FlexKomSigStartPos" SG_ 769 CRC_301h 7;
BA_ "FlexKomSigName" SG_ 769 CRC_301h "Hybrid_Status3";
BA_ "FlexKomSigLaenge" SG_ 769 CRC_301h 64;
BA_ "FlexKomSID" SG_ 769 CRC_301h 2130708663;
BA_ "FlexKomIsMotorola" SG_ 769 CRC_301h 1;
BA_ "FlexKomComment" SG_ 769 CRC_301h ".";
BA_ "GenSigSNA" SG_ 769 ClrLgsDiagInfo "0h";
BA_ "GenSigCycleTime" SG_ 769 ClrLgsDiagInfo 100;
BA_ "FlexKomSigStartValue" SG_ 769 ClrLgsDiagInfo "01FFFF0000000000h";
BA_ "FlexKomSigStartPos" SG_ 769 ClrLgsDiagInfo 7;
BA_ "FlexKomSigName" SG_ 769 ClrLgsDiagInfo "Hybrid_Status3";
BA_ "FlexKomSigLaenge" SG_ 769 ClrLgsDiagInfo 64;
BA_ "FlexKomSID" SG_ 769 ClrLgsDiagInfo 2130708663;
BA_ "FlexKomIsMotorola" SG_ 769 ClrLgsDiagInfo 1;
BA_ "FlexKomComment" SG_ 769 ClrLgsDiagInfo ".";
BA_ "GenSigSNA" SG_ 769 ElectricTrqMult4Pedal "FFh";
BA_ "GenSigCycleTime" SG_ 769 ElectricTrqMult4Pedal 100;
BA_ "FlexKomSigStartValue" SG_ 769 ElectricTrqMult4Pedal "01FFFF0000000000h";
BA_ "FlexKomSigStartPos" SG_ 769 ElectricTrqMult4Pedal 7;
BA_ "FlexKomSigName" SG_ 769 ElectricTrqMult4Pedal "Hybrid_Status3";
BA_ "FlexKomSigLaenge" SG_ 769 ElectricTrqMult4Pedal 64;
BA_ "FlexKomSID" SG_ 769 ElectricTrqMult4Pedal 2130708663;
BA_ "FlexKomIsMotorola" SG_ 769 ElectricTrqMult4Pedal 1;
BA_ "FlexKomComment" SG_ 769 ElectricTrqMult4Pedal ".";
BA_ "GenSigStartValue" SG_ 769 HCPMaxEngRPM 255;
BA_ "GenSigSNA" SG_ 769 HCPMaxEngRPM "FFh";
BA_ "GenSigCycleTime" SG_ 769 HCPMaxEngRPM 100;
BA_ "FlexKomSigStartValue" SG_ 769 HCPMaxEngRPM "01FFFF0000000000h";
BA_ "FlexKomSigStartPos" SG_ 769 HCPMaxEngRPM 7;
BA_ "FlexKomSigName" SG_ 769 HCPMaxEngRPM "Hybrid_Status3";
BA_ "FlexKomSigLaenge" SG_ 769 HCPMaxEngRPM 64;
BA_ "FlexKomSID" SG_ 769 HCPMaxEngRPM 2130708663;
BA_ "FlexKomIsMotorola" SG_ 769 HCPMaxEngRPM 1;
BA_ "FlexKomComment" SG_ 769 HCPMaxEngRPM ".";
BA_ "GenSigSNA" SG_ 769 HCP_MaxCoolingSt "3h";
BA_ "GenSigCycleTime" SG_ 769 HCP_MaxCoolingSt 100;
BA_ "FlexKomSigStartValue" SG_ 769 HCP_MaxCoolingSt "01FFFF0000000000h";
BA_ "FlexKomSigStartPos" SG_ 769 HCP_MaxCoolingSt 7;
BA_ "FlexKomSigName" SG_ 769 HCP_MaxCoolingSt "Hybrid_Status3";
BA_ "FlexKomSigLaenge" SG_ 769 HCP_MaxCoolingSt 64;
BA_ "FlexKomSID" SG_ 769 HCP_MaxCoolingSt 2130708663;
BA_ "FlexKomIsMotorola" SG_ 769 HCP_MaxCoolingSt 1;
BA_ "FlexKomComment" SG_ 769 HCP_MaxCoolingSt ".";
BA_ "GenSigSNA" SG_ 769 HCP_Stop_Start_Fault "0h";
BA_ "GenSigCycleTime" SG_ 769 HCP_Stop_Start_Fault 100;
BA_ "FlexKomSigStartValue" SG_ 769 HCP_Stop_Start_Fault "01FFFF0000000000h";
BA_ "FlexKomSigStartPos" SG_ 769 HCP_Stop_Start_Fault 7;
BA_ "FlexKomSigName" SG_ 769 HCP_Stop_Start_Fault "Hybrid_Status3";
BA_ "FlexKomSigLaenge" SG_ 769 HCP_Stop_Start_Fault 64;
BA_ "FlexKomSID" SG_ 769 HCP_Stop_Start_Fault 2130708663;
BA_ "FlexKomIsMotorola" SG_ 769 HCP_Stop_Start_Fault 1;
BA_ "FlexKomComment" SG_ 769 HCP_Stop_Start_Fault ".";
BA_ "GenSigSNA" SG_ 769 HEV_HybPwrtrnRdcdPerfCmnd "0h";
BA_ "GenSigCycleTime" SG_ 769 HEV_HybPwrtrnRdcdPerfCmnd 100;
BA_ "FlexKomSigStartValue" SG_ 769 HEV_HybPwrtrnRdcdPerfCmnd "01FFFF0000000000h";
BA_ "FlexKomSigStartPos" SG_ 769 HEV_HybPwrtrnRdcdPerfCmnd 7;
BA_ "FlexKomSigName" SG_ 769 HEV_HybPwrtrnRdcdPerfCmnd "Hybrid_Status3";
BA_ "FlexKomSigLaenge" SG_ 769 HEV_HybPwrtrnRdcdPerfCmnd 64;
BA_ "FlexKomSID" SG_ 769 HEV_HybPwrtrnRdcdPerfCmnd 2130708663;
BA_ "FlexKomIsMotorola" SG_ 769 HEV_HybPwrtrnRdcdPerfCmnd 1;
BA_ "FlexKomComment" SG_ 769 HEV_HybPwrtrnRdcdPerfCmnd ".";
BA_ "GenSigStartValue" SG_ 769 IdleCLoopTrq 511;
BA_ "GenSigSNA" SG_ 769 IdleCLoopTrq "3FFh";
BA_ "GenSigCycleTime" SG_ 769 IdleCLoopTrq 100;
BA_ "FlexKomSigStartValue" SG_ 769 IdleCLoopTrq "01FFFF0000000000h";
BA_ "FlexKomSigStartPos" SG_ 769 IdleCLoopTrq 7;
BA_ "FlexKomSigName" SG_ 769 IdleCLoopTrq "Hybrid_Status3";
BA_ "FlexKomSigLaenge" SG_ 769 IdleCLoopTrq 64;
BA_ "FlexKomSID" SG_ 769 IdleCLoopTrq 2130708663;
BA_ "FlexKomIsMotorola" SG_ 769 IdleCLoopTrq 1;
BA_ "FlexKomComment" SG_ 769 IdleCLoopTrq ".";
BA_ "GenSigSNA" SG_ 769 MC_301h "0h";
BA_ "GenSigCycleTime" SG_ 769 MC_301h 100;
BA_ "FlexKomSigStartValue" SG_ 769 MC_301h "01FFFF0000000000h";
BA_ "FlexKomSigStartPos" SG_ 769 MC_301h 7;
BA_ "FlexKomSigName" SG_ 769 MC_301h "Hybrid_Status3";
BA_ "FlexKomSigLaenge" SG_ 769 MC_301h 64;
BA_ "FlexKomSID" SG_ 769 MC_301h 2130708663;
BA_ "FlexKomIsMotorola" SG_ 769 MC_301h 1;
BA_ "FlexKomComment" SG_ 769 MC_301h ".";
BA_ "GenSigSNA" SG_ 276 IMMO_SOP_REQUEST "0h";
BA_ "GenSigSendType" SG_ 276 IMMO_SOP_REQUEST 1;
BA_ "FlexKomSigStartValue" SG_ 276 IMMO_SOP_REQUEST "00h";
BA_ "FlexKomSigStartPos" SG_ 276 IMMO_SOP_REQUEST 7;
BA_ "FlexKomSigName" SG_ 276 IMMO_SOP_REQUEST "IMMO_SOP_REQUEST";
BA_ "FlexKomSigLaenge" SG_ 276 IMMO_SOP_REQUEST 8;
BA_ "FlexKomSID" SG_ 276 IMMO_SOP_REQUEST 2130708928;
BA_ "FlexKomIsMotorola" SG_ 276 IMMO_SOP_REQUEST 1;
BA_ "FlexKomComment" SG_ 276 IMMO_SOP_REQUEST "Signals ECM to initiate Immobilizer handshake.";
BA_ "GenSigSNA" SG_ 720 CRC_MotorB_Status "FFh";
BA_ "GenSigCycleTime" SG_ 720 CRC_MotorB_Status 20;
BA_ "FlexKomSigStartValue" SG_ 720 CRC_MotorB_Status "00000000FFh";
BA_ "FlexKomSigStartPos" SG_ 720 CRC_MotorB_Status 7;
BA_ "FlexKomSigName" SG_ 720 CRC_MotorB_Status "MotorB_Status";
BA_ "FlexKomSigLaenge" SG_ 720 CRC_MotorB_Status 40;
BA_ "FlexKomSID" SG_ 720 CRC_MotorB_Status 9818;
BA_ "FlexKomIsMotorola" SG_ 720 CRC_MotorB_Status 1;
BA_ "FlexKomComment" SG_ 720 CRC_MotorB_Status ".";
BA_ "GenSigSNA" SG_ 720 Mechanical_Counts "0h";
BA_ "GenSigCycleTime" SG_ 720 Mechanical_Counts 20;
BA_ "FlexKomSigStartValue" SG_ 720 Mechanical_Counts "00000000FFh";
BA_ "FlexKomSigStartPos" SG_ 720 Mechanical_Counts 7;
BA_ "FlexKomSigName" SG_ 720 Mechanical_Counts "MotorB_Status";
BA_ "FlexKomSigLaenge" SG_ 720 Mechanical_Counts 40;
BA_ "FlexKomSID" SG_ 720 Mechanical_Counts 9818;
BA_ "FlexKomIsMotorola" SG_ 720 Mechanical_Counts 1;
BA_ "FlexKomComment" SG_ 720 Mechanical_Counts ".";
BA_ "GenSigSNA" SG_ 720 Timestamp "0h";
BA_ "GenSigCycleTime" SG_ 720 Timestamp 20;
BA_ "FlexKomSigStartValue" SG_ 720 Timestamp "00000000FFh";
BA_ "FlexKomSigStartPos" SG_ 720 Timestamp 7;
BA_ "FlexKomSigName" SG_ 720 Timestamp "MotorB_Status";
BA_ "FlexKomSigLaenge" SG_ 720 Timestamp 40;
BA_ "FlexKomSID" SG_ 720 Timestamp 9818;
BA_ "FlexKomIsMotorola" SG_ 720 Timestamp 1;
BA_ "FlexKomComment" SG_ 720 Timestamp ".";
BA_ "RID" SG_ 926 NET_CFG_STAT_ePT "2849";
BA_ "GenSigStartValue" SG_ 926 NET_CFG_STAT_ePT 3;
BA_ "GenSigSNA" SG_ 926 NET_CFG_STAT_ePT "3h";
BA_ "GenSigSendType" SG_ 926 NET_CFG_STAT_ePT 5;
BA_ "GenSigCycleTime" SG_ 926 NET_CFG_STAT_ePT 2000;
BA_ "FlexKomSigStartValue" SG_ 926 NET_CFG_STAT_ePT "030000h";
BA_ "FlexKomSigStartPos" SG_ 926 NET_CFG_STAT_ePT 7;
BA_ "FlexKomSigName" SG_ 926 NET_CFG_STAT_ePT "NET_CFG_DATA_ePT";
BA_ "FlexKomSigLaenge" SG_ 926 NET_CFG_STAT_ePT 24;
BA_ "FlexKomSID" SG_ 926 NET_CFG_STAT_ePT 2130708901;
BA_ "FlexKomIsMotorola" SG_ 926 NET_CFG_STAT_ePT 1;
BA_ "FlexKomComment" SG_ 926 NET_CFG_STAT_ePT "Network ECU config data for hybrid bus";
BA_ "GenSigSNA" SG_ 926 NetCfg_AHCP_ePT "0h";
BA_ "GenSigSendType" SG_ 926 NetCfg_AHCP_ePT 5;
BA_ "GenSigCycleTime" SG_ 926 NetCfg_AHCP_ePT 2000;
BA_ "FlexKomSigStartValue" SG_ 926 NetCfg_AHCP_ePT "030000h";
BA_ "FlexKomSigStartPos" SG_ 926 NetCfg_AHCP_ePT 7;
BA_ "FlexKomSigName" SG_ 926 NetCfg_AHCP_ePT "NET_CFG_DATA_ePT";
BA_ "FlexKomSigLaenge" SG_ 926 NetCfg_AHCP_ePT 24;
BA_ "FlexKomSID" SG_ 926 NetCfg_AHCP_ePT 2130708901;
BA_ "FlexKomIsMotorola" SG_ 926 NetCfg_AHCP_ePT 1;
BA_ "FlexKomComment" SG_ 926 NetCfg_AHCP_ePT "Network ECU config data for hybrid bus";
BA_ "GenSigSNA" SG_ 926 NetCfg_APM_ePT "0h";
BA_ "GenSigSendType" SG_ 926 NetCfg_APM_ePT 5;
BA_ "GenSigCycleTime" SG_ 926 NetCfg_APM_ePT 2000;
BA_ "FlexKomSigStartValue" SG_ 926 NetCfg_APM_ePT "030000h";
BA_ "FlexKomSigStartPos" SG_ 926 NetCfg_APM_ePT 7;
BA_ "FlexKomSigName" SG_ 926 NetCfg_APM_ePT "NET_CFG_DATA_ePT";
BA_ "FlexKomSigLaenge" SG_ 926 NetCfg_APM_ePT 24;
BA_ "FlexKomSID" SG_ 926 NetCfg_APM_ePT 2130708901;
BA_ "FlexKomIsMotorola" SG_ 926 NetCfg_APM_ePT 1;
BA_ "FlexKomComment" SG_ 926 NetCfg_APM_ePT "Network ECU config data for hybrid bus";
BA_ "GenSigSNA" SG_ 926 NetCfg_BPCM_ePT "0h";
BA_ "GenSigSendType" SG_ 926 NetCfg_BPCM_ePT 5;
BA_ "GenSigCycleTime" SG_ 926 NetCfg_BPCM_ePT 2000;
BA_ "FlexKomSigStartValue" SG_ 926 NetCfg_BPCM_ePT "030000h";
BA_ "FlexKomSigStartPos" SG_ 926 NetCfg_BPCM_ePT 7;
BA_ "FlexKomSigName" SG_ 926 NetCfg_BPCM_ePT "NET_CFG_DATA_ePT";
BA_ "FlexKomSigLaenge" SG_ 926 NetCfg_BPCM_ePT 24;
BA_ "FlexKomSID" SG_ 926 NetCfg_BPCM_ePT 2130708901;
BA_ "FlexKomIsMotorola" SG_ 926 NetCfg_BPCM_ePT 1;
BA_ "FlexKomComment" SG_ 926 NetCfg_BPCM_ePT "Network ECU config data for hybrid bus";
BA_ "GenSigSNA" SG_ 926 NetCfg_BSMO_ePT "0h";
BA_ "GenSigSendType" SG_ 926 NetCfg_BSMO_ePT 5;
BA_ "GenSigCycleTime" SG_ 926 NetCfg_BSMO_ePT 2000;
BA_ "FlexKomSigStartValue" SG_ 926 NetCfg_BSMO_ePT "030000h";
BA_ "FlexKomSigStartPos" SG_ 926 NetCfg_BSMO_ePT 7;
BA_ "FlexKomSigName" SG_ 926 NetCfg_BSMO_ePT "NET_CFG_DATA_ePT";
BA_ "FlexKomSigLaenge" SG_ 926 NetCfg_BSMO_ePT 24;
BA_ "FlexKomSID" SG_ 926 NetCfg_BSMO_ePT 2130708901;
BA_ "FlexKomIsMotorola" SG_ 926 NetCfg_BSMO_ePT 1;
BA_ "FlexKomComment" SG_ 926 NetCfg_BSMO_ePT "Network ECU config data for hybrid bus";
BA_ "GenSigSNA" SG_ 926 NetCfg_EAC_ePT "0h";
BA_ "GenSigSendType" SG_ 926 NetCfg_EAC_ePT 5;
BA_ "GenSigCycleTime" SG_ 926 NetCfg_EAC_ePT 2000;
BA_ "FlexKomSigStartValue" SG_ 926 NetCfg_EAC_ePT "030000h";
BA_ "FlexKomSigStartPos" SG_ 926 NetCfg_EAC_ePT 7;
BA_ "FlexKomSigName" SG_ 926 NetCfg_EAC_ePT "NET_CFG_DATA_ePT";
BA_ "FlexKomSigLaenge" SG_ 926 NetCfg_EAC_ePT 24;
BA_ "FlexKomSID" SG_ 926 NetCfg_EAC_ePT 2130708901;
BA_ "FlexKomIsMotorola" SG_ 926 NetCfg_EAC_ePT 1;
BA_ "FlexKomComment" SG_ 926 NetCfg_EAC_ePT "Network ECU config data for hybrid bus";
BA_ "GenSigSNA" SG_ 926 NetCfg_EBCM_ePT "0h";
BA_ "GenSigSendType" SG_ 926 NetCfg_EBCM_ePT 5;
BA_ "GenSigCycleTime" SG_ 926 NetCfg_EBCM_ePT 2000;
BA_ "FlexKomSigStartValue" SG_ 926 NetCfg_EBCM_ePT "030000h";
BA_ "FlexKomSigStartPos" SG_ 926 NetCfg_EBCM_ePT 7;
BA_ "FlexKomSigName" SG_ 926 NetCfg_EBCM_ePT "NET_CFG_DATA_ePT";
BA_ "FlexKomSigLaenge" SG_ 926 NetCfg_EBCM_ePT 24;
BA_ "FlexKomSID" SG_ 926 NetCfg_EBCM_ePT 2130708901;
BA_ "FlexKomIsMotorola" SG_ 926 NetCfg_EBCM_ePT 1;
BA_ "FlexKomComment" SG_ 926 NetCfg_EBCM_ePT "Network ECU config data for hybrid bus";
BA_ "GenSigSNA" SG_ 926 NetCfg_ECM_ePT "0h";
BA_ "GenSigSendType" SG_ 926 NetCfg_ECM_ePT 5;
BA_ "GenSigCycleTime" SG_ 926 NetCfg_ECM_ePT 2000;
BA_ "FlexKomSigStartValue" SG_ 926 NetCfg_ECM_ePT "030000h";
BA_ "FlexKomSigStartPos" SG_ 926 NetCfg_ECM_ePT 7;
BA_ "FlexKomSigName" SG_ 926 NetCfg_ECM_ePT "NET_CFG_DATA_ePT";
BA_ "FlexKomSigLaenge" SG_ 926 NetCfg_ECM_ePT 24;
BA_ "FlexKomSID" SG_ 926 NetCfg_ECM_ePT 2130708901;
BA_ "FlexKomIsMotorola" SG_ 926 NetCfg_ECM_ePT 1;
BA_ "FlexKomComment" SG_ 926 NetCfg_ECM_ePT "Network ECU config data for hybrid bus";
BA_ "GenSigSNA" SG_ 926 NetCfg_ESC_ePT "0h";
BA_ "GenSigSendType" SG_ 926 NetCfg_ESC_ePT 5;
BA_ "GenSigCycleTime" SG_ 926 NetCfg_ESC_ePT 2000;
BA_ "FlexKomSigStartValue" SG_ 926 NetCfg_ESC_ePT "030000h";
BA_ "FlexKomSigStartPos" SG_ 926 NetCfg_ESC_ePT 7;
BA_ "FlexKomSigName" SG_ 926 NetCfg_ESC_ePT "NET_CFG_DATA_ePT";
BA_ "FlexKomSigLaenge" SG_ 926 NetCfg_ESC_ePT 24;
BA_ "FlexKomSID" SG_ 926 NetCfg_ESC_ePT 2130708901;
BA_ "FlexKomIsMotorola" SG_ 926 NetCfg_ESC_ePT 1;
BA_ "FlexKomComment" SG_ 926 NetCfg_ESC_ePT "Network ECU config data for hybrid bus";
BA_ "GenSigSNA" SG_ 926 NetCfg_ESM_ePT "0h";
BA_ "GenSigSendType" SG_ 926 NetCfg_ESM_ePT 5;
BA_ "GenSigCycleTime" SG_ 926 NetCfg_ESM_ePT 2000;
BA_ "FlexKomSigStartValue" SG_ 926 NetCfg_ESM_ePT "030000h";
BA_ "FlexKomSigStartPos" SG_ 926 NetCfg_ESM_ePT 7;
BA_ "FlexKomSigName" SG_ 926 NetCfg_ESM_ePT "NET_CFG_DATA_ePT";
BA_ "FlexKomSigLaenge" SG_ 926 NetCfg_ESM_ePT 24;
BA_ "FlexKomSID" SG_ 926 NetCfg_ESM_ePT 2130708901;
BA_ "FlexKomIsMotorola" SG_ 926 NetCfg_ESM_ePT 1;
BA_ "FlexKomComment" SG_ 926 NetCfg_ESM_ePT "Network ECU config data for hybrid bus";
BA_ "GenSigSNA" SG_ 926 NetCfg_HCP_ePT "0h";
BA_ "GenSigSendType" SG_ 926 NetCfg_HCP_ePT 5;
BA_ "GenSigCycleTime" SG_ 926 NetCfg_HCP_ePT 2000;
BA_ "FlexKomSigStartValue" SG_ 926 NetCfg_HCP_ePT "030000h";
BA_ "FlexKomSigStartPos" SG_ 926 NetCfg_HCP_ePT 7;
BA_ "FlexKomSigName" SG_ 926 NetCfg_HCP_ePT "NET_CFG_DATA_ePT";
BA_ "FlexKomSigLaenge" SG_ 926 NetCfg_HCP_ePT 24;
BA_ "FlexKomSID" SG_ 926 NetCfg_HCP_ePT 2130708901;
BA_ "FlexKomIsMotorola" SG_ 926 NetCfg_HCP_ePT 1;
BA_ "FlexKomComment" SG_ 926 NetCfg_HCP_ePT "Network ECU config data for hybrid bus";
BA_ "GenSigSNA" SG_ 926 NetCfg_OBCM_ePT "0h";
BA_ "GenSigSendType" SG_ 926 NetCfg_OBCM_ePT 5;
BA_ "GenSigCycleTime" SG_ 926 NetCfg_OBCM_ePT 2000;
BA_ "FlexKomSigStartValue" SG_ 926 NetCfg_OBCM_ePT "030000h";
BA_ "FlexKomSigStartPos" SG_ 926 NetCfg_OBCM_ePT 7;
BA_ "FlexKomSigName" SG_ 926 NetCfg_OBCM_ePT "NET_CFG_DATA_ePT";
BA_ "FlexKomSigLaenge" SG_ 926 NetCfg_OBCM_ePT 24;
BA_ "FlexKomSID" SG_ 926 NetCfg_OBCM_ePT 2130708901;
BA_ "FlexKomIsMotorola" SG_ 926 NetCfg_OBCM_ePT 1;
BA_ "FlexKomComment" SG_ 926 NetCfg_OBCM_ePT "Network ECU config data for hybrid bus";
BA_ "GenSigSNA" SG_ 926 NetCfg_ORC_ePT "0h";
BA_ "GenSigSendType" SG_ 926 NetCfg_ORC_ePT 5;
BA_ "GenSigCycleTime" SG_ 926 NetCfg_ORC_ePT 2000;
BA_ "FlexKomSigStartValue" SG_ 926 NetCfg_ORC_ePT "030000h";
BA_ "FlexKomSigStartPos" SG_ 926 NetCfg_ORC_ePT 7;
BA_ "FlexKomSigName" SG_ 926 NetCfg_ORC_ePT "NET_CFG_DATA_ePT";
BA_ "FlexKomSigLaenge" SG_ 926 NetCfg_ORC_ePT 24;
BA_ "FlexKomSID" SG_ 926 NetCfg_ORC_ePT 2130708901;
BA_ "FlexKomIsMotorola" SG_ 926 NetCfg_ORC_ePT 1;
BA_ "FlexKomComment" SG_ 926 NetCfg_ORC_ePT "Network ECU config data for hybrid bus";
BA_ "GenSigSNA" SG_ 926 NetCfg_SCA_ePT "0h";
BA_ "GenSigSendType" SG_ 926 NetCfg_SCA_ePT 5;
BA_ "GenSigCycleTime" SG_ 926 NetCfg_SCA_ePT 2000;
BA_ "FlexKomSigStartValue" SG_ 926 NetCfg_SCA_ePT "030000h";
BA_ "FlexKomSigStartPos" SG_ 926 NetCfg_SCA_ePT 7;
BA_ "FlexKomSigName" SG_ 926 NetCfg_SCA_ePT "NET_CFG_DATA_ePT";
BA_ "FlexKomSigLaenge" SG_ 926 NetCfg_SCA_ePT 24;
BA_ "FlexKomSID" SG_ 926 NetCfg_SCA_ePT 2130708901;
BA_ "FlexKomIsMotorola" SG_ 926 NetCfg_SCA_ePT 1;
BA_ "FlexKomComment" SG_ 926 NetCfg_SCA_ePT "Network ECU config data for hybrid bus";
BA_ "GenSigSNA" SG_ 1066 NM_APM "0h";
BA_ "FlexKomSigStartValue" SG_ 1066 NM_APM "0000000000000000h";
BA_ "FlexKomSigStartPos" SG_ 1066 NM_APM 7;
BA_ "FlexKomSigName" SG_ 1066 NM_APM "NM_APM";
BA_ "FlexKomSigLaenge" SG_ 1066 NM_APM 64;
BA_ "FlexKomSID" SG_ 1066 NM_APM 2130708996;
BA_ "FlexKomIsMotorola" SG_ 1066 NM_APM 1;
BA_ "FlexKomComment" SG_ 1066 NM_APM "Network management only for ePT bus.";
BA_ "GenSigSNA" SG_ 1070 NM_OBCM "0h";
BA_ "FlexKomSigStartValue" SG_ 1070 NM_OBCM "0000000000000000h";
BA_ "FlexKomSigStartPos" SG_ 1070 NM_OBCM 7;
BA_ "FlexKomSigName" SG_ 1070 NM_OBCM "NM_OBCM";
BA_ "FlexKomSigLaenge" SG_ 1070 NM_OBCM 64;
BA_ "FlexKomSID" SG_ 1070 NM_OBCM 2130708995;
BA_ "FlexKomIsMotorola" SG_ 1070 NM_OBCM 1;
BA_ "FlexKomComment" SG_ 1070 NM_OBCM "Network management only for ePT bus.";
BA_ "GenSigSNA" SG_ 777 Charge_Current "3FFh";
BA_ "GenSigCycleTime" SG_ 777 Charge_Current 100;
BA_ "FlexKomSigStartValue" SG_ 777 Charge_Current "0000000000000060h";
BA_ "FlexKomSigStartPos" SG_ 777 Charge_Current 7;
BA_ "FlexKomSigName" SG_ 777 Charge_Current "OBCM_J1772_Data";
BA_ "FlexKomSigLaenge" SG_ 777 Charge_Current 64;
BA_ "FlexKomSID" SG_ 777 Charge_Current 2130708666;
BA_ "FlexKomIsMotorola" SG_ 777 Charge_Current 1;
BA_ "FlexKomComment" SG_ 777 Charge_Current ".";
BA_ "GenSigSNA" SG_ 777 ChrgCurrAvail "3FFh";
BA_ "GenSigCycleTime" SG_ 777 ChrgCurrAvail 100;
BA_ "FlexKomSigStartValue" SG_ 777 ChrgCurrAvail "0000000000000060h";
BA_ "FlexKomSigStartPos" SG_ 777 ChrgCurrAvail 7;
BA_ "FlexKomSigName" SG_ 777 ChrgCurrAvail "OBCM_J1772_Data";
BA_ "FlexKomSigLaenge" SG_ 777 ChrgCurrAvail 64;
BA_ "FlexKomSID" SG_ 777 ChrgCurrAvail 2130708666;
BA_ "FlexKomIsMotorola" SG_ 777 ChrgCurrAvail 1;
BA_ "FlexKomComment" SG_ 777 ChrgCurrAvail ".";
BA_ "GenSigSNA" SG_ 777 ChrgEnbl_Sts "0h";
BA_ "GenSigCycleTime" SG_ 777 ChrgEnbl_Sts 100;
BA_ "FlexKomSigStartValue" SG_ 777 ChrgEnbl_Sts "0000000000000060h";
BA_ "FlexKomSigStartPos" SG_ 777 ChrgEnbl_Sts 7;
BA_ "FlexKomSigName" SG_ 777 ChrgEnbl_Sts "OBCM_J1772_Data";
BA_ "FlexKomSigLaenge" SG_ 777 ChrgEnbl_Sts 64;
BA_ "FlexKomSID" SG_ 777 ChrgEnbl_Sts 2130708666;
BA_ "FlexKomIsMotorola" SG_ 777 ChrgEnbl_Sts 1;
BA_ "FlexKomComment" SG_ 777 ChrgEnbl_Sts ".";
BA_ "GenSigSNA" SG_ 777 EVSE_PilotStat "0h";
BA_ "GenSigCycleTime" SG_ 777 EVSE_PilotStat 100;
BA_ "FlexKomSigStartValue" SG_ 777 EVSE_PilotStat "0000000000000060h";
BA_ "FlexKomSigStartPos" SG_ 777 EVSE_PilotStat 7;
BA_ "FlexKomSigName" SG_ 777 EVSE_PilotStat "OBCM_J1772_Data";
BA_ "FlexKomSigLaenge" SG_ 777 EVSE_PilotStat 64;
BA_ "FlexKomSID" SG_ 777 EVSE_PilotStat 2130708666;
BA_ "FlexKomIsMotorola" SG_ 777 EVSE_PilotStat 1;
BA_ "FlexKomComment" SG_ 777 EVSE_PilotStat ".";
BA_ "GenSigSNA" SG_ 777 J1772Stat "7h";
BA_ "GenSigCycleTime" SG_ 777 J1772Stat 100;
BA_ "FlexKomSigStartValue" SG_ 777 J1772Stat "0000000000000060h";
BA_ "FlexKomSigStartPos" SG_ 777 J1772Stat 7;
BA_ "FlexKomSigName" SG_ 777 J1772Stat "OBCM_J1772_Data";
BA_ "FlexKomSigLaenge" SG_ 777 J1772Stat 64;
BA_ "FlexKomSID" SG_ 777 J1772Stat 2130708666;
BA_ "FlexKomIsMotorola" SG_ 777 J1772Stat 1;
BA_ "FlexKomComment" SG_ 777 J1772Stat ".";
BA_ "GenSigSNA" SG_ 777 J1772_ICA "1FFh";
BA_ "GenSigCycleTime" SG_ 777 J1772_ICA 100;
BA_ "FlexKomSigStartValue" SG_ 777 J1772_ICA "0000000000000060h";
BA_ "FlexKomSigStartPos" SG_ 777 J1772_ICA 7;
BA_ "FlexKomSigName" SG_ 777 J1772_ICA "OBCM_J1772_Data";
BA_ "FlexKomSigLaenge" SG_ 777 J1772_ICA 64;
BA_ "FlexKomSID" SG_ 777 J1772_ICA 2130708666;
BA_ "FlexKomIsMotorola" SG_ 777 J1772_ICA 1;
BA_ "FlexKomComment" SG_ 777 J1772_ICA ".";
BA_ "GenSigSNA" SG_ 777 J1772_S2_Status "0h";
BA_ "GenSigCycleTime" SG_ 777 J1772_S2_Status 100;
BA_ "FlexKomSigStartValue" SG_ 777 J1772_S2_Status "0000000000000060h";
BA_ "FlexKomSigStartPos" SG_ 777 J1772_S2_Status 7;
BA_ "FlexKomSigName" SG_ 777 J1772_S2_Status "OBCM_J1772_Data";
BA_ "FlexKomSigLaenge" SG_ 777 J1772_S2_Status 64;
BA_ "FlexKomSID" SG_ 777 J1772_S2_Status 2130708666;
BA_ "FlexKomIsMotorola" SG_ 777 J1772_S2_Status 1;
BA_ "FlexKomComment" SG_ 777 J1772_S2_Status ".";
BA_ "GenSigSNA" SG_ 777 MIL_OnRq_OBCM "0h";
BA_ "GenSigCycleTime" SG_ 777 MIL_OnRq_OBCM 100;
BA_ "FlexKomSigStartValue" SG_ 777 MIL_OnRq_OBCM "0000000000000060h";
BA_ "FlexKomSigStartPos" SG_ 777 MIL_OnRq_OBCM 7;
BA_ "FlexKomSigName" SG_ 777 MIL_OnRq_OBCM "OBCM_J1772_Data";
BA_ "FlexKomSigLaenge" SG_ 777 MIL_OnRq_OBCM 64;
BA_ "FlexKomSID" SG_ 777 MIL_OnRq_OBCM 2130708666;
BA_ "FlexKomIsMotorola" SG_ 777 MIL_OnRq_OBCM 1;
BA_ "FlexKomComment" SG_ 777 MIL_OnRq_OBCM ".";
BA_ "GenSigSNA" SG_ 777 OBCM_DeratingRsn "0h";
BA_ "GenSigCycleTime" SG_ 777 OBCM_DeratingRsn 100;
BA_ "FlexKomSigStartValue" SG_ 777 OBCM_DeratingRsn "0000000000000060h";
BA_ "FlexKomSigStartPos" SG_ 777 OBCM_DeratingRsn 7;
BA_ "FlexKomSigName" SG_ 777 OBCM_DeratingRsn "OBCM_J1772_Data";
BA_ "FlexKomSigLaenge" SG_ 777 OBCM_DeratingRsn 64;
BA_ "FlexKomSID" SG_ 777 OBCM_DeratingRsn 2130708666;
BA_ "FlexKomIsMotorola" SG_ 777 OBCM_DeratingRsn 1;
BA_ "FlexKomComment" SG_ 777 OBCM_DeratingRsn ".";
BA_ "GenSigStartValue" SG_ 777 ProxStat 3;
BA_ "GenSigSNA" SG_ 777 ProxStat "3h";
BA_ "GenSigCycleTime" SG_ 777 ProxStat 100;
BA_ "FlexKomSigStartValue" SG_ 777 ProxStat "0000000000000060h";
BA_ "FlexKomSigStartPos" SG_ 777 ProxStat 7;
BA_ "FlexKomSigName" SG_ 777 ProxStat "OBCM_J1772_Data";
BA_ "FlexKomSigLaenge" SG_ 777 ProxStat 64;
BA_ "FlexKomSID" SG_ 777 ProxStat 2130708666;
BA_ "FlexKomIsMotorola" SG_ 777 ProxStat 1;
BA_ "FlexKomComment" SG_ 777 ProxStat ".";
BA_ "GenSigSNA" SG_ 277 OBCM_CalChar "FFh";
BA_ "GenSigCycleTime" SG_ 277 OBCM_CalChar 100;
BA_ "FlexKomSigStartValue" SG_ 277 OBCM_CalChar "0000000000000000h";
BA_ "FlexKomSigStartPos" SG_ 277 OBCM_CalChar 7;
BA_ "FlexKomSigName" SG_ 277 OBCM_CalChar "OBCM_OBD_DTC";
BA_ "FlexKomSigLaenge" SG_ 277 OBCM_CalChar 64;
BA_ "FlexKomSID" SG_ 277 OBCM_CalChar 2130708709;
BA_ "FlexKomIsMotorola" SG_ 277 OBCM_CalChar 1;
BA_ "FlexKomComment" SG_ 277 OBCM_CalChar "Support OBD II strategy";
BA_ "GenSigSNA" SG_ 277 OBCM_Cal_ID_Idx "3Fh";
BA_ "GenSigCycleTime" SG_ 277 OBCM_Cal_ID_Idx 100;
BA_ "FlexKomSigStartValue" SG_ 277 OBCM_Cal_ID_Idx "0000000000000000h";
BA_ "FlexKomSigStartPos" SG_ 277 OBCM_Cal_ID_Idx 7;
BA_ "FlexKomSigName" SG_ 277 OBCM_Cal_ID_Idx "OBCM_OBD_DTC";
BA_ "FlexKomSigLaenge" SG_ 277 OBCM_Cal_ID_Idx 64;
BA_ "FlexKomSID" SG_ 277 OBCM_Cal_ID_Idx 2130708709;
BA_ "FlexKomIsMotorola" SG_ 277 OBCM_Cal_ID_Idx 1;
BA_ "FlexKomComment" SG_ 277 OBCM_Cal_ID_Idx "Support OBD II strategy";
BA_ "GenSigSNA" SG_ 277 OBCM_DTC_Idx1 "0h";
BA_ "GenSigCycleTime" SG_ 277 OBCM_DTC_Idx1 100;
BA_ "FlexKomSigStartValue" SG_ 277 OBCM_DTC_Idx1 "0000000000000000h";
BA_ "FlexKomSigStartPos" SG_ 277 OBCM_DTC_Idx1 7;
BA_ "FlexKomSigName" SG_ 277 OBCM_DTC_Idx1 "OBCM_OBD_DTC";
BA_ "FlexKomSigLaenge" SG_ 277 OBCM_DTC_Idx1 64;
BA_ "FlexKomSID" SG_ 277 OBCM_DTC_Idx1 2130708709;
BA_ "FlexKomIsMotorola" SG_ 277 OBCM_DTC_Idx1 1;
BA_ "FlexKomComment" SG_ 277 OBCM_DTC_Idx1 "Support OBD II strategy";
BA_ "GenSigSNA" SG_ 277 OBCM_DTC_Idx2 "0h";
BA_ "GenSigCycleTime" SG_ 277 OBCM_DTC_Idx2 100;
BA_ "FlexKomSigStartValue" SG_ 277 OBCM_DTC_Idx2 "0000000000000000h";
BA_ "FlexKomSigStartPos" SG_ 277 OBCM_DTC_Idx2 7;
BA_ "FlexKomSigName" SG_ 277 OBCM_DTC_Idx2 "OBCM_OBD_DTC";
BA_ "FlexKomSigLaenge" SG_ 277 OBCM_DTC_Idx2 64;
BA_ "FlexKomSID" SG_ 277 OBCM_DTC_Idx2 2130708709;
BA_ "FlexKomIsMotorola" SG_ 277 OBCM_DTC_Idx2 1;
BA_ "FlexKomComment" SG_ 277 OBCM_DTC_Idx2 "Support OBD II strategy";
BA_ "GenSigSNA" SG_ 277 OBCM_DTC_Stat1 "7h";
BA_ "GenSigCycleTime" SG_ 277 OBCM_DTC_Stat1 100;
BA_ "FlexKomSigStartValue" SG_ 277 OBCM_DTC_Stat1 "0000000000000000h";
BA_ "FlexKomSigStartPos" SG_ 277 OBCM_DTC_Stat1 7;
BA_ "FlexKomSigName" SG_ 277 OBCM_DTC_Stat1 "OBCM_OBD_DTC";
BA_ "FlexKomSigLaenge" SG_ 277 OBCM_DTC_Stat1 64;
BA_ "FlexKomSID" SG_ 277 OBCM_DTC_Stat1 2130708709;
BA_ "FlexKomIsMotorola" SG_ 277 OBCM_DTC_Stat1 1;
BA_ "FlexKomComment" SG_ 277 OBCM_DTC_Stat1 "Support OBD II strategy";
BA_ "GenSigSNA" SG_ 277 OBCM_DTC_Stat2 "7h";
BA_ "GenSigCycleTime" SG_ 277 OBCM_DTC_Stat2 100;
BA_ "FlexKomSigStartValue" SG_ 277 OBCM_DTC_Stat2 "0000000000000000h";
BA_ "FlexKomSigStartPos" SG_ 277 OBCM_DTC_Stat2 7;
BA_ "FlexKomSigName" SG_ 277 OBCM_DTC_Stat2 "OBCM_OBD_DTC";
BA_ "FlexKomSigLaenge" SG_ 277 OBCM_DTC_Stat2 64;
BA_ "FlexKomSID" SG_ 277 OBCM_DTC_Stat2 2130708709;
BA_ "FlexKomIsMotorola" SG_ 277 OBCM_DTC_Stat2 1;
BA_ "FlexKomComment" SG_ 277 OBCM_DTC_Stat2 "Support OBD II strategy";
BA_ "GenSigSNA" SG_ 976 ChrgFailSts "7h";
BA_ "GenSigCycleTime" SG_ 976 ChrgFailSts 500;
BA_ "FlexKomSigStartValue" SG_ 976 ChrgFailSts "0000000000000000h";
BA_ "FlexKomSigStartPos" SG_ 976 ChrgFailSts 7;
BA_ "FlexKomSigName" SG_ 976 ChrgFailSts "OBCM_Operating_Data";
BA_ "FlexKomSigLaenge" SG_ 976 ChrgFailSts 64;
BA_ "FlexKomSID" SG_ 976 ChrgFailSts 2130708668;
BA_ "FlexKomIsMotorola" SG_ 976 ChrgFailSts 1;
BA_ "FlexKomComment" SG_ 976 ChrgFailSts ".";
BA_ "GenSigSNA" SG_ 976 OBCM_Charger_Ready "3h";
BA_ "GenSigCycleTime" SG_ 976 OBCM_Charger_Ready 500;
BA_ "FlexKomSigStartValue" SG_ 976 OBCM_Charger_Ready "0000000000000000h";
BA_ "FlexKomSigStartPos" SG_ 976 OBCM_Charger_Ready 7;
BA_ "FlexKomSigName" SG_ 976 OBCM_Charger_Ready "OBCM_Operating_Data";
BA_ "FlexKomSigLaenge" SG_ 976 OBCM_Charger_Ready 64;
BA_ "FlexKomSID" SG_ 976 OBCM_Charger_Ready 2130708668;
BA_ "FlexKomIsMotorola" SG_ 976 OBCM_Charger_Ready 1;
BA_ "FlexKomComment" SG_ 976 OBCM_Charger_Ready ".";
BA_ "GenSigSNA" SG_ 976 OBCM_FaultRsn "7Fh";
BA_ "GenSigCycleTime" SG_ 976 OBCM_FaultRsn 500;
BA_ "FlexKomSigStartValue" SG_ 976 OBCM_FaultRsn "0000000000000000h";
BA_ "FlexKomSigStartPos" SG_ 976 OBCM_FaultRsn 7;
BA_ "FlexKomSigName" SG_ 976 OBCM_FaultRsn "OBCM_Operating_Data";
BA_ "FlexKomSigLaenge" SG_ 976 OBCM_FaultRsn 64;
BA_ "FlexKomSID" SG_ 976 OBCM_FaultRsn 2130708668;
BA_ "FlexKomIsMotorola" SG_ 976 OBCM_FaultRsn 1;
BA_ "FlexKomComment" SG_ 976 OBCM_FaultRsn ".";
BA_ "GenSigSNA" SG_ 976 OBCM_WU_Reason "0h";
BA_ "GenSigCycleTime" SG_ 976 OBCM_WU_Reason 500;
BA_ "FlexKomSigStartValue" SG_ 976 OBCM_WU_Reason "0000000000000000h";
BA_ "FlexKomSigStartPos" SG_ 976 OBCM_WU_Reason 7;
BA_ "FlexKomSigName" SG_ 976 OBCM_WU_Reason "OBCM_Operating_Data";
BA_ "FlexKomSigLaenge" SG_ 976 OBCM_WU_Reason 64;
BA_ "FlexKomSID" SG_ 976 OBCM_WU_Reason 2130708668;
BA_ "FlexKomIsMotorola" SG_ 976 OBCM_WU_Reason 1;
BA_ "FlexKomComment" SG_ 976 OBCM_WU_Reason ".";
BA_ "GenSigSNA" SG_ 976 OBC_Md "0h";
BA_ "GenSigCycleTime" SG_ 976 OBC_Md 500;
BA_ "FlexKomSigStartValue" SG_ 976 OBC_Md "0000000000000000h";
BA_ "FlexKomSigStartPos" SG_ 976 OBC_Md 7;
BA_ "FlexKomSigName" SG_ 976 OBC_Md "OBCM_Operating_Data";
BA_ "FlexKomSigLaenge" SG_ 976 OBC_Md 64;
BA_ "FlexKomSID" SG_ 976 OBC_Md 2130708668;
BA_ "FlexKomIsMotorola" SG_ 976 OBC_Md 1;
BA_ "FlexKomComment" SG_ 976 OBC_Md ".";
BA_ "GenSigSNA" SG_ 976 WHrAC "FFFFh";
BA_ "GenSigCycleTime" SG_ 976 WHrAC 500;
BA_ "FlexKomSigStartValue" SG_ 976 WHrAC "0000000000000000h";
BA_ "FlexKomSigStartPos" SG_ 976 WHrAC 7;
BA_ "FlexKomSigName" SG_ 976 WHrAC "OBCM_Operating_Data";
BA_ "FlexKomSigLaenge" SG_ 976 WHrAC 64;
BA_ "FlexKomSID" SG_ 976 WHrAC 2130708668;
BA_ "FlexKomIsMotorola" SG_ 976 WHrAC 1;
BA_ "FlexKomComment" SG_ 976 WHrAC ".";
BA_ "GenSigSNA" SG_ 976 WHrChrg "FFFFh";
BA_ "GenSigCycleTime" SG_ 976 WHrChrg 500;
BA_ "FlexKomSigStartValue" SG_ 976 WHrChrg "0000000000000000h";
BA_ "FlexKomSigStartPos" SG_ 976 WHrChrg 7;
BA_ "FlexKomSigName" SG_ 976 WHrChrg "OBCM_Operating_Data";
BA_ "FlexKomSigLaenge" SG_ 976 WHrChrg 64;
BA_ "FlexKomSID" SG_ 976 WHrChrg 2130708668;
BA_ "FlexKomIsMotorola" SG_ 976 WHrChrg 1;
BA_ "FlexKomComment" SG_ 976 WHrChrg ".";
BA_ "GenSigSNA" SG_ 776 ACSideCurr "3FFh";
BA_ "GenSigCycleTime" SG_ 776 ACSideCurr 100;
BA_ "FlexKomSigStartValue" SG_ 776 ACSideCurr "0000000014000000h";
BA_ "FlexKomSigStartPos" SG_ 776 ACSideCurr 7;
BA_ "FlexKomSigName" SG_ 776 ACSideCurr "OBCM_Power_Data";
BA_ "FlexKomSigLaenge" SG_ 776 ACSideCurr 64;
BA_ "FlexKomSID" SG_ 776 ACSideCurr 2130708665;
BA_ "FlexKomIsMotorola" SG_ 776 ACSideCurr 1;
BA_ "FlexKomComment" SG_ 776 ACSideCurr ".";
BA_ "GenSigSNA" SG_ 776 ACSideVolt "FFFh";
BA_ "GenSigCycleTime" SG_ 776 ACSideVolt 100;
BA_ "FlexKomSigStartValue" SG_ 776 ACSideVolt "0000000014000000h";
BA_ "FlexKomSigStartPos" SG_ 776 ACSideVolt 7;
BA_ "FlexKomSigName" SG_ 776 ACSideVolt "OBCM_Power_Data";
BA_ "FlexKomSigLaenge" SG_ 776 ACSideVolt 64;
BA_ "FlexKomSID" SG_ 776 ACSideVolt 2130708665;
BA_ "FlexKomIsMotorola" SG_ 776 ACSideVolt 1;
BA_ "FlexKomComment" SG_ 776 ACSideVolt ".";
BA_ "GenSigSNA" SG_ 776 AC_LdWarn "0h";
BA_ "GenSigCycleTime" SG_ 776 AC_LdWarn 100;
BA_ "FlexKomSigStartValue" SG_ 776 AC_LdWarn "0000000014000000h";
BA_ "FlexKomSigStartPos" SG_ 776 AC_LdWarn 7;
BA_ "FlexKomSigName" SG_ 776 AC_LdWarn "OBCM_Power_Data";
BA_ "FlexKomSigLaenge" SG_ 776 AC_LdWarn 64;
BA_ "FlexKomSID" SG_ 776 AC_LdWarn 2130708665;
BA_ "FlexKomIsMotorola" SG_ 776 AC_LdWarn 1;
BA_ "FlexKomComment" SG_ 776 AC_LdWarn ".";
BA_ "GenSigSNA" SG_ 776 AC_LnFuse "0h";
BA_ "GenSigCycleTime" SG_ 776 AC_LnFuse 100;
BA_ "FlexKomSigStartValue" SG_ 776 AC_LnFuse "0000000014000000h";
BA_ "FlexKomSigStartPos" SG_ 776 AC_LnFuse 7;
BA_ "FlexKomSigName" SG_ 776 AC_LnFuse "OBCM_Power_Data";
BA_ "FlexKomSigLaenge" SG_ 776 AC_LnFuse 64;
BA_ "FlexKomSID" SG_ 776 AC_LnFuse 2130708665;
BA_ "FlexKomIsMotorola" SG_ 776 AC_LnFuse 1;
BA_ "FlexKomComment" SG_ 776 AC_LnFuse ".";
BA_ "GenSigSNA" SG_ 776 AC_LnHi "0h";
BA_ "GenSigCycleTime" SG_ 776 AC_LnHi 100;
BA_ "FlexKomSigStartValue" SG_ 776 AC_LnHi "0000000014000000h";
BA_ "FlexKomSigStartPos" SG_ 776 AC_LnHi 7;
BA_ "FlexKomSigName" SG_ 776 AC_LnHi "OBCM_Power_Data";
BA_ "FlexKomSigLaenge" SG_ 776 AC_LnHi 64;
BA_ "FlexKomSID" SG_ 776 AC_LnHi 2130708665;
BA_ "FlexKomIsMotorola" SG_ 776 AC_LnHi 1;
BA_ "FlexKomComment" SG_ 776 AC_LnHi ".";
BA_ "GenSigSNA" SG_ 776 AC_LnLow "0h";
BA_ "GenSigCycleTime" SG_ 776 AC_LnLow 100;
BA_ "FlexKomSigStartValue" SG_ 776 AC_LnLow "0000000014000000h";
BA_ "FlexKomSigStartPos" SG_ 776 AC_LnLow 7;
BA_ "FlexKomSigName" SG_ 776 AC_LnLow "OBCM_Power_Data";
BA_ "FlexKomSigLaenge" SG_ 776 AC_LnLow 64;
BA_ "FlexKomSID" SG_ 776 AC_LnLow 2130708665;
BA_ "FlexKomIsMotorola" SG_ 776 AC_LnLow 1;
BA_ "FlexKomComment" SG_ 776 AC_LnLow ".";
BA_ "GenSigSNA" SG_ 776 BattNotDetctd "0h";
BA_ "GenSigCycleTime" SG_ 776 BattNotDetctd 100;
BA_ "FlexKomSigStartValue" SG_ 776 BattNotDetctd "0000000014000000h";
BA_ "FlexKomSigStartPos" SG_ 776 BattNotDetctd 7;
BA_ "FlexKomSigName" SG_ 776 BattNotDetctd "OBCM_Power_Data";
BA_ "FlexKomSigLaenge" SG_ 776 BattNotDetctd 64;
BA_ "FlexKomSID" SG_ 776 BattNotDetctd 2130708665;
BA_ "FlexKomIsMotorola" SG_ 776 BattNotDetctd 1;
BA_ "FlexKomComment" SG_ 776 BattNotDetctd ".";
BA_ "GenSigSNA" SG_ 776 BattSideCurr "3FFh";
BA_ "GenSigCycleTime" SG_ 776 BattSideCurr 100;
BA_ "FlexKomSigStartValue" SG_ 776 BattSideCurr "0000000014000000h";
BA_ "FlexKomSigStartPos" SG_ 776 BattSideCurr 7;
BA_ "FlexKomSigName" SG_ 776 BattSideCurr "OBCM_Power_Data";
BA_ "FlexKomSigLaenge" SG_ 776 BattSideCurr 64;
BA_ "FlexKomSID" SG_ 776 BattSideCurr 2130708665;
BA_ "FlexKomIsMotorola" SG_ 776 BattSideCurr 1;
BA_ "FlexKomComment" SG_ 776 BattSideCurr ".";
BA_ "GenSigSNA" SG_ 776 BattSideVolt "FFFh";
BA_ "GenSigCycleTime" SG_ 776 BattSideVolt 100;
BA_ "FlexKomSigStartValue" SG_ 776 BattSideVolt "0000000014000000h";
BA_ "FlexKomSigStartPos" SG_ 776 BattSideVolt 7;
BA_ "FlexKomSigName" SG_ 776 BattSideVolt "OBCM_Power_Data";
BA_ "FlexKomSigLaenge" SG_ 776 BattSideVolt 64;
BA_ "FlexKomSID" SG_ 776 BattSideVolt 2130708665;
BA_ "FlexKomIsMotorola" SG_ 776 BattSideVolt 1;
BA_ "FlexKomComment" SG_ 776 BattSideVolt ".";
BA_ "GenSigSNA" SG_ 776 BattVltOvrMax "0h";
BA_ "GenSigCycleTime" SG_ 776 BattVltOvrMax 100;
BA_ "FlexKomSigStartValue" SG_ 776 BattVltOvrMax "0000000014000000h";
BA_ "FlexKomSigStartPos" SG_ 776 BattVltOvrMax 7;
BA_ "FlexKomSigName" SG_ 776 BattVltOvrMax "OBCM_Power_Data";
BA_ "FlexKomSigLaenge" SG_ 776 BattVltOvrMax 64;
BA_ "FlexKomSID" SG_ 776 BattVltOvrMax 2130708665;
BA_ "FlexKomIsMotorola" SG_ 776 BattVltOvrMax 1;
BA_ "FlexKomComment" SG_ 776 BattVltOvrMax ".";
BA_ "GenSigSNA" SG_ 776 BattVltUndrMin "0h";
BA_ "GenSigCycleTime" SG_ 776 BattVltUndrMin 100;
BA_ "FlexKomSigStartValue" SG_ 776 BattVltUndrMin "0000000014000000h";
BA_ "FlexKomSigStartPos" SG_ 776 BattVltUndrMin 7;
BA_ "FlexKomSigName" SG_ 776 BattVltUndrMin "OBCM_Power_Data";
BA_ "FlexKomSigLaenge" SG_ 776 BattVltUndrMin 64;
BA_ "FlexKomSID" SG_ 776 BattVltUndrMin 2130708665;
BA_ "FlexKomIsMotorola" SG_ 776 BattVltUndrMin 1;
BA_ "FlexKomComment" SG_ 776 BattVltUndrMin ".";
BA_ "GenSigSNA" SG_ 776 HV_OC "0h";
BA_ "GenSigCycleTime" SG_ 776 HV_OC 100;
BA_ "FlexKomSigStartValue" SG_ 776 HV_OC "0000000014000000h";
BA_ "FlexKomSigStartPos" SG_ 776 HV_OC 7;
BA_ "FlexKomSigName" SG_ 776 HV_OC "OBCM_Power_Data";
BA_ "FlexKomSigLaenge" SG_ 776 HV_OC 64;
BA_ "FlexKomSID" SG_ 776 HV_OC 2130708665;
BA_ "FlexKomIsMotorola" SG_ 776 HV_OC 1;
BA_ "FlexKomComment" SG_ 776 HV_OC ".";
BA_ "GenSigSNA" SG_ 776 HV_OV "0h";
BA_ "GenSigCycleTime" SG_ 776 HV_OV 100;
BA_ "FlexKomSigStartValue" SG_ 776 HV_OV "0000000014000000h";
BA_ "FlexKomSigStartPos" SG_ 776 HV_OV 7;
BA_ "FlexKomSigName" SG_ 776 HV_OV "OBCM_Power_Data";
BA_ "FlexKomSigLaenge" SG_ 776 HV_OV 64;
BA_ "FlexKomSID" SG_ 776 HV_OV 2130708665;
BA_ "FlexKomIsMotorola" SG_ 776 HV_OV 1;
BA_ "FlexKomComment" SG_ 776 HV_OV ".";
BA_ "GenSigSNA" SG_ 776 OBCM_Status_AC_Present "0h";
BA_ "GenSigCycleTime" SG_ 776 OBCM_Status_AC_Present 100;
BA_ "FlexKomSigStartValue" SG_ 776 OBCM_Status_AC_Present "0000000014000000h";
BA_ "FlexKomSigStartPos" SG_ 776 OBCM_Status_AC_Present 7;
BA_ "FlexKomSigName" SG_ 776 OBCM_Status_AC_Present "OBCM_Power_Data";
BA_ "FlexKomSigLaenge" SG_ 776 OBCM_Status_AC_Present 64;
BA_ "FlexKomSID" SG_ 776 OBCM_Status_AC_Present 2130708665;
BA_ "FlexKomIsMotorola" SG_ 776 OBCM_Status_AC_Present 1;
BA_ "FlexKomComment" SG_ 776 OBCM_Status_AC_Present ".";
BA_ "GenSigStartValue" SG_ 776 VoltFreq60 1;
BA_ "GenSigSNA" SG_ 776 VoltFreq60 "1h";
BA_ "GenSigCycleTime" SG_ 776 VoltFreq60 100;
BA_ "FlexKomSigStartValue" SG_ 776 VoltFreq60 "0000000014000000h";
BA_ "FlexKomSigStartPos" SG_ 776 VoltFreq60 7;
BA_ "FlexKomSigName" SG_ 776 VoltFreq60 "OBCM_Power_Data";
BA_ "FlexKomSigLaenge" SG_ 776 VoltFreq60 64;
BA_ "FlexKomSID" SG_ 776 VoltFreq60 2130708665;
BA_ "FlexKomIsMotorola" SG_ 776 VoltFreq60 1;
BA_ "FlexKomComment" SG_ 776 VoltFreq60 ".";
BA_ "GenSigStartValue" SG_ 776 VoltTypAC 1;
BA_ "GenSigSNA" SG_ 776 VoltTypAC "1h";
BA_ "GenSigCycleTime" SG_ 776 VoltTypAC 100;
BA_ "FlexKomSigStartValue" SG_ 776 VoltTypAC "0000000014000000h";
BA_ "FlexKomSigStartPos" SG_ 776 VoltTypAC 7;
BA_ "FlexKomSigName" SG_ 776 VoltTypAC "OBCM_Power_Data";
BA_ "FlexKomSigLaenge" SG_ 776 VoltTypAC 64;
BA_ "FlexKomSID" SG_ 776 VoltTypAC 2130708665;
BA_ "FlexKomIsMotorola" SG_ 776 VoltTypAC 1;
BA_ "FlexKomComment" SG_ 776 VoltTypAC ".";
BA_ "GenSigSNA" SG_ 979 NTC1_OT "0h";
BA_ "GenSigCycleTime" SG_ 979 NTC1_OT 1000;
BA_ "FlexKomSigStartValue" SG_ 979 NTC1_OT "000000000000h";
BA_ "FlexKomSigStartPos" SG_ 979 NTC1_OT 7;
BA_ "FlexKomSigName" SG_ 979 NTC1_OT "OBCM_Temperature_Data";
BA_ "FlexKomSigLaenge" SG_ 979 NTC1_OT 48;
BA_ "FlexKomSID" SG_ 979 NTC1_OT 2130708669;
BA_ "FlexKomIsMotorola" SG_ 979 NTC1_OT 1;
BA_ "FlexKomComment" SG_ 979 NTC1_OT ".";
BA_ "GenSigSNA" SG_ 979 NTC2_OT "0h";
BA_ "GenSigCycleTime" SG_ 979 NTC2_OT 1000;
BA_ "FlexKomSigStartValue" SG_ 979 NTC2_OT "000000000000h";
BA_ "FlexKomSigStartPos" SG_ 979 NTC2_OT 7;
BA_ "FlexKomSigName" SG_ 979 NTC2_OT "OBCM_Temperature_Data";
BA_ "FlexKomSigLaenge" SG_ 979 NTC2_OT 48;
BA_ "FlexKomSID" SG_ 979 NTC2_OT 2130708669;
BA_ "FlexKomIsMotorola" SG_ 979 NTC2_OT 1;
BA_ "FlexKomComment" SG_ 979 NTC2_OT ".";
BA_ "GenSigSNA" SG_ 979 NTC3_OT "0h";
BA_ "GenSigCycleTime" SG_ 979 NTC3_OT 1000;
BA_ "FlexKomSigStartValue" SG_ 979 NTC3_OT "000000000000h";
BA_ "FlexKomSigStartPos" SG_ 979 NTC3_OT 7;
BA_ "FlexKomSigName" SG_ 979 NTC3_OT "OBCM_Temperature_Data";
BA_ "FlexKomSigLaenge" SG_ 979 NTC3_OT 48;
BA_ "FlexKomSID" SG_ 979 NTC3_OT 2130708669;
BA_ "FlexKomIsMotorola" SG_ 979 NTC3_OT 1;
BA_ "FlexKomComment" SG_ 979 NTC3_OT ".";
BA_ "GenSigSNA" SG_ 979 NTC4_OT "0h";
BA_ "GenSigCycleTime" SG_ 979 NTC4_OT 1000;
BA_ "FlexKomSigStartValue" SG_ 979 NTC4_OT "000000000000h";
BA_ "FlexKomSigStartPos" SG_ 979 NTC4_OT 7;
BA_ "FlexKomSigName" SG_ 979 NTC4_OT "OBCM_Temperature_Data";
BA_ "FlexKomSigLaenge" SG_ 979 NTC4_OT 48;
BA_ "FlexKomSID" SG_ 979 NTC4_OT 2130708669;
BA_ "FlexKomIsMotorola" SG_ 979 NTC4_OT 1;
BA_ "FlexKomComment" SG_ 979 NTC4_OT ".";
BA_ "GenSigSNA" SG_ 979 OBCMTemp1 "FFh";
BA_ "GenSigCycleTime" SG_ 979 OBCMTemp1 1000;
BA_ "FlexKomSigStartValue" SG_ 979 OBCMTemp1 "000000000000h";
BA_ "FlexKomSigStartPos" SG_ 979 OBCMTemp1 7;
BA_ "FlexKomSigName" SG_ 979 OBCMTemp1 "OBCM_Temperature_Data";
BA_ "FlexKomSigLaenge" SG_ 979 OBCMTemp1 48;
BA_ "FlexKomSID" SG_ 979 OBCMTemp1 2130708669;
BA_ "FlexKomIsMotorola" SG_ 979 OBCMTemp1 1;
BA_ "FlexKomComment" SG_ 979 OBCMTemp1 ".";
BA_ "GenSigSNA" SG_ 979 OBCMTemp2 "FFh";
BA_ "GenSigCycleTime" SG_ 979 OBCMTemp2 1000;
BA_ "FlexKomSigStartValue" SG_ 979 OBCMTemp2 "000000000000h";
BA_ "FlexKomSigStartPos" SG_ 979 OBCMTemp2 7;
BA_ "FlexKomSigName" SG_ 979 OBCMTemp2 "OBCM_Temperature_Data";
BA_ "FlexKomSigLaenge" SG_ 979 OBCMTemp2 48;
BA_ "FlexKomSID" SG_ 979 OBCMTemp2 2130708669;
BA_ "FlexKomIsMotorola" SG_ 979 OBCMTemp2 1;
BA_ "FlexKomComment" SG_ 979 OBCMTemp2 ".";
BA_ "GenSigSNA" SG_ 979 OBCMTemp3 "FFh";
BA_ "GenSigCycleTime" SG_ 979 OBCMTemp3 1000;
BA_ "FlexKomSigStartValue" SG_ 979 OBCMTemp3 "000000000000h";
BA_ "FlexKomSigStartPos" SG_ 979 OBCMTemp3 7;
BA_ "FlexKomSigName" SG_ 979 OBCMTemp3 "OBCM_Temperature_Data";
BA_ "FlexKomSigLaenge" SG_ 979 OBCMTemp3 48;
BA_ "FlexKomSID" SG_ 979 OBCMTemp3 2130708669;
BA_ "FlexKomIsMotorola" SG_ 979 OBCMTemp3 1;
BA_ "FlexKomComment" SG_ 979 OBCMTemp3 ".";
BA_ "GenSigSNA" SG_ 979 OBCMTemp4 "FFh";
BA_ "GenSigCycleTime" SG_ 979 OBCMTemp4 1000;
BA_ "FlexKomSigStartValue" SG_ 979 OBCMTemp4 "000000000000h";
BA_ "FlexKomSigStartPos" SG_ 979 OBCMTemp4 7;
BA_ "FlexKomSigName" SG_ 979 OBCMTemp4 "OBCM_Temperature_Data";
BA_ "FlexKomSigLaenge" SG_ 979 OBCMTemp4 48;
BA_ "FlexKomSID" SG_ 979 OBCMTemp4 2130708669;
BA_ "FlexKomIsMotorola" SG_ 979 OBCMTemp4 1;
BA_ "FlexKomComment" SG_ 979 OBCMTemp4 ".";
BA_ "GenSigSNA" SG_ 980 OBC_ChrgTm "FFFFh";
BA_ "GenSigCycleTime" SG_ 980 OBC_ChrgTm 1000;
BA_ "FlexKomSigStartValue" SG_ 980 OBC_ChrgTm "0000000000000000h";
BA_ "FlexKomSigStartPos" SG_ 980 OBC_ChrgTm 7;
BA_ "FlexKomSigName" SG_ 980 OBC_ChrgTm "OBCM_Timer_Data";
BA_ "FlexKomSigLaenge" SG_ 980 OBC_ChrgTm 64;
BA_ "FlexKomSID" SG_ 980 OBC_ChrgTm 2130708670;
BA_ "FlexKomIsMotorola" SG_ 980 OBC_ChrgTm 1;
BA_ "FlexKomComment" SG_ 980 OBC_ChrgTm ".";
BA_ "GenSigSNA" SG_ 980 OBC_ChrgTmL "FFFFh";
BA_ "GenSigCycleTime" SG_ 980 OBC_ChrgTmL 1000;
BA_ "FlexKomSigStartValue" SG_ 980 OBC_ChrgTmL "0000000000000000h";
BA_ "FlexKomSigStartPos" SG_ 980 OBC_ChrgTmL 7;
BA_ "FlexKomSigName" SG_ 980 OBC_ChrgTmL "OBCM_Timer_Data";
BA_ "FlexKomSigLaenge" SG_ 980 OBC_ChrgTmL 64;
BA_ "FlexKomSID" SG_ 980 OBC_ChrgTmL 2130708670;
BA_ "FlexKomIsMotorola" SG_ 980 OBC_ChrgTmL 1;
BA_ "FlexKomComment" SG_ 980 OBC_ChrgTmL ".";
BA_ "GenSigSNA" SG_ 980 OBC_IdleTm "FFFFh";
BA_ "GenSigCycleTime" SG_ 980 OBC_IdleTm 1000;
BA_ "FlexKomSigStartValue" SG_ 980 OBC_IdleTm "0000000000000000h";
BA_ "FlexKomSigStartPos" SG_ 980 OBC_IdleTm 7;
BA_ "FlexKomSigName" SG_ 980 OBC_IdleTm "OBCM_Timer_Data";
BA_ "FlexKomSigLaenge" SG_ 980 OBC_IdleTm 64;
BA_ "FlexKomSID" SG_ 980 OBC_IdleTm 2130708670;
BA_ "FlexKomIsMotorola" SG_ 980 OBC_IdleTm 1;
BA_ "FlexKomComment" SG_ 980 OBC_IdleTm ".";
BA_ "GenSigSNA" SG_ 980 OBC_IdleTmL "FFFFh";
BA_ "GenSigCycleTime" SG_ 980 OBC_IdleTmL 1000;
BA_ "FlexKomSigStartValue" SG_ 980 OBC_IdleTmL "0000000000000000h";
BA_ "FlexKomSigStartPos" SG_ 980 OBC_IdleTmL 7;
BA_ "FlexKomSigName" SG_ 980 OBC_IdleTmL "OBCM_Timer_Data";
BA_ "FlexKomSigLaenge" SG_ 980 OBC_IdleTmL 64;
BA_ "FlexKomSID" SG_ 980 OBC_IdleTmL 2130708670;
BA_ "FlexKomIsMotorola" SG_ 980 OBC_IdleTmL 1;
BA_ "FlexKomComment" SG_ 980 OBC_IdleTmL ".";
BA_ "RID" SG_ 466 IMPACT_X "2130";
BA_ "GenSigSNA" SG_ 466 IMPACT_X "0h";
BA_ "GenSigSendType" SG_ 466 IMPACT_X 2;
BA_ "GenSigCycleTimeActive" SG_ 466 IMPACT_X 20;
BA_ "FlexKomSigStartValue" SG_ 466 IMPACT_X "0000h";
BA_ "FlexKomSigStartPos" SG_ 466 IMPACT_X 7;
BA_ "FlexKomSigName" SG_ 466 IMPACT_X "IMPACT";
BA_ "FlexKomSigLaenge" SG_ 466 IMPACT_X 16;
BA_ "FlexKomSID" SG_ 466 IMPACT_X 2130706757;
BA_ "FlexKomIsMotorola" SG_ 466 IMPACT_X 1;
BA_ "FlexKomComment" SG_ 466 IMPACT_X "Impact events";
BA_ "RID" SG_ 466 Impact_Tgl "2149";
BA_ "GenSigSNA" SG_ 466 Impact_Tgl "0h";
BA_ "GenSigSendType" SG_ 466 Impact_Tgl 2;
BA_ "GenSigCycleTimeActive" SG_ 466 Impact_Tgl 20;
BA_ "FlexKomSigStartValue" SG_ 466 Impact_Tgl "0000h";
BA_ "FlexKomSigStartPos" SG_ 466 Impact_Tgl 7;
BA_ "FlexKomSigName" SG_ 466 Impact_Tgl "IMPACT";
BA_ "FlexKomSigLaenge" SG_ 466 Impact_Tgl 16;
BA_ "FlexKomSID" SG_ 466 Impact_Tgl 2130706757;
BA_ "FlexKomIsMotorola" SG_ 466 Impact_Tgl 1;
BA_ "FlexKomComment" SG_ 466 Impact_Tgl "Impact events";
BA_ "GenSigSNA" SG_ 467 IMPACT_X_ePT "0h";
BA_ "GenSigSendType" SG_ 467 IMPACT_X_ePT 2;
BA_ "GenSigCycleTimeActive" SG_ 467 IMPACT_X_ePT 20;
BA_ "FlexKomSigStartValue" SG_ 467 IMPACT_X_ePT "0000h";
BA_ "FlexKomSigStartPos" SG_ 467 IMPACT_X_ePT 7;
BA_ "FlexKomSigName" SG_ 467 IMPACT_X_ePT "IMPACT_ePT";
BA_ "FlexKomSigLaenge" SG_ 467 IMPACT_X_ePT 16;
BA_ "FlexKomSID" SG_ 467 IMPACT_X_ePT 2130708750;
BA_ "FlexKomIsMotorola" SG_ 467 IMPACT_X_ePT 1;
BA_ "FlexKomComment" SG_ 467 IMPACT_X_ePT "Impact events on ePT bus.";
BA_ "GenSigSNA" SG_ 467 Impact_Tgl_ePT "0h";
BA_ "GenSigSendType" SG_ 467 Impact_Tgl_ePT 2;
BA_ "GenSigCycleTimeActive" SG_ 467 Impact_Tgl_ePT 20;
BA_ "FlexKomSigStartValue" SG_ 467 Impact_Tgl_ePT "0000h";
BA_ "FlexKomSigStartPos" SG_ 467 Impact_Tgl_ePT 7;
BA_ "FlexKomSigName" SG_ 467 Impact_Tgl_ePT "IMPACT_ePT";
BA_ "FlexKomSigLaenge" SG_ 467 Impact_Tgl_ePT 16;
BA_ "FlexKomSID" SG_ 467 Impact_Tgl_ePT 2130708750;
BA_ "FlexKomIsMotorola" SG_ 467 Impact_Tgl_ePT 1;
BA_ "FlexKomComment" SG_ 467 Impact_Tgl_ePT "Impact events on ePT bus.";
BA_ "RID" SG_ 469 ORC_Health "2199";
BA_ "GenSigSNA" SG_ 469 ORC_Health "0h";
BA_ "GenSigSendType" SG_ 469 ORC_Health 5;
BA_ "GenSigCycleTime" SG_ 469 ORC_Health 250;
BA_ "FlexKomSigStartValue" SG_ 469 ORC_Health "0000000000000000h";
BA_ "FlexKomSigStartPos" SG_ 469 ORC_Health 7;
BA_ "FlexKomSigName" SG_ 469 ORC_Health "ORC_A4_Pkt";
BA_ "FlexKomSigLaenge" SG_ 469 ORC_Health 64;
BA_ "FlexKomSID" SG_ 469 ORC_Health 2130708874;
BA_ "FlexKomIsMotorola" SG_ 469 ORC_Health 1;
BA_ "FlexKomComment" SG_ 469 ORC_Health "ORC A4 packet";
BA_ "GenSigSNA" SG_ 470 ORC_Health_ePT "0h";
BA_ "GenSigSendType" SG_ 470 ORC_Health_ePT 5;
BA_ "GenSigCycleTime" SG_ 470 ORC_Health_ePT 250;
BA_ "FlexKomSigStartValue" SG_ 470 ORC_Health_ePT "0000000000000000h";
BA_ "FlexKomSigStartPos" SG_ 470 ORC_Health_ePT 7;
BA_ "FlexKomSigName" SG_ 470 ORC_Health_ePT "ORC_A4a_Pkt";
BA_ "FlexKomSigLaenge" SG_ 470 ORC_Health_ePT 64;
BA_ "FlexKomSID" SG_ 470 ORC_Health_ePT 2130708875;
BA_ "FlexKomIsMotorola" SG_ 470 ORC_Health_ePT 1;
BA_ "FlexKomComment" SG_ 470 ORC_Health_ePT "ORC A4a packet";
BA_ "GenSigSNA" SG_ 787 BFC_Actualstate "3h";
BA_ "GenSigCycleTime" SG_ 787 BFC_Actualstate 100;
BA_ "FlexKomSigStartValue" SG_ 787 BFC_Actualstate "0000000000FFh";
BA_ "FlexKomSigStartPos" SG_ 787 BFC_Actualstate 7;
BA_ "FlexKomSigName" SG_ 787 BFC_Actualstate "RHSC2_Cooling";
BA_ "FlexKomSigLaenge" SG_ 787 BFC_Actualstate 48;
BA_ "FlexKomSID" SG_ 787 BFC_Actualstate 9817;
BA_ "FlexKomIsMotorola" SG_ 787 BFC_Actualstate 1;
BA_ "FlexKomComment" SG_ 787 BFC_Actualstate ".";
BA_ "GenSigSNA" SG_ 787 MC_RHSC2_Cooling "0h";
BA_ "GenSigCycleTime" SG_ 787 MC_RHSC2_Cooling 100;
BA_ "FlexKomSigStartValue" SG_ 787 MC_RHSC2_Cooling "0000000000FFh";
BA_ "FlexKomSigStartPos" SG_ 787 MC_RHSC2_Cooling 7;
BA_ "FlexKomSigName" SG_ 787 MC_RHSC2_Cooling "RHSC2_Cooling";
BA_ "FlexKomSigLaenge" SG_ 787 MC_RHSC2_Cooling 48;
BA_ "FlexKomSID" SG_ 787 MC_RHSC2_Cooling 9817;
BA_ "FlexKomIsMotorola" SG_ 787 MC_RHSC2_Cooling 1;
BA_ "FlexKomComment" SG_ 787 MC_RHSC2_Cooling ".";
BA_ "GenSigSNA" SG_ 787 SDS_ActualCoolantTemp "FFh";
BA_ "GenSigCycleTime" SG_ 787 SDS_ActualCoolantTemp 100;
BA_ "FlexKomSigStartValue" SG_ 787 SDS_ActualCoolantTemp "0000000000FFh";
BA_ "FlexKomSigStartPos" SG_ 787 SDS_ActualCoolantTemp 7;
BA_ "FlexKomSigName" SG_ 787 SDS_ActualCoolantTemp "RHSC2_Cooling";
BA_ "FlexKomSigLaenge" SG_ 787 SDS_ActualCoolantTemp 48;
BA_ "FlexKomSID" SG_ 787 SDS_ActualCoolantTemp 9817;
BA_ "FlexKomIsMotorola" SG_ 787 SDS_ActualCoolantTemp 1;
BA_ "FlexKomComment" SG_ 787 SDS_ActualCoolantTemp ".";
BA_ "GenSigSNA" SG_ 787 SDS_AverageHVPwr "FFh";
BA_ "GenSigCycleTime" SG_ 787 SDS_AverageHVPwr 100;
BA_ "FlexKomSigStartValue" SG_ 787 SDS_AverageHVPwr "0000000000FFh";
BA_ "FlexKomSigStartPos" SG_ 787 SDS_AverageHVPwr 7;
BA_ "FlexKomSigName" SG_ 787 SDS_AverageHVPwr "RHSC2_Cooling";
BA_ "FlexKomSigLaenge" SG_ 787 SDS_AverageHVPwr 48;
BA_ "FlexKomSID" SG_ 787 SDS_AverageHVPwr 9817;
BA_ "FlexKomIsMotorola" SG_ 787 SDS_AverageHVPwr 1;
BA_ "FlexKomComment" SG_ 787 SDS_AverageHVPwr ".";
BA_ "GenSigSNA" SG_ 787 SDS_CoolantTempTarget "3Fh";
BA_ "GenSigCycleTime" SG_ 787 SDS_CoolantTempTarget 100;
BA_ "FlexKomSigStartValue" SG_ 787 SDS_CoolantTempTarget "0000000000FFh";
BA_ "FlexKomSigStartPos" SG_ 787 SDS_CoolantTempTarget 7;
BA_ "FlexKomSigName" SG_ 787 SDS_CoolantTempTarget "RHSC2_Cooling";
BA_ "FlexKomSigLaenge" SG_ 787 SDS_CoolantTempTarget 48;
BA_ "FlexKomSID" SG_ 787 SDS_CoolantTempTarget 9817;
BA_ "FlexKomIsMotorola" SG_ 787 SDS_CoolantTempTarget 1;
BA_ "FlexKomComment" SG_ 787 SDS_CoolantTempTarget ".";
BA_ "GenSigSNA" SG_ 787 SDS_MaxCoolingReq "3h";
BA_ "GenSigCycleTime" SG_ 787 SDS_MaxCoolingReq 100;
BA_ "FlexKomSigStartValue" SG_ 787 SDS_MaxCoolingReq "0000000000FFh";
BA_ "FlexKomSigStartPos" SG_ 787 SDS_MaxCoolingReq 7;
BA_ "FlexKomSigName" SG_ 787 SDS_MaxCoolingReq "RHSC2_Cooling";
BA_ "FlexKomSigLaenge" SG_ 787 SDS_MaxCoolingReq 48;
BA_ "FlexKomSID" SG_ 787 SDS_MaxCoolingReq 9817;
BA_ "FlexKomIsMotorola" SG_ 787 SDS_MaxCoolingReq 1;
BA_ "FlexKomComment" SG_ 787 SDS_MaxCoolingReq ".";
BA_ "GenSigSNA" SG_ 272 CRC_110h "0h";
BA_ "GenSigCycleTime" SG_ 272 CRC_110h 10;
BA_ "FlexKomSigStartValue" SG_ 272 CRC_110h "0000000000000000h";
BA_ "FlexKomSigStartPos" SG_ 272 CRC_110h 7;
BA_ "FlexKomSigName" SG_ 272 CRC_110h "ReGenBrkRq";
BA_ "FlexKomSigLaenge" SG_ 272 CRC_110h 64;
BA_ "FlexKomSID" SG_ 272 CRC_110h 2130708676;
BA_ "FlexKomIsMotorola" SG_ 272 CRC_110h 1;
BA_ "FlexKomComment" SG_ 272 CRC_110h ".";
BA_ "GenSigSNA" SG_ 272 CommndTotBrkFricTorq "3FFFh";
BA_ "GenSigCycleTime" SG_ 272 CommndTotBrkFricTorq 10;
BA_ "FlexKomSigStartValue" SG_ 272 CommndTotBrkFricTorq "0000000000000000h";
BA_ "FlexKomSigStartPos" SG_ 272 CommndTotBrkFricTorq 7;
BA_ "FlexKomSigName" SG_ 272 CommndTotBrkFricTorq "ReGenBrkRq";
BA_ "FlexKomSigLaenge" SG_ 272 CommndTotBrkFricTorq 64;
BA_ "FlexKomSID" SG_ 272 CommndTotBrkFricTorq 2130708676;
BA_ "FlexKomIsMotorola" SG_ 272 CommndTotBrkFricTorq 1;
BA_ "FlexKomComment" SG_ 272 CommndTotBrkFricTorq ".";
BA_ "GenSigSNA" SG_ 272 DrvIntndTotBrkTorq "3FFFh";
BA_ "GenSigCycleTime" SG_ 272 DrvIntndTotBrkTorq 10;
BA_ "FlexKomSigStartValue" SG_ 272 DrvIntndTotBrkTorq "0000000000000000h";
BA_ "FlexKomSigStartPos" SG_ 272 DrvIntndTotBrkTorq 7;
BA_ "FlexKomSigName" SG_ 272 DrvIntndTotBrkTorq "ReGenBrkRq";
BA_ "FlexKomSigLaenge" SG_ 272 DrvIntndTotBrkTorq 64;
BA_ "FlexKomSID" SG_ 272 DrvIntndTotBrkTorq 2130708676;
BA_ "FlexKomIsMotorola" SG_ 272 DrvIntndTotBrkTorq 1;
BA_ "FlexKomComment" SG_ 272 DrvIntndTotBrkTorq ".";
BA_ "GenSigSNA" SG_ 272 MC_110h "0h";
BA_ "GenSigCycleTime" SG_ 272 MC_110h 10;
BA_ "FlexKomSigStartValue" SG_ 272 MC_110h "0000000000000000h";
BA_ "FlexKomSigStartPos" SG_ 272 MC_110h 7;
BA_ "FlexKomSigName" SG_ 272 MC_110h "ReGenBrkRq";
BA_ "FlexKomSigLaenge" SG_ 272 MC_110h 64;
BA_ "FlexKomSID" SG_ 272 MC_110h 2130708676;
BA_ "FlexKomIsMotorola" SG_ 272 MC_110h 1;
BA_ "FlexKomComment" SG_ 272 MC_110h ".";
BA_ "GenSigSNA" SG_ 272 RegenBrkAxTorqReqst "FFFh";
BA_ "GenSigCycleTime" SG_ 272 RegenBrkAxTorqReqst 10;
BA_ "FlexKomSigStartValue" SG_ 272 RegenBrkAxTorqReqst "0000000000000000h";
BA_ "FlexKomSigStartPos" SG_ 272 RegenBrkAxTorqReqst 7;
BA_ "FlexKomSigName" SG_ 272 RegenBrkAxTorqReqst "ReGenBrkRq";
BA_ "FlexKomSigLaenge" SG_ 272 RegenBrkAxTorqReqst 64;
BA_ "FlexKomSID" SG_ 272 RegenBrkAxTorqReqst 2130708676;
BA_ "FlexKomIsMotorola" SG_ 272 RegenBrkAxTorqReqst 1;
BA_ "FlexKomComment" SG_ 272 RegenBrkAxTorqReqst ".";
BA_ "GenSigSNA" SG_ 274 CRC_112h "0h";
BA_ "GenSigCycleTime" SG_ 274 CRC_112h 10;
BA_ "FlexKomSigStartValue" SG_ 274 CRC_112h "0000000000000000h";
BA_ "FlexKomSigStartPos" SG_ 274 CRC_112h 7;
BA_ "FlexKomSigName" SG_ 274 CRC_112h "ReGenBrkStat";
BA_ "FlexKomSigLaenge" SG_ 274 CRC_112h 64;
BA_ "FlexKomSID" SG_ 274 CRC_112h 2130708677;
BA_ "FlexKomIsMotorola" SG_ 274 CRC_112h 1;
BA_ "FlexKomComment" SG_ 274 CRC_112h ".";
BA_ "GenSigSNA" SG_ 274 EstRegenBrkAxTorq "FFFh";
BA_ "GenSigCycleTime" SG_ 274 EstRegenBrkAxTorq 10;
BA_ "FlexKomSigStartValue" SG_ 274 EstRegenBrkAxTorq "0000000000000000h";
BA_ "FlexKomSigStartPos" SG_ 274 EstRegenBrkAxTorq 7;
BA_ "FlexKomSigName" SG_ 274 EstRegenBrkAxTorq "ReGenBrkStat";
BA_ "FlexKomSigLaenge" SG_ 274 EstRegenBrkAxTorq 64;
BA_ "FlexKomSID" SG_ 274 EstRegenBrkAxTorq 2130708677;
BA_ "FlexKomIsMotorola" SG_ 274 EstRegenBrkAxTorq 1;
BA_ "FlexKomComment" SG_ 274 EstRegenBrkAxTorq ".";
BA_ "GenSigSNA" SG_ 274 MC_112h "0h";
BA_ "GenSigCycleTime" SG_ 274 MC_112h 10;
BA_ "FlexKomSigStartValue" SG_ 274 MC_112h "0000000000000000h";
BA_ "FlexKomSigStartPos" SG_ 274 MC_112h 7;
BA_ "FlexKomSigName" SG_ 274 MC_112h "ReGenBrkStat";
BA_ "FlexKomSigLaenge" SG_ 274 MC_112h 64;
BA_ "FlexKomSID" SG_ 274 MC_112h 2130708677;
BA_ "FlexKomIsMotorola" SG_ 274 MC_112h 1;
BA_ "FlexKomComment" SG_ 274 MC_112h ".";
BA_ "GenSigSNA" SG_ 274 RegenBrkAxTorqCap "FFFh";
BA_ "GenSigCycleTime" SG_ 274 RegenBrkAxTorqCap 10;
BA_ "FlexKomSigStartValue" SG_ 274 RegenBrkAxTorqCap "0000000000000000h";
BA_ "FlexKomSigStartPos" SG_ 274 RegenBrkAxTorqCap 7;
BA_ "FlexKomSigName" SG_ 274 RegenBrkAxTorqCap "ReGenBrkStat";
BA_ "FlexKomSigLaenge" SG_ 274 RegenBrkAxTorqCap 64;
BA_ "FlexKomSID" SG_ 274 RegenBrkAxTorqCap 2130708677;
BA_ "FlexKomIsMotorola" SG_ 274 RegenBrkAxTorqCap 1;
BA_ "FlexKomComment" SG_ 274 RegenBrkAxTorqCap ".";
BA_ "RID" SG_ 528 APCM_Stat_DPT "9796";
BA_ "GenSigSNA" SG_ 528 APCM_Stat_DPT "3h";
BA_ "GenSigCycleTime" SG_ 528 APCM_Stat_DPT 20;
BA_ "FlexKomSigStartValue" SG_ 528 APCM_Stat_DPT "00000000FFh";
BA_ "FlexKomSigStartPos" SG_ 528 APCM_Stat_DPT 7;
BA_ "FlexKomSigName" SG_ 528 APCM_Stat_DPT "SBW_ROT1_PKT_DPT";
BA_ "FlexKomSigLaenge" SG_ 528 APCM_Stat_DPT 40;
BA_ "FlexKomSID" SG_ 528 APCM_Stat_DPT 2130708106;
BA_ "FlexKomIsMotorola" SG_ 528 APCM_Stat_DPT 1;
BA_ "FlexKomComment" SG_ 528 APCM_Stat_DPT "Shift by wire - rotary 1 packet";
BA_ "GenSigStartValue" SG_ 528 CRC_SBW_ROT1_DPT 255;
BA_ "GenSigSNA" SG_ 528 CRC_SBW_ROT1_DPT "FFh";
BA_ "GenSigCycleTime" SG_ 528 CRC_SBW_ROT1_DPT 20;
BA_ "FlexKomSigStartValue" SG_ 528 CRC_SBW_ROT1_DPT "00000000FFh";
BA_ "FlexKomSigStartPos" SG_ 528 CRC_SBW_ROT1_DPT 7;
BA_ "FlexKomSigName" SG_ 528 CRC_SBW_ROT1_DPT "SBW_ROT1_PKT_DPT";
BA_ "FlexKomSigLaenge" SG_ 528 CRC_SBW_ROT1_DPT 40;
BA_ "FlexKomSID" SG_ 528 CRC_SBW_ROT1_DPT 2130708106;
BA_ "FlexKomIsMotorola" SG_ 528 CRC_SBW_ROT1_DPT 1;
BA_ "FlexKomComment" SG_ 528 CRC_SBW_ROT1_DPT "Shift by wire - rotary 1 packet";
BA_ "RID" SG_ 528 DrvRqShftROT_DPT "9798";
BA_ "GenSigSNA" SG_ 528 DrvRqShftROT_DPT "7h";
BA_ "GenSigCycleTime" SG_ 528 DrvRqShftROT_DPT 20;
BA_ "FlexKomSigStartValue" SG_ 528 DrvRqShftROT_DPT "00000000FFh";
BA_ "FlexKomSigStartPos" SG_ 528 DrvRqShftROT_DPT 7;
BA_ "FlexKomSigName" SG_ 528 DrvRqShftROT_DPT "SBW_ROT1_PKT_DPT";
BA_ "FlexKomSigLaenge" SG_ 528 DrvRqShftROT_DPT 40;
BA_ "FlexKomSID" SG_ 528 DrvRqShftROT_DPT 2130708106;
BA_ "FlexKomIsMotorola" SG_ 528 DrvRqShftROT_DPT 1;
BA_ "FlexKomComment" SG_ 528 DrvRqShftROT_DPT "Shift by wire - rotary 1 packet";
BA_ "RID" SG_ 528 MC_SBW_ROT1_DPT "9799";
BA_ "GenSigSNA" SG_ 528 MC_SBW_ROT1_DPT "0h";
BA_ "GenSigCycleTime" SG_ 528 MC_SBW_ROT1_DPT 20;
BA_ "FlexKomSigStartValue" SG_ 528 MC_SBW_ROT1_DPT "00000000FFh";
BA_ "FlexKomSigStartPos" SG_ 528 MC_SBW_ROT1_DPT 7;
BA_ "FlexKomSigName" SG_ 528 MC_SBW_ROT1_DPT "SBW_ROT1_PKT_DPT";
BA_ "FlexKomSigLaenge" SG_ 528 MC_SBW_ROT1_DPT 40;
BA_ "FlexKomSID" SG_ 528 MC_SBW_ROT1_DPT 2130708106;
BA_ "FlexKomIsMotorola" SG_ 528 MC_SBW_ROT1_DPT 1;
BA_ "FlexKomComment" SG_ 528 MC_SBW_ROT1_DPT "Shift by wire - rotary 1 packet";
BA_ "RID" SG_ 528 RackFlt_DPT "9800";
BA_ "GenSigSNA" SG_ 528 RackFlt_DPT "0h";
BA_ "GenSigCycleTime" SG_ 528 RackFlt_DPT 20;
BA_ "FlexKomSigStartValue" SG_ 528 RackFlt_DPT "00000000FFh";
BA_ "FlexKomSigStartPos" SG_ 528 RackFlt_DPT 7;
BA_ "FlexKomSigName" SG_ 528 RackFlt_DPT "SBW_ROT1_PKT_DPT";
BA_ "FlexKomSigLaenge" SG_ 528 RackFlt_DPT 40;
BA_ "FlexKomSID" SG_ 528 RackFlt_DPT 2130708106;
BA_ "FlexKomIsMotorola" SG_ 528 RackFlt_DPT 1;
BA_ "FlexKomComment" SG_ 528 RackFlt_DPT "Shift by wire - rotary 1 packet";
BA_ "RID" SG_ 528 ShftDispFltROT_DPT "9801";
BA_ "GenSigSNA" SG_ 528 ShftDispFltROT_DPT "0h";
BA_ "GenSigCycleTime" SG_ 528 ShftDispFltROT_DPT 20;
BA_ "FlexKomSigStartValue" SG_ 528 ShftDispFltROT_DPT "00000000FFh";
BA_ "FlexKomSigStartPos" SG_ 528 ShftDispFltROT_DPT 7;
BA_ "FlexKomSigName" SG_ 528 ShftDispFltROT_DPT "SBW_ROT1_PKT_DPT";
BA_ "FlexKomSigLaenge" SG_ 528 ShftDispFltROT_DPT 40;
BA_ "FlexKomSID" SG_ 528 ShftDispFltROT_DPT 2130708106;
BA_ "FlexKomIsMotorola" SG_ 528 ShftDispFltROT_DPT 1;
BA_ "FlexKomComment" SG_ 528 ShftDispFltROT_DPT "Shift by wire - rotary 1 packet";
BA_ "RID" SG_ 528 ShftLkFltROT_DPT "9802";
BA_ "GenSigSNA" SG_ 528 ShftLkFltROT_DPT "0h";
BA_ "GenSigCycleTime" SG_ 528 ShftLkFltROT_DPT 20;
BA_ "FlexKomSigStartValue" SG_ 528 ShftLkFltROT_DPT "00000000FFh";
BA_ "FlexKomSigStartPos" SG_ 528 ShftLkFltROT_DPT 7;
BA_ "FlexKomSigName" SG_ 528 ShftLkFltROT_DPT "SBW_ROT1_PKT_DPT";
BA_ "FlexKomSigLaenge" SG_ 528 ShftLkFltROT_DPT 40;
BA_ "FlexKomSID" SG_ 528 ShftLkFltROT_DPT 2130708106;
BA_ "FlexKomIsMotorola" SG_ 528 ShftLkFltROT_DPT 1;
BA_ "FlexKomComment" SG_ 528 ShftLkFltROT_DPT "Shift by wire - rotary 1 packet";
BA_ "RID" SG_ 528 ShftSensFltROT_DPT "9803";
BA_ "GenSigSNA" SG_ 528 ShftSensFltROT_DPT "0h";
BA_ "GenSigCycleTime" SG_ 528 ShftSensFltROT_DPT 20;
BA_ "FlexKomSigStartValue" SG_ 528 ShftSensFltROT_DPT "00000000FFh";
BA_ "FlexKomSigStartPos" SG_ 528 ShftSensFltROT_DPT 7;
BA_ "FlexKomSigName" SG_ 528 ShftSensFltROT_DPT "SBW_ROT1_PKT_DPT";
BA_ "FlexKomSigLaenge" SG_ 528 ShftSensFltROT_DPT 40;
BA_ "FlexKomSID" SG_ 528 ShftSensFltROT_DPT 2130708106;
BA_ "FlexKomIsMotorola" SG_ 528 ShftSensFltROT_DPT 1;
BA_ "FlexKomComment" SG_ 528 ShftSensFltROT_DPT "Shift by wire - rotary 1 packet";
BA_ "GenSigStartValue" SG_ 298 CRC_SDS_Motion_Ref 255;
BA_ "GenSigSNA" SG_ 298 CRC_SDS_Motion_Ref "FFh";
BA_ "GenSigCycleTime" SG_ 298 CRC_SDS_Motion_Ref 10;
BA_ "FlexKomSigStartValue" SG_ 298 CRC_SDS_Motion_Ref "0000FFFF00FFh";
BA_ "FlexKomSigStartPos" SG_ 298 CRC_SDS_Motion_Ref 7;
BA_ "FlexKomSigName" SG_ 298 CRC_SDS_Motion_Ref "SDS_Motion_Ref_Pkt";
BA_ "FlexKomSigLaenge" SG_ 298 CRC_SDS_Motion_Ref 48;
BA_ "FlexKomSID" SG_ 298 CRC_SDS_Motion_Ref 9822;
BA_ "FlexKomIsMotorola" SG_ 298 CRC_SDS_Motion_Ref 1;
BA_ "FlexKomComment" SG_ 298 CRC_SDS_Motion_Ref "SDS Motion Reference Packet";
BA_ "GenSigSNA" SG_ 298 LongAcceleration "FFFh";
BA_ "GenSigCycleTime" SG_ 298 LongAcceleration 10;
BA_ "FlexKomSigStartValue" SG_ 298 LongAcceleration "0000FFFF00FFh";
BA_ "FlexKomSigStartPos" SG_ 298 LongAcceleration 7;
BA_ "FlexKomSigName" SG_ 298 LongAcceleration "SDS_Motion_Ref_Pkt";
BA_ "FlexKomSigLaenge" SG_ 298 LongAcceleration 48;
BA_ "FlexKomSID" SG_ 298 LongAcceleration 9822;
BA_ "FlexKomIsMotorola" SG_ 298 LongAcceleration 1;
BA_ "FlexKomComment" SG_ 298 LongAcceleration "SDS Motion Reference Packet";
BA_ "GenSigSNA" SG_ 298 MC_SDS_Motion_Ref "0h";
BA_ "GenSigCycleTime" SG_ 298 MC_SDS_Motion_Ref 10;
BA_ "FlexKomSigStartValue" SG_ 298 MC_SDS_Motion_Ref "0000FFFF00FFh";
BA_ "FlexKomSigStartPos" SG_ 298 MC_SDS_Motion_Ref 7;
BA_ "FlexKomSigName" SG_ 298 MC_SDS_Motion_Ref "SDS_Motion_Ref_Pkt";
BA_ "FlexKomSigLaenge" SG_ 298 MC_SDS_Motion_Ref 48;
BA_ "FlexKomSID" SG_ 298 MC_SDS_Motion_Ref 9822;
BA_ "FlexKomIsMotorola" SG_ 298 MC_SDS_Motion_Ref 1;
BA_ "FlexKomComment" SG_ 298 MC_SDS_Motion_Ref "SDS Motion Reference Packet";
BA_ "GenSigStartValue" SG_ 298 VEH_SPEED 65545;
BA_ "GenSigSNA" SG_ 298 VEH_SPEED "FFFFh";
BA_ "GenSigCycleTime" SG_ 298 VEH_SPEED 10;
BA_ "FlexKomSigStartValue" SG_ 298 VEH_SPEED "0000FFFF00FFh";
BA_ "FlexKomSigStartPos" SG_ 298 VEH_SPEED 7;
BA_ "FlexKomSigName" SG_ 298 VEH_SPEED "SDS_Motion_Ref_Pkt";
BA_ "FlexKomSigLaenge" SG_ 298 VEH_SPEED 48;
BA_ "FlexKomSID" SG_ 298 VEH_SPEED 9822;
BA_ "FlexKomIsMotorola" SG_ 298 VEH_SPEED 1;
BA_ "FlexKomComment" SG_ 298 VEH_SPEED "SDS Motion Reference Packet";
BA_ "GenSigSNA" SG_ 1599 SD_RS_BPCM "0h";
BA_ "GenSigSendType" SG_ 1599 SD_RS_BPCM 9;
BA_ "GenSigCycleTime" SG_ 1599 SD_RS_BPCM 200;
BA_ "FlexKomSigStartValue" SG_ 1599 SD_RS_BPCM "0000000000000000h";
BA_ "FlexKomSigStartPos" SG_ 1599 SD_RS_BPCM 7;
BA_ "FlexKomSigName" SG_ 1599 SD_RS_BPCM "SD_RS_BPCM";
BA_ "FlexKomSigLaenge" SG_ 1599 SD_RS_BPCM 64;
BA_ "FlexKomSID" SG_ 1599 SD_RS_BPCM 2130708577;
BA_ "FlexKomIsMotorola" SG_ 1599 SD_RS_BPCM 1;
BA_ "FlexKomComment" SG_ 1599 SD_RS_BPCM "Response on Event - light";
BA_ "GenSigSNA" SG_ 691 EOL_EAC "0h";
BA_ "GenSigCycleTime" SG_ 691 EOL_EAC 500;
BA_ "FlexKomSigStartValue" SG_ 691 EOL_EAC "000000h";
BA_ "FlexKomSigStartPos" SG_ 691 EOL_EAC 7;
BA_ "FlexKomSigName" SG_ 691 EOL_EAC "STATUS_EPT_EAC";
BA_ "FlexKomSigLaenge" SG_ 691 EOL_EAC 24;
BA_ "FlexKomSID" SG_ 691 EOL_EAC 2130708681;
BA_ "FlexKomIsMotorola" SG_ 691 EOL_EAC 1;
BA_ "FlexKomComment" SG_ 691 EOL_EAC ".";
BA_ "GenSigSNA" SG_ 698 CaptEnvData_OBCM "1h";
BA_ "GenSigCycleTime" SG_ 698 CaptEnvData_OBCM 500;
BA_ "FlexKomSigStartValue" SG_ 698 CaptEnvData_OBCM "00000000000000h";
BA_ "FlexKomSigStartPos" SG_ 698 CaptEnvData_OBCM 7;
BA_ "FlexKomSigName" SG_ 698 CaptEnvData_OBCM "STATUS_EPT_OBCM";
BA_ "FlexKomSigLaenge" SG_ 698 CaptEnvData_OBCM 56;
BA_ "FlexKomSID" SG_ 698 CaptEnvData_OBCM 2130708693;
BA_ "FlexKomIsMotorola" SG_ 698 CaptEnvData_OBCM 1;
BA_ "FlexKomComment" SG_ 698 CaptEnvData_OBCM ".";
BA_ "GenSigSNA" SG_ 698 ChrgFail_On_OBCM "0h";
BA_ "GenSigCycleTime" SG_ 698 ChrgFail_On_OBCM 500;
BA_ "FlexKomSigStartValue" SG_ 698 ChrgFail_On_OBCM "00000000000000h";
BA_ "FlexKomSigStartPos" SG_ 698 ChrgFail_On_OBCM 7;
BA_ "FlexKomSigName" SG_ 698 ChrgFail_On_OBCM "STATUS_EPT_OBCM";
BA_ "FlexKomSigLaenge" SG_ 698 ChrgFail_On_OBCM 56;
BA_ "FlexKomSID" SG_ 698 ChrgFail_On_OBCM 2130708693;
BA_ "FlexKomIsMotorola" SG_ 698 ChrgFail_On_OBCM 1;
BA_ "FlexKomComment" SG_ 698 ChrgFail_On_OBCM ".";
BA_ "GenSigSNA" SG_ 698 CurrentFailSts_OBCM "0h";
BA_ "GenSigCycleTime" SG_ 698 CurrentFailSts_OBCM 500;
BA_ "FlexKomSigStartValue" SG_ 698 CurrentFailSts_OBCM "00000000000000h";
BA_ "FlexKomSigStartPos" SG_ 698 CurrentFailSts_OBCM 7;
BA_ "FlexKomSigName" SG_ 698 CurrentFailSts_OBCM "STATUS_EPT_OBCM";
BA_ "FlexKomSigLaenge" SG_ 698 CurrentFailSts_OBCM 56;
BA_ "FlexKomSID" SG_ 698 CurrentFailSts_OBCM 2130708693;
BA_ "FlexKomIsMotorola" SG_ 698 CurrentFailSts_OBCM 1;
BA_ "FlexKomComment" SG_ 698 CurrentFailSts_OBCM ".";
BA_ "GenSigSNA" SG_ 698 DTC_OBCM "FFFFh";
BA_ "GenSigCycleTime" SG_ 698 DTC_OBCM 500;
BA_ "FlexKomSigStartValue" SG_ 698 DTC_OBCM "00000000000000h";
BA_ "FlexKomSigStartPos" SG_ 698 DTC_OBCM 7;
BA_ "FlexKomSigName" SG_ 698 DTC_OBCM "STATUS_EPT_OBCM";
BA_ "FlexKomSigLaenge" SG_ 698 DTC_OBCM 56;
BA_ "FlexKomSID" SG_ 698 DTC_OBCM 2130708693;
BA_ "FlexKomIsMotorola" SG_ 698 DTC_OBCM 1;
BA_ "FlexKomComment" SG_ 698 DTC_OBCM ".";
BA_ "GenSigSNA" SG_ 698 D_ES_OBCM "3h";
BA_ "GenSigCycleTime" SG_ 698 D_ES_OBCM 500;
BA_ "FlexKomSigStartValue" SG_ 698 D_ES_OBCM "00000000000000h";
BA_ "FlexKomSigStartPos" SG_ 698 D_ES_OBCM 7;
BA_ "FlexKomSigName" SG_ 698 D_ES_OBCM "STATUS_EPT_OBCM";
BA_ "FlexKomSigLaenge" SG_ 698 D_ES_OBCM 56;
BA_ "FlexKomSID" SG_ 698 D_ES_OBCM 2130708693;
BA_ "FlexKomIsMotorola" SG_ 698 D_ES_OBCM 1;
BA_ "FlexKomComment" SG_ 698 D_ES_OBCM ".";
BA_ "GenSigSNA" SG_ 698 EOL_OBCM "0h";
BA_ "GenSigCycleTime" SG_ 698 EOL_OBCM 500;
BA_ "FlexKomSigStartValue" SG_ 698 EOL_OBCM "00000000000000h";
BA_ "FlexKomSigStartPos" SG_ 698 EOL_OBCM 7;
BA_ "FlexKomSigName" SG_ 698 EOL_OBCM "STATUS_EPT_OBCM";
BA_ "FlexKomSigLaenge" SG_ 698 EOL_OBCM 56;
BA_ "FlexKomSID" SG_ 698 EOL_OBCM 2130708693;
BA_ "FlexKomIsMotorola" SG_ 698 EOL_OBCM 1;
BA_ "FlexKomComment" SG_ 698 EOL_OBCM ".";
BA_ "GenSigSNA" SG_ 698 EVSer_Flash_OBCM "0h";
BA_ "GenSigCycleTime" SG_ 698 EVSer_Flash_OBCM 500;
BA_ "FlexKomSigStartValue" SG_ 698 EVSer_Flash_OBCM "00000000000000h";
BA_ "FlexKomSigStartPos" SG_ 698 EVSer_Flash_OBCM 7;
BA_ "FlexKomSigName" SG_ 698 EVSer_Flash_OBCM "STATUS_EPT_OBCM";
BA_ "FlexKomSigLaenge" SG_ 698 EVSer_Flash_OBCM 56;
BA_ "FlexKomSID" SG_ 698 EVSer_Flash_OBCM 2130708693;
BA_ "FlexKomIsMotorola" SG_ 698 EVSer_Flash_OBCM 1;
BA_ "FlexKomComment" SG_ 698 EVSer_Flash_OBCM ".";
BA_ "GenSigSNA" SG_ 698 EVSer_On_OBCM "0h";
BA_ "GenSigCycleTime" SG_ 698 EVSer_On_OBCM 500;
BA_ "FlexKomSigStartValue" SG_ 698 EVSer_On_OBCM "00000000000000h";
BA_ "FlexKomSigStartPos" SG_ 698 EVSer_On_OBCM 7;
BA_ "FlexKomSigName" SG_ 698 EVSer_On_OBCM "STATUS_EPT_OBCM";
BA_ "FlexKomSigLaenge" SG_ 698 EVSer_On_OBCM 56;
BA_ "FlexKomSID" SG_ 698 EVSer_On_OBCM 2130708693;
BA_ "FlexKomIsMotorola" SG_ 698 EVSer_On_OBCM 1;
BA_ "FlexKomComment" SG_ 698 EVSer_On_OBCM ".";
BA_ "GenSigSNA" SG_ 698 GenericFailSts_OBCM "0h";
BA_ "GenSigCycleTime" SG_ 698 GenericFailSts_OBCM 500;
BA_ "FlexKomSigStartValue" SG_ 698 GenericFailSts_OBCM "00000000000000h";
BA_ "FlexKomSigStartPos" SG_ 698 GenericFailSts_OBCM 7;
BA_ "FlexKomSigName" SG_ 698 GenericFailSts_OBCM "STATUS_EPT_OBCM";
BA_ "FlexKomSigLaenge" SG_ 698 GenericFailSts_OBCM 56;
BA_ "FlexKomSID" SG_ 698 GenericFailSts_OBCM 2130708693;
BA_ "FlexKomIsMotorola" SG_ 698 GenericFailSts_OBCM 1;
BA_ "FlexKomComment" SG_ 698 GenericFailSts_OBCM ".";
BA_ "GenSigSNA" SG_ 992 VIN_DATA "0h";
BA_ "GenSigCycleTime" SG_ 992 VIN_DATA 100;
BA_ "FlexKomSigStartValue" SG_ 992 VIN_DATA "0300000000000000h";
BA_ "FlexKomSigStartPos" SG_ 992 VIN_DATA 7;
BA_ "FlexKomSigName" SG_ 992 VIN_DATA "VIN_INFO";
BA_ "FlexKomSigLaenge" SG_ 992 VIN_DATA 64;
BA_ "FlexKomSID" SG_ 992 VIN_DATA 2130706862;
BA_ "FlexKomIsMotorola" SG_ 992 VIN_DATA 1;
BA_ "FlexKomComment" SG_ 992 VIN_DATA "Vin Information";
BA_ "GenSigStartValue" SG_ 992 VIN_MSG 3;
BA_ "GenSigSNA" SG_ 992 VIN_MSG "3h";
BA_ "GenSigCycleTime" SG_ 992 VIN_MSG 100;
BA_ "FlexKomSigStartValue" SG_ 992 VIN_MSG "0300000000000000h";
BA_ "FlexKomSigStartPos" SG_ 992 VIN_MSG 7;
BA_ "FlexKomSigName" SG_ 992 VIN_MSG "VIN_INFO";
BA_ "FlexKomSigLaenge" SG_ 992 VIN_MSG 64;
BA_ "FlexKomSID" SG_ 992 VIN_MSG 2130706862;
BA_ "FlexKomIsMotorola" SG_ 992 VIN_MSG 1;
BA_ "FlexKomComment" SG_ 992 VIN_MSG "Vin Information";
BA_ "RID" SG_ 1023 VC_BODY_STYLE "5021";
BA_ "GenSigStartValue" SG_ 1023 VC_BODY_STYLE 15;
BA_ "GenSigSNA" SG_ 1023 VC_BODY_STYLE "Fh";
BA_ "GenSigSendType" SG_ 1023 VC_BODY_STYLE 5;
BA_ "GenSigCycleTime" SG_ 1023 VC_BODY_STYLE 500;
BA_ "FlexKomSigStartValue" SG_ 1023 VC_BODY_STYLE "FFFF7FF0FF0FFF00h";
BA_ "FlexKomSigStartPos" SG_ 1023 VC_BODY_STYLE 7;
BA_ "FlexKomSigName" SG_ 1023 VC_BODY_STYLE "VehCfg1_Pkt";
BA_ "FlexKomSigLaenge" SG_ 1023 VC_BODY_STYLE 64;
BA_ "FlexKomSID" SG_ 1023 VC_BODY_STYLE 2130707318;
BA_ "FlexKomIsMotorola" SG_ 1023 VC_BODY_STYLE 1;
BA_ "FlexKomComment" SG_ 1023 VC_BODY_STYLE "Vehicle Configuration 1 Packet";
BA_ "RID" SG_ 1023 VC_COUNTRY "5025";
BA_ "GenSigStartValue" SG_ 1023 VC_COUNTRY 31;
BA_ "GenSigSNA" SG_ 1023 VC_COUNTRY "1Fh";
BA_ "GenSigSendType" SG_ 1023 VC_COUNTRY 5;
BA_ "GenSigCycleTime" SG_ 1023 VC_COUNTRY 500;
BA_ "FlexKomSigStartValue" SG_ 1023 VC_COUNTRY "FFFF7FF0FF0FFF00h";
BA_ "FlexKomSigStartPos" SG_ 1023 VC_COUNTRY 7;
BA_ "FlexKomSigName" SG_ 1023 VC_COUNTRY "VehCfg1_Pkt";
BA_ "FlexKomSigLaenge" SG_ 1023 VC_COUNTRY 64;
BA_ "FlexKomSID" SG_ 1023 VC_COUNTRY 2130707318;
BA_ "FlexKomIsMotorola" SG_ 1023 VC_COUNTRY 1;
BA_ "FlexKomComment" SG_ 1023 VC_COUNTRY "Vehicle Configuration 1 Packet";
BA_ "RID" SG_ 1023 VC_MODEL_YEAR "5024";
BA_ "GenSigStartValue" SG_ 1023 VC_MODEL_YEAR 63;
BA_ "GenSigSNA" SG_ 1023 VC_MODEL_YEAR "3Fh";
BA_ "GenSigSendType" SG_ 1023 VC_MODEL_YEAR 5;
BA_ "GenSigCycleTime" SG_ 1023 VC_MODEL_YEAR 500;
BA_ "FlexKomSigStartValue" SG_ 1023 VC_MODEL_YEAR "FFFF7FF0FF0FFF00h";
BA_ "FlexKomSigStartPos" SG_ 1023 VC_MODEL_YEAR 7;
BA_ "FlexKomSigName" SG_ 1023 VC_MODEL_YEAR "VehCfg1_Pkt";
BA_ "FlexKomSigLaenge" SG_ 1023 VC_MODEL_YEAR 64;
BA_ "FlexKomSID" SG_ 1023 VC_MODEL_YEAR 2130707318;
BA_ "FlexKomIsMotorola" SG_ 1023 VC_MODEL_YEAR 1;
BA_ "FlexKomComment" SG_ 1023 VC_MODEL_YEAR "Vehicle Configuration 1 Packet";
BA_ "RID" SG_ 1023 VC_VEH_LINE "5023";
BA_ "GenSigStartValue" SG_ 1023 VC_VEH_LINE 255;
BA_ "GenSigSNA" SG_ 1023 VC_VEH_LINE "FFh";
BA_ "GenSigSendType" SG_ 1023 VC_VEH_LINE 5;
BA_ "GenSigCycleTime" SG_ 1023 VC_VEH_LINE 500;
BA_ "FlexKomSigStartValue" SG_ 1023 VC_VEH_LINE "FFFF7FF0FF0FFF00h";
BA_ "FlexKomSigStartPos" SG_ 1023 VC_VEH_LINE 7;
BA_ "FlexKomSigName" SG_ 1023 VC_VEH_LINE "VehCfg1_Pkt";
BA_ "FlexKomSigLaenge" SG_ 1023 VC_VEH_LINE 64;
BA_ "FlexKomSID" SG_ 1023 VC_VEH_LINE 2130707318;
BA_ "FlexKomIsMotorola" SG_ 1023 VC_VEH_LINE 1;
BA_ "FlexKomComment" SG_ 1023 VC_VEH_LINE "Vehicle Configuration 1 Packet";
BA_ "RID" SG_ 1023 VC_VehCfg1_Stat "5022";
BA_ "GenSigStartValue" SG_ 1023 VC_VehCfg1_Stat 3;
BA_ "GenSigSNA" SG_ 1023 VC_VehCfg1_Stat "3h";
BA_ "GenSigSendType" SG_ 1023 VC_VehCfg1_Stat 5;
BA_ "GenSigCycleTime" SG_ 1023 VC_VehCfg1_Stat 500;
BA_ "FlexKomSigStartValue" SG_ 1023 VC_VehCfg1_Stat "FFFF7FF0FF0FFF00h";
BA_ "FlexKomSigStartPos" SG_ 1023 VC_VehCfg1_Stat 7;
BA_ "FlexKomSigName" SG_ 1023 VC_VehCfg1_Stat "VehCfg1_Pkt";
BA_ "FlexKomSigLaenge" SG_ 1023 VC_VehCfg1_Stat 64;
BA_ "FlexKomSID" SG_ 1023 VC_VehCfg1_Stat 2130707318;
BA_ "FlexKomIsMotorola" SG_ 1023 VC_VehCfg1_Stat 1;
BA_ "FlexKomComment" SG_ 1023 VC_VehCfg1_Stat "Vehicle Configuration 1 Packet";
VAL_ 768 APCM_Rq 0 "OFF" 1 "ON" 2 "PENDING" 3 "SNA" ;
VAL_ 768 PRNDL_Blink 0 "NONE" 1 "P" 2 "R" 3 "N" 4 "D" 5 "L" 6 "S" 7 "M_TIP" ;
VAL_ 768 PRNDL_DISP 32 "BLANK" 49 "ONE" 50 "TWO" 51 "THREE" 52 "FOUR" 53 "FIVE" 54 "SIX" 55 "SEVEN" 56 "EIGHT" 57 "NINE" 65 "A" 68 "D" 70 "F" 76 "L" 77 "M" 78 "N" 80 "P" 82 "R" 83 "S" 128 "DS" 130 "D2" 131 "D3" 132 "D4" 133 "D5" 135 "SNOW" 254 "NOT_N" 255 "SNA" ;
VAL_ 677 J1772_S2_Close 0 "OPN" 1 "CLS" ;
VAL_ 677 OBC_Ctrl_Mth 0 "CURRENT" 1 "VOLTAGE" 2 "POWER" 3 "SNA" ;
VAL_ 677 OBC_MdRq 0 "IDLE" 1 "HEATER" 2 "CHARGE" 3 "AC_PNL" 4 "AC_GRD_Sync" 5 "AC_GRD_Synth" 7 "SNA" ;
VAL_ 677 ProxStatus 0 "PROX_LO" 1 "Prox_Out" 2 "Prox_In" 3 "Prox_Un" 6 "VOOR" 7 "PROX_HI" ;
VAL_ 1007 AC_CurrMaxCal 511 "SNA" ;
VAL_ 1007 HV_CurrMaxCal 255 "SNA" ;
VAL_ 1007 HV_VoltMaxCal 511 "SNA" ;
VAL_ 1007 HV_VoltMinCal 511 "SNA" ;
VAL_ 472 BattPerWU_12VChg_Timer 1023 "SNA" ;
VAL_ 472 BattPerWU_ThermalCond_Timer 1023 "SNA" ;
VAL_ 472 HVBatBalReq 0 "No_Request" 1 "RequestNoBalance" 2 "RequestBalance" 3 "SNA" ;
VAL_ 472 HVBat_CoolantLvlLo 0 "FALSE" 1 "TRUE" 3 "SNA" ;
VAL_ 472 HVInvRatVlt 511 "SNA" ;
VAL_ 472 HVInvRatVltV 0 "Valid" 1 "Not_Valid" ;
VAL_ 472 MainHighVltCntctrCmd 0 "OPN" 1 "CLS" 2 "IMPCT_OPN" 3 "FAST_OPN" 7 "INV" ;
VAL_ 472 PwrtrnHV_IntrlkStat 0 "N_S" 1 "PASS" 2 "FAIL" 3 "INV" ;
VAL_ 169 HybCmndEngTorqImmed 4095 "SNA" ;
VAL_ 169 HybCmndEngTorqPrdtd 4095 "SNA" ;
VAL_ 169 HybCmndEngTorqRespTyp 0 "Inactive" 1 "PL" 2 "MR" 3 "SNA" ;
VAL_ 169 HybEstEngTorq 4095 "SNA" ;
VAL_ 180 EPT_LOC_DiagEnable 0 "Default" 1 "ENB_LOC" 2 "ENB_LOC_LIMIT" ;
VAL_ 180 HCPShutDwnCmd 0 "default" 1 "Initiate_Powerdown" 2 "Shutdown" 3 "Cancel_Powerdown" 7 "SNA" ;
VAL_ 180 HybTransSt 0 "INIT" 1 "Neutral_Stable_State" 2 "EVT_Mode1_Stable_State" 3 "EVT_Mode2_Stable_State" 4 "Gear1_Stable_State" 5 "Gear2_Stable_State" 6 "Gear3_Stable_State" 7 "Gear4_Stable_State" 8 "G1_G2_SP" 9 "G1_G2_TP" 10 "G2_G1_SP" 11 "G2_G1_TP" 12 "G2_G3_SP" 13 "G2_G3_TP" 14 "G3_G2_SP" 15 "G3_G2_TP" 16 "G3_G4_SP" 17 "G3_G4_TP" 18 "G4_G3_SP" 19 "G4_G3_TP" 20 "EVT_M1_Gear1_SP" 21 "EVT_M1_Gear2_SP" 22 "EVT_M2_Gear2_SP" 23 "EVT_M2_Gear3_SP" 24 "EVT_M2_Gear4_SP" 25 "Neutral_EVT_M1_Shift" 26 "Neutral_EVT_M2_Shift" 27 "Shift_Neutral" 28 "EVT_M1_EVT_M2_QS" 29 "EVT_M2_EVT_M1_QS" 30 "EVT_M1_SP" 31 "EVT_M2_SP" 32 "G1_Abort_G1G2_TP" 33 "G2_Abort_G2G3_TP" 34 "G3_Abort_G3G4_TP" 35 "G2_Abort_G2G1_TP" 36 "G3_Abort_G3G2_TP" 37 "G4_Abort_G4G3_TP" 63 "INV" ;
VAL_ 180 ShftRangeState 0 "Between_Range" 1 "Park" 2 "Reverse" 3 "Neutral" 4 "DRIVE" 5 "ONE" 6 "TWO" 7 "THREE" 8 "FOUR" 9 "FIVE" 10 "SIX" 15 "SNA" ;
VAL_ 471 HEV_ESS_Mode 0 "EngOff" 1 "IS" 2 "STPA" 3 "EFA" 4 "ETS" 5 "PT" 6 "DFA" 7 "SPPA" 8 "SF" 9 "CT" 15 "SNA" ;
VAL_ 471 Hyb_EngStrtStopType 0 "No Action" 1 "Hybrid Torque Start" 2 "Engine Torque Start" 3 "Low Power Start" 4 "Green Engine Start" 5 "Generic Torque Start" 6 "Smooth Autostart" 7 "Normal Autostart" 8 "Aggressive Autostart" 9 "Generic Autostart" 10 "Compression Test" 11 "Controlled Stop" 12 "Immediate Stop" 13 "Reverse Autostart" 14 "Reserved" 15 "SNA" ;
VAL_ 471 InputSpdRaw 4095 "SNA" ;
VAL_ 769 BFC_Allowedstate 0 "Base" 1 "EVA" 3 "SNA" ;
VAL_ 769 BatCoolingFaultSts 0 "No_fault" 1 "BCP_performance_fault" 2 "Chiller_valve_shut_closed" 3 "Compressor_performance_fault" 4 "Compressor_loss_of_comm" 5 "Press_sensor_performance_fault" 6 "Press_sensor_short_to_low" 7 "Press_sensor_short_to_high" 15 "SNA" ;
VAL_ 769 ClrLgsDiagInfo 0 "FALSE" 1 "TRUE" ;
VAL_ 769 ElectricTrqMult4Pedal 255 "SNA" ;
VAL_ 769 HCPMaxEngRPM 255 "SNA" ;
VAL_ 769 HCP_MaxCoolingSt 0 "Normal" 1 "Maximum" 3 "SNA" ;
VAL_ 769 IdleCLoopTrq 1023 "SNA" ;
VAL_ 720 CRC_MotorB_Status 255 "SNA" ;
VAL_ 926 NET_CFG_STAT_ePT 0 "NA" 1 "PROGRAMMED" 2 "REQUEST_DATA" 3 "SNA" ;
VAL_ 926 NetCfg_BSMO_ePT 0 "Not_Present" 1 "Present" ;
VAL_ 777 Charge_Current 1023 "SNA" ;
VAL_ 777 ChrgCurrAvail 1023 "SNA" ;
VAL_ 777 EVSE_PilotStat 0 "NO_EVSE" 1 "CP_DET" 2 "VOOR" 3 "EVSE_NO_AC" 4 "HW_FAULT" 5 "EVSE_FAULT" ;
VAL_ 777 J1772Stat 0 "STATE_A" 1 "STATE_B" 2 "STATE_C" 3 "STATE_D" 4 "STATE_E" 5 "STATE_F" 7 "SNA" ;
VAL_ 777 J1772_ICA 511 "SNA" ;
VAL_ 777 OBCM_DeratingRsn 0 "No_Derating" 1 "High_Temp_Derating" 2 "Low_Temp_Derating" 3 "Input_Voltage_Limit" 4 "Input_Current_Limit" 5 "Output_Voltage_Limit" 6 "Output_Current_Limit" 7 "Internal_Fault_Derating" ;
VAL_ 777 ProxStat 0 "PROX_LO" 1 "Prox_Out" 2 "Prox_In" 3 "Prox_Un" 6 "VOOR" 7 "PROX_HI" ;
VAL_ 277 OBCM_CalChar 255 "SNA" ;
VAL_ 277 OBCM_Cal_ID_Idx 63 "SNA" ;
VAL_ 277 OBCM_DTC_Idx1 0 "SNA" ;
VAL_ 277 OBCM_DTC_Idx2 0 "SNA" ;
VAL_ 277 OBCM_DTC_Stat1 0 "Not_supported" 1 "Critically_disabled" 2 "No_status_to_report" 3 "Diagnostic_passed" 4 "Diagnostic_failed" 5 "Reset_DTC_status" 7 "SNA" ;
VAL_ 277 OBCM_DTC_Stat2 0 "Not_supported" 1 "Critically_disabled" 2 "No_status_to_report" 3 "Diagnostic_passed" 4 "Diagnostic_failed" 5 "Reset_DTC_status" 7 "SNA" ;
VAL_ 976 ChrgFailSts 0 "No_Fault" 1 "Flt_charging_allowed" 2 "Flt_charging_inhibited" 3 "Flt_charging_terminated" 7 "SNA" ;
VAL_ 976 OBCM_Charger_Ready 0 "WU_FLT" 1 "OFF" 2 "ON" 3 "SNA" ;
VAL_ 976 OBCM_FaultRsn 0 "No_Fault" 1 "COMM_FAULT" 2 "EVSE_InputCirFault" 3 "Batt_12vFault" 4 "OBCM_LV_Fault" 5 "OBCM_HV_Fault" 6 "Extern_Dev_Fault" 7 "WakeupCircuitFault" 8 "Impact" 127 "SNA" ;
VAL_ 976 OBCM_WU_Reason 0 "NOT_DETECTED" 1 "Master_WU" 2 "EVSE_PlugIn" 3 "Pilot_PWM" 4 "Prox_in" 5 "EVSE_UnPlug" 6 "s3_open" 7 "BPCM_WU" ;
VAL_ 976 OBC_Md 0 "IDLE" 1 "HEATER" 2 "CHARGE" 3 "AC_PNL" 4 "AC_GRD" 5 "UTC" 6 "STOP" 7 "FORCED_SHUTDOWN" ;
VAL_ 976 WHrAC 65535 "SNA" ;
VAL_ 976 WHrChrg 65535 "SNA" ;
VAL_ 776 ACSideCurr 1023 "SNA" ;
VAL_ 776 ACSideVolt 4095 "SNA" ;
VAL_ 776 BattSideCurr 1023 "SNA" ;
VAL_ 776 BattSideVolt 4095 "SNA" ;
VAL_ 979 NTC1_OT 0 "FALSE" 1 "TRUE" ;
VAL_ 979 NTC2_OT 0 "FALSE" 1 "TRUE" ;
VAL_ 979 NTC3_OT 0 "FALSE" 1 "TRUE" ;
VAL_ 979 NTC4_OT 0 "FALSE" 1 "TRUE" ;
VAL_ 979 OBCMTemp1 255 "SNA" ;
VAL_ 979 OBCMTemp2 255 "SNA" ;
VAL_ 979 OBCMTemp3 255 "SNA" ;
VAL_ 979 OBCMTemp4 255 "SNA" ;
VAL_ 980 OBC_ChrgTm 65535 "SNA" ;
VAL_ 980 OBC_ChrgTmL 65535 "SNA" ;
VAL_ 980 OBC_IdleTm 65535 "SNA" ;
VAL_ 980 OBC_IdleTmL 65535 "SNA" ;
VAL_ 787 BFC_Actualstate 0 "OFF" 1 "ON" 3 "SNA" ;
VAL_ 787 SDS_ActualCoolantTemp 255 "SNA" ;
VAL_ 787 SDS_AverageHVPwr 255 "SNA" ;
VAL_ 787 SDS_CoolantTempTarget 63 "SNA" ;
VAL_ 787 SDS_MaxCoolingReq 0 "Normal" 1 "Use_maximum" 3 "SNA" ;
VAL_ 272 CommndTotBrkFricTorq 16383 "SNA" ;
VAL_ 272 DrvIntndTotBrkTorq 16383 "SNA" ;
VAL_ 272 RegenBrkAxTorqReqst 4095 "SNA" ;
VAL_ 274 EstRegenBrkAxTorq 4095 "SNA" ;
VAL_ 274 RegenBrkAxTorqCap 4095 "SNA" ;
VAL_ 528 APCM_Stat_DPT 0 "OFF" 1 "ON" 2 "PENDING" 3 "SNA" ;
VAL_ 528 DrvRqShftROT_DPT 0 "INIT" 1 "PARK" 2 "REV" 3 "NEUT" 4 "DRIVE" 5 "FIFTH" 7 "SNA" ;
VAL_ 298 LongAcceleration 4095 "SNA" ;
VAL_ 298 VEH_SPEED 65535 "SNA" ;
VAL_ 698 CaptEnvData_OBCM 1 "SNA" ;
VAL_ 698 DTC_OBCM 65535 "SNA" ;
VAL_ 698 D_ES_OBCM 0 "Error_Active" 1 "Error_Passive" 2 "Bussoff" 3 "SNA" ;
VAL_ 698 EVSer_Flash_OBCM 0 "SNA" ;
VAL_ 698 EVSer_On_OBCM 0 "SNA" ;
VAL_ 992 VIN_MSG 0 "VIN_LO" 1 "VIN_MID" 2 "VIN_HI" 3 "SNA" ;
VAL_ 1023 VC_BODY_STYLE 0 "BODY_NONE" 1 "BODY_4DS" 2 "BODY_2DS" 3 "BODY_CONV" 4 "BODY_WAGON" 5 "BODY_4DH" 6 "BODY_2DP" 7 "BODY_4DP" 8 "BODY_4DMP" 15 "BODY_SNA" ;
VAL_ 1023 VC_COUNTRY 0 "ROW" 2 "USA" 3 "EU" 4 "CND" 5 "GB" 6 "JPN" 7 "GER" 8 "SWISS" 9 "MLY" 10 "AUS" 11 "IND" 12 "GULF" 13 "VEN" 14 "MEX" 15 "BRZ" 16 "CHINA" 17 "EGYPT" 20 "S_KOR" 21 "ECE" 31 "COUNTRY_SNA" ;
VAL_ 1023 VC_MODEL_YEAR 63 "SNA" ;
VAL_ 1023 VC_VEH_LINE 0 "VEH_NONE" 1 "VEH_WK" 2 "VEH_LX" 22 "VEH_JC" 29 "VEH_DS" 31 "VEH_D2" 32 "VEH_DD" 33 "VEH_DP" 34 "VEH_DJ" 35 "VEH_WD" 39 "VEH_DX" 41 "VEH_LD" 42 "VEH_M156" 43 "VEH_ZD" 44 "VEH_LA" 45 "VEH_RU" 46 "VEH_M161" 47 "VEH_WS" 48 "VEH_DF" 49 "VEH_JL" 50 "VEH_M157" 51 "VEH_RA" 52 "VEH_WL" 53 "VEH_DT" 54 "VEH_DU" 80 "VEH_PF" 81 "VEH_KL" 82 "VEH_UF" 83 "VEH_UT" 255 "SNA" ;
VAL_ 1023 VC_VehCfg1_Stat 0 "NA" 1 "PROGAMMED" 2 "REQUEST_DATA" 3 "SNA" ;
